VERSION ""

NS_ :

BS_:

BU_:

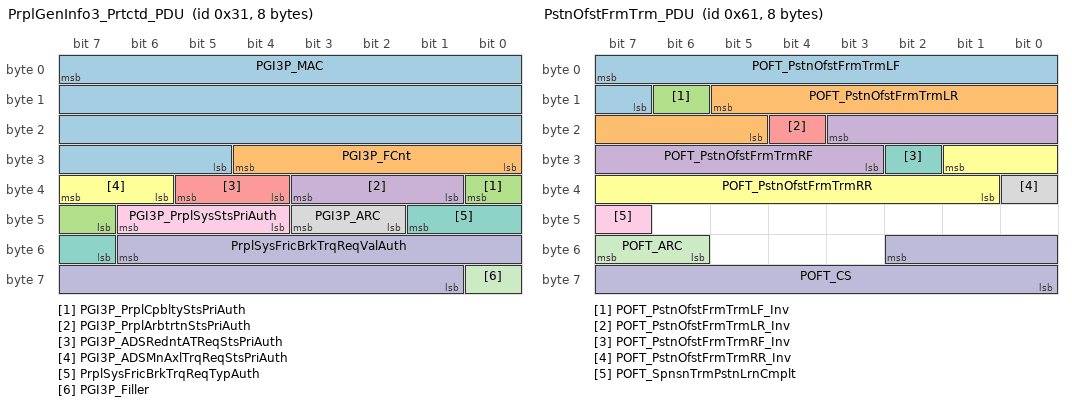
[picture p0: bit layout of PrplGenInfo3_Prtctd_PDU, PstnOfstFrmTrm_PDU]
BO_ 49 PrplGenInfo3_Prtctd_PDU: 8 Vector__XXX
 SG_ PGI3P_MAC : 7|27@0+ (1,0) [0|1.34218e+008] "" ADIMa,ADIMb,EBCM
 SG_ PGI3P_FCnt : 28|5@0+ (1,0) [0|31] "" ADIMa,ADIMb,EBCM
 SG_ PGI3P_PrplCpbltyStsPriAuth : 32|2@0+ (1,0) [0|3] "" ADIMa,ADIMb,EBCM
 SG_ PGI3P_PrplArbtrtnStsPriAuth : 35|3@0+ (1,0) [0|3] "" ADIMa,ADIMb,EBCM
 SG_ PGI3P_ADSRedntATReqStsPriAuth : 37|2@0+ (1,0) [0|3] "" ADIMa,ADIMb,EBCM
 SG_ PGI3P_ADSMnAxlTrqReqStsPriAuth : 39|2@0+ (1,0) [0|3] "" ADIMa,ADIMb,EBCM
 SG_ PrplSysFricBrkTrqReqTypAuth : 41|3@0+ (1,0) [0|3] "" ADIMa,ADIMb,EBCM
 SG_ PGI3P_ARC : 43|2@0+ (1,0) [0|3] "" ADIMa,ADIMb,EBCM
 SG_ PGI3P_PrplSysStsPriAuth : 46|3@0+ (1,0) [0|6] "" ADIMa,ADIMb,EBCM
 SG_ PrplSysFricBrkTrqReqValAuth : 54|14@0+ (2,-22534) [-22534|10232] "Nm" ADIMa,ADIMb,EBCM
 SG_ PGI3P_Filler : 56|1@0+ (1,0) [0|1] "" ADIMa,ADIMb,EBCM

BO_ 1381 PstClsnInfo_PCSM_PDU: 8 Vector__XXX
 SG_ PstClsnInfo_PCSM : 7|64@0+ (1,0) [0|1.84467e+019] "" BSM,BSM_MH,ECM,ECP_MC,FCM,PCM,ECP_X1

BO_ 1320 PstClsnInfo_Prtctd_PDU: 8 Vector__XXX
 SG_ PCIP_MAC : 7|27@0+ (1,0) [0|1.34218e+008] "" BSM,BSM_MH,ECM,ECP_MC,FCM,PCM,ECP_X1
 SG_ PCIP_FCnt : 28|5@0+ (1,0) [0|31] "" BSM,BSM_MH,ECM,ECP_MC,FCM,PCM,ECP_X1
 SG_ PCIP_HzrdLgtsOnReqdAuth : 32|1@0+ (1,0) [0|1] "" BSM,BSM_MH,ECM,ECP_MC,FCM,PCM,ECP_X1
 SG_ PCIP_HybVehHiVltgDsblReqdAuth : 33|1@0+ (1,0) [0|1] "" BSM,BSM_MH,ECM,ECP_MC,FCM,PCM,ECP_X1
 SG_ PCIP_HVCrshImpSnsSysDsbldAuth : 34|1@0+ (1,0) [0|1] "" BSM,BSM_MH,ECM,ECP_MC,FCM,PCM,ECP_X1
 SG_ PCIP_HVACBlwDsblReqdAuth : 35|1@0+ (1,0) [0|1] "" BSM,BSM_MH,ECM,ECP_MC,FCM,PCM,ECP_X1
 SG_ PCIP_FuelCutOffReqdAuth : 36|1@0+ (1,0) [0|1] "" BSM,BSM_MH,ECM,ECP_MC,FCM,PCM,ECP_X1
 SG_ PCIP_DrUnlckReqdAuth : 37|1@0+ (1,0) [0|1] "" BSM,BSM_MH,ECM,ECP_MC,FCM,PCM,ECP_X1
 SG_ PCIP_CruzCtlDsblReqdAuth : 38|1@0+ (1,0) [0|1] "" BSM,BSM_MH,ECM,ECP_MC,FCM,PCM,ECP_X1
 SG_ PCIP_BrkActReqdAuth : 39|1@0+ (1,0) [0|1] "" BSM,BSM_MH,ECM,ECP_MC,FCM,PCM,ECP_X1
 SG_ PCIP_NtfnEvntCntAuth : 44|8@0+ (1,0) [0|255] "" BSM,BSM_MH,ECM,ECP_MC,FCM,PCM,ECP_X1
 SG_ PCIP_NftnFrtImpPrtnsrSevAchAuth : 45|1@0+ (1,0) [0|1] "" BSM,BSM_MH,ECM,ECP_MC,FCM,PCM,ECP_X1
 SG_ PCIP_MemStRclDsblReqdAuth : 46|1@0+ (1,0) [0|1] "" BSM,BSM_MH,ECM,ECP_MC,FCM,PCM,ECP_X1
 SG_ PCIP_IntrLgtOnReqdAuth : 47|1@0+ (1,0) [0|1] "" BSM,BSM_MH,ECM,ECP_MC,FCM,PCM,ECP_X1
 SG_ PCIP_NtfnLtSdSevAchvdAuth : 48|1@0+ (1,0) [0|1] "" BSM,BSM_MH,ECM,ECP_MC,FCM,PCM,ECP_X1
 SG_ PCIP_NtfnFrtImpStg2SevAchvdAuth : 49|1@0+ (1,0) [0|1] "" BSM,BSM_MH,ECM,ECP_MC,FCM,PCM,ECP_X1
 SG_ PCIP_NtfnFrtImpStg1SevAchvdAuth : 50|1@0+ (1,0) [0|1] "" BSM,BSM_MH,ECM,ECP_MC,FCM,PCM,ECP_X1
 SG_ PCIP_NtfnEvntStsAuth : 52|2@0+ (1,0) [0|2] "" BSM,BSM_MH,ECM,ECP_MC,FCM,LIB1,PCM,ECP_X1
 SG_ PCIP_Filler : 56|1@0+ (1,0) [0|1] "" BSM,BSM_MH,ECM,ECP_MC,FCM,PCM,ECP_X1
 SG_ PCIP_ARC : 58|2@0+ (1,0) [0|3] "" BSM,BSM_MH,ECM,ECP_MC,FCM,PCM,ECP_X1
 SG_ PCIP_eCallReqdAuth : 59|1@0+ (1,0) [0|1] "" BSM,BSM_MH,ECM,ECP_MC,FCM,PCM,ECP_X1
 SG_ PCIP_NtfnRtSdSevAchvdAuth : 60|1@0+ (1,0) [0|1] "" BSM,BSM_MH,ECM,ECP_MC,FCM,PCM,ECP_X1
 SG_ PCIP_NtfnRrImpSevAchvdAuth : 61|1@0+ (1,0) [0|1] "" BSM,BSM_MH,ECM,ECP_MC,FCM,PCM,ECP_X1
 SG_ PCIP_NtfnRlOvrSevAchvdAuth : 62|1@0+ (1,0) [0|1] "" BSM,BSM_MH,ECM,ECP_MC,FCM,PCM,ECP_X1
 SG_ PCIP_NtfnPedtrnPrtctnSevAchAuth : 63|1@0+ (1,0) [0|1] "" BSM,BSM_MH,ECM,ECP_MC,FCM,PCM,ECP_X1

BO_ 97 PstnOfstFrmTrm_PDU: 8 Vector__XXX
 SG_ POFT_PstnOfstFrmTrmLF : 7|9@0- (1,0) [-256|255] "mm" ADIMa,ADIMb,AHL_AFL,EPS,EPSb,ECP_E
 SG_ POFT_PstnOfstFrmTrmLR : 13|9@0- (1,0) [-256|255] "mm" ADIMa,ADIMb,AHL_AFL,EPS,EPSb,ECP_E
 SG_ POFT_PstnOfstFrmTrmLF_Inv : 14|1@0+ (1,0) [0|1] "" ADIMa,ADIMb,AHL_AFL,EPS,EPSb,ECP_E
 SG_ POFT_PstnOfstFrmTrmRF : 19|9@0- (1,0) [-256|255] "mm" ADIMa,ADIMb,AHL_AFL,EPS,EPSb,ECP_E
 SG_ POFT_PstnOfstFrmTrmLR_Inv : 20|1@0+ (1,0) [0|1] "" ADIMa,ADIMb,AHL_AFL,EPS,EPSb,ECP_E
 SG_ POFT_PstnOfstFrmTrmRR : 25|9@0- (1,0) [-256|255] "mm" ADIMa,ADIMb,AHL_AFL,EPS,EPSb,ECP_E
 SG_ POFT_PstnOfstFrmTrmRF_Inv : 26|1@0+ (1,0) [0|1] "" ADIMa,ADIMb,AHL_AFL,EPS,EPSb,ECP_E
 SG_ POFT_PstnOfstFrmTrmRR_Inv : 32|1@0+ (1,0) [0|1] "" ADIMa,ADIMb,AHL_AFL,EPS,EPSb,ECP_E
 SG_ POFT_SpnsnTrmPstnLrnCmplt : 47|1@0+ (1,0) [0|1] "" ADIMa,ADIMb,AHL_AFL,EPS,EPSb,ECP_E
 SG_ POFT_CS : 50|11@0+ (1,0) [0|2047] "" ADIMa,ADIMb,EPS,EPSb,ECP_E
 SG_ POFT_ARC : 55|2@0+ (1,0) [0|3] "" ADIMa,ADIMb,EPS,EPSb,ECP_E

BO_ 1399 PwrStrgInfo_PCSM_PDU: 8 Vector__XXX
 SG_ PwrStrgInfo_PCSM : 7|64@0+ (1,0) [0|1.84467e+019] "" Vector__XXX

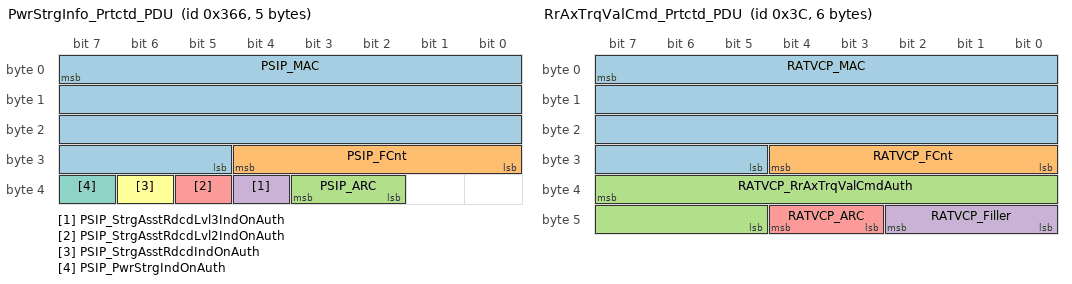
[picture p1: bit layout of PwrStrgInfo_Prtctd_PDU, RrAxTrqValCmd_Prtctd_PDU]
BO_ 870 PwrStrgInfo_Prtctd_PDU: 5 Vector__XXX
 SG_ PSIP_MAC : 7|27@0+ (1,0) [0|1.34218e+008] "" Vector__XXX
 SG_ PSIP_FCnt : 28|5@0+ (1,0) [0|31] "" Vector__XXX
 SG_ PSIP_ARC : 35|2@0+ (1,0) [0|3] "" Vector__XXX
 SG_ PSIP_StrgAsstRdcdLvl3IndOnAuth : 36|1@0+ (1,0) [0|1] "" Vector__XXX
 SG_ PSIP_StrgAsstRdcdLvl2IndOnAuth : 37|1@0+ (1,0) [0|1] "" Vector__XXX
 SG_ PSIP_StrgAsstRdcdIndOnAuth : 38|1@0+ (1,0) [0|1] "" Vector__XXX
 SG_ PSIP_PwrStrgIndOnAuth : 39|1@0+ (1,0) [0|1] "" Vector__XXX

BO_ 2147745823 Message1039_PDU: 1 Vector__XXX
 SG_ Sig5023 : 7|1@0+ (1,0) [0|1] "" CGM

BO_ 912 RrAxTrqValCmd_PCSM_PDU: 8 Vector__XXX
 SG_ RrAxTrqValCmd_PCSM : 7|64@0+ (1,0) [0|1.84467e+019] "" DCM,PCM,TCM

BO_ 60 RrAxTrqValCmd_Prtctd_PDU: 6 Vector__XXX
 SG_ RATVCP_MAC : 7|27@0+ (1,0) [0|1.34218e+008] "" DCM,PCM,TCM
 SG_ RATVCP_FCnt : 28|5@0+ (1,0) [0|31] "" DCM,PCM,TCM
 SG_ RATVCP_RrAxTrqValCmdAuth : 39|11@0+ (5,-5120) [-5120|5115] "Nm" DCM,PCM,TCM
 SG_ RATVCP_Filler : 42|3@0+ (1,0) [0|7] "" DCM,PCM,TCM
 SG_ RATVCP_ARC : 44|2@0+ (1,0) [0|3] "" DCM,PCM,TCM

BO_ 1380 SecAxlTrqCplRqTy_PCSM_PDU: 8 Vector__XXX
 SG_ SecAxlTrqCplRqTy_PCSM : 7|64@0+ (1,0) [0|1.84467e+019] "" RDCM,TCCM

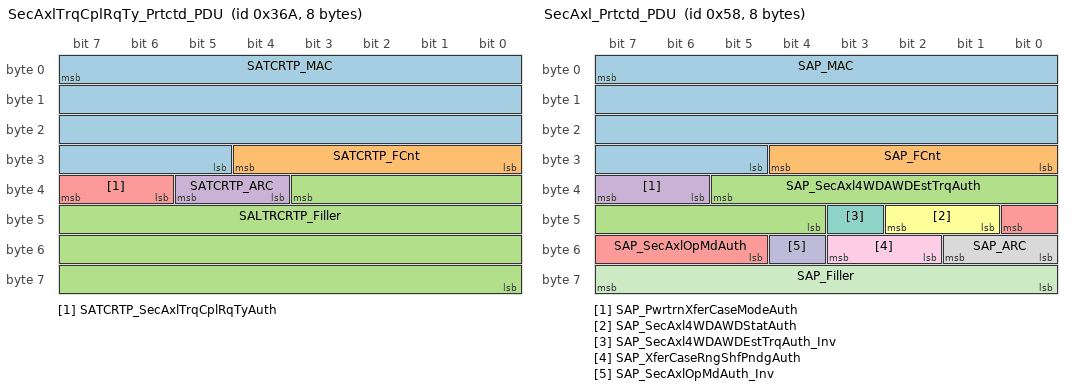
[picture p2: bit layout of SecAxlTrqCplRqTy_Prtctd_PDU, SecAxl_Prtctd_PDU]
BO_ 874 SecAxlTrqCplRqTy_Prtctd_PDU: 8 Vector__XXX
 SG_ SATCRTP_MAC : 7|27@0+ (1,0) [0|1.34218e+008] "" RDCM,TCCM
 SG_ SATCRTP_FCnt : 28|5@0+ (1,0) [0|31] "" RDCM,TCCM
 SG_ SALTRCRTP_Filler : 35|28@0+ (1,0) [0|2.68435e+008] "" RDCM,TCCM
 SG_ SATCRTP_ARC : 37|2@0+ (1,0) [0|3] "" RDCM,TCCM
 SG_ SATCRTP_SecAxlTrqCplRqTyAuth : 39|2@0+ (1,0) [0|3] "" RDCM,TCCM

BO_ 911 SecAxl_PCSM_PDU: 8 Vector__XXX
 SG_ SecAxl_PCSM : 7|64@0+ (1,0) [0|1.84467e+019] "" ACP2_MCU,CGM,EBCM,ECM,EOCM,EOCM_HC_Superset,FCM,PCM

BO_ 88 SecAxl_Prtctd_PDU: 8 Vector__XXX
 SG_ SAP_MAC : 7|27@0+ (1,0) [0|1.34218e+008] "" ACP2_MCU,CGM,EBCM,ECM,EOCM,EOCM_HC_Superset,FCM,PCM
 SG_ SAP_FCnt : 28|5@0+ (1,0) [0|31] "" ACP2_MCU,CGM,EBCM,ECM,EOCM,EOCM_HC_Superset,FCM,PCM
 SG_ SAP_SecAxl4WDAWDEstTrqAuth : 37|10@0+ (10,0) [0|10230] "Nm" ACP2_MCU,ADIMa,ADIMb,CGM,DCM,EBCM,ECM,EOCM,EOCM_HC_Superset,FCM,PCM,ECP_E
 SG_ SAP_PwrtrnXferCaseModeAuth : 39|2@0+ (1,0) [0|3] "" ACP2_MCU,CGM,EBCM,ECM,EOCM,EOCM_HC_Superset,FCM,PCM
 SG_ SAP_SecAxlOpMdAuth : 40|4@0+ (1,0) [0|9] "" ACP2_MCU,ADIMa,ADIMb,CGM,EBCM,ECM,EOCM,EOCM_HC_Superset,FCM,E44,PCM,ECP_E
 SG_ SAP_SecAxl4WDAWDStatAuth : 42|2@0+ (1,0) [0|3] "" ACP2_MCU,ADIMa,ADIMb,CGM,EBCM,ECM,EOCM,EOCM_HC_Superset,FCM,PCM,ECP_E
 SG_ SAP_SecAxl4WDAWDEstTrqAuth_Inv : 43|1@0+ (1,0) [0|1] "" ACP2_MCU,ADIMa,ADIMb,CGM,DCM,EBCM,ECM,EOCM,EOCM_HC_Superset,FCM,PCM,ECP_E
 SG_ SAP_ARC : 49|2@0+ (1,0) [0|3] "" ACP2_MCU,CGM,EBCM,ECM,EOCM,EOCM_HC_Superset,FCM,PCM
 SG_ SAP_XferCaseRngShfPndgAuth : 51|2@0+ (1,0) [0|3] "" ACP2_MCU,CGM,EBCM,ECM,EOCM,EOCM_HC_Superset,FCM,PCM
 SG_ SAP_SecAxlOpMdAuth_Inv : 52|1@0+ (1,0) [0|1] "" ACP2_MCU,ADIMa,ADIMb,CGM,EBCM,ECM,EOCM,EOCM_HC_Superset,FCM,E44,PCM,ECP_E
 SG_ SAP_Filler : 63|8@0+ (1,0) [0|255] "" ACP2_MCU,CGM,EBCM,ECM,EOCM,EOCM_HC_Superset,FCM,PCM

BO_ 1379 SemiAtvDmpgSysVhTpSpdLim_PCSM_PD: 8 Vector__XXX
 SG_ SemiAtvDmpgSysVhTpSpdLim_PCSM : 7|64@0+ (1,0) [0|1.84467e+019] "" ECM,PCM,ECP_E

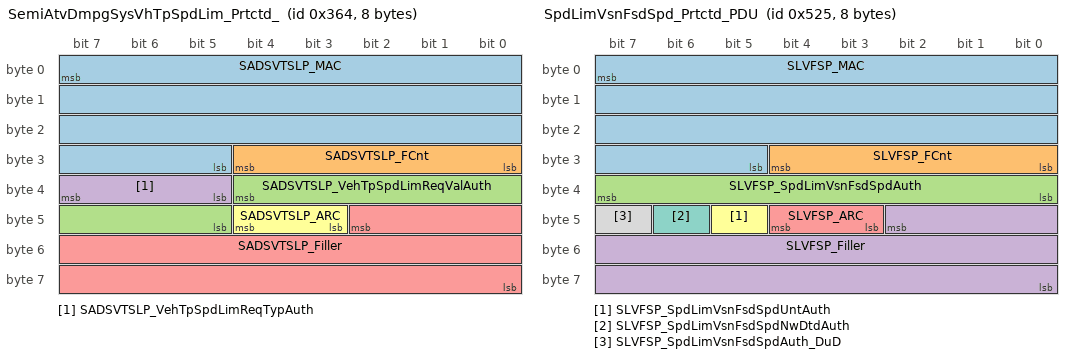
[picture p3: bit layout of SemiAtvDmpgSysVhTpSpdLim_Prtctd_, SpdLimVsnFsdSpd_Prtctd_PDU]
BO_ 868 SemiAtvDmpgSysVhTpSpdLim_Prtctd_: 8 Vector__XXX
 SG_ SADSVTSLP_MAC : 7|27@0+ (1,0) [0|1.34218e+008] "" ECM,PCM,ECP_E
 SG_ SADSVTSLP_FCnt : 28|5@0+ (1,0) [0|31] "" ECM,PCM,ECP_E
 SG_ SADSVTSLP_VehTpSpdLimReqValAuth : 36|8@0+ (2,0) [0|510] "kph" ECM,PCM,ECP_E
 SG_ SADSVTSLP_VehTpSpdLimReqTypAuth : 39|3@0+ (1,0) [0|6] "" ECM,PCM,ECP_E
 SG_ SADSVTSLP_Filler : 42|19@0+ (1,0) [0|524287] "" ECM,PCM,ECP_E
 SG_ SADSVTSLP_ARC : 44|2@0+ (1,0) [0|3] "" ECM,PCM,ECP_E

BO_ 1317 SpdLimVsnFsdSpd_Prtctd_PDU: 8 Vector__XXX
 SG_ SLVFSP_MAC : 7|27@0+ (1,0) [0|1.34218e+008] "" Vector__XXX
 SG_ SLVFSP_FCnt : 28|5@0+ (1,0) [0|31] "" Vector__XXX
 SG_ SLVFSP_SpdLimVsnFsdSpdAuth : 39|8@0+ (1,0) [0|255] "" CGM,ECM,PCM,ECP_E
 SG_ SLVFSP_Filler : 42|19@0+ (1,0) [0|524287] "" Vector__XXX
 SG_ SLVFSP_ARC : 44|2@0+ (1,0) [0|3] "" Vector__XXX
 SG_ SLVFSP_SpdLimVsnFsdSpdUntAuth : 45|1@0+ (1,0) [0|1] "" CGM,ECM,PCM,ECP_E
 SG_ SLVFSP_SpdLimVsnFsdSpdNwDtdAuth : 46|1@0+ (1,0) [0|1] "" CGM,ECM,PCM,ECP_E
 SG_ SLVFSP_SpdLimVsnFsdSpdAuth_DuD : 47|1@0+ (1,0) [0|1] "" CGM,ECM,PCM,ECP_E

BO_ 1378 SpnsnGenInfo2_PCSM_PDU: 8 Vector__XXX
 SG_ SpnsnGenInfo2_PCSM : 7|64@0+ (1,0) [0|1.84467e+019] "" FCM

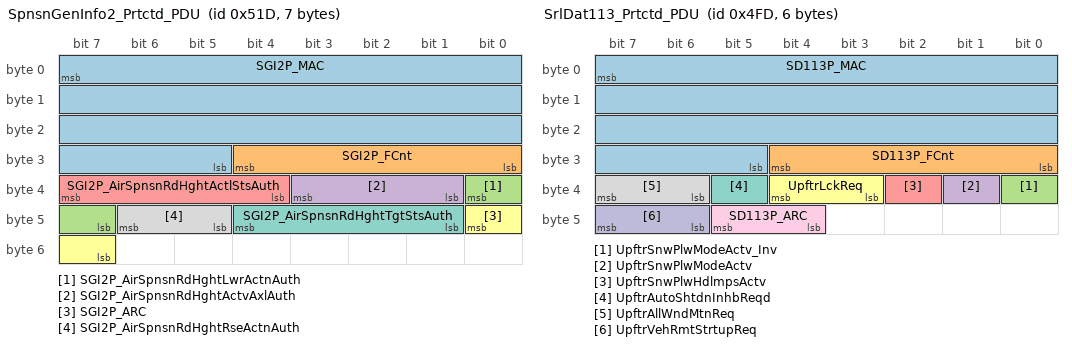
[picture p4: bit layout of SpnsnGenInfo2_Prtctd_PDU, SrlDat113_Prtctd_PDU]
BO_ 1309 SpnsnGenInfo2_Prtctd_PDU: 7 Vector__XXX
 SG_ SGI2P_MAC : 7|27@0+ (1,0) [0|1.34218e+008] "" FCM
 SG_ SGI2P_FCnt : 28|5@0+ (1,0) [0|31] "" FCM
 SG_ SGI2P_AirSpnsnRdHghtLwrActnAuth : 32|2@0+ (1,0) [0|3] "" FCM
 SG_ SGI2P_AirSpnsnRdHghtActvAxlAuth : 35|3@0+ (1,0) [0|4] "" FCM
 SG_ SGI2P_AirSpnsnRdHghtActlStsAuth : 39|4@0+ (1,0) [0|9] "" FCM,E44
 SG_ SGI2P_ARC : 40|2@0+ (1,0) [0|3] "" FCM
 SG_ SGI2P_AirSpnsnRdHghtTgtStsAuth : 44|4@0+ (1,0) [0|9] "" FCM,E44
 SG_ SGI2P_AirSpnsnRdHghtRseActnAuth : 46|2@0+ (1,0) [0|3] "" FCM

BO_ 1327 SrlDat113_PCSM_PDU: 8 Vector__XXX
 SG_ SrlDat113_PCSM : 7|64@0+ (1,0) [0|1.84467e+019] "" ACP2_MCU,ECM,EOCM,EOCM_HC_Superset,FCM

BO_ 1277 SrlDat113_Prtctd_PDU: 6 Vector__XXX
 SG_ SD113P_MAC : 7|27@0+ (1,0) [0|1.34218e+008] "" ACP2_MCU,ECM,EOCM,EOCM_HC_Superset,FCM
 SG_ SD113P_FCnt : 28|5@0+ (1,0) [0|31] "" ACP2_MCU,ECM,EOCM,EOCM_HC_Superset,FCM
 SG_ UpftrSnwPlwModeActv_Inv : 32|1@0+ (1,0) [0|1] "" ACP2_MCU,ECM,EOCM,EOCM_HC_Superset,FCM
 SG_ UpftrSnwPlwModeActv : 33|1@0+ (1,0) [0|1] "" ACP2_MCU,ECM,EOCM,EOCM_HC_Superset,FCM
 SG_ UpftrSnwPlwHdlmpsActv : 34|1@0+ (1,0) [0|1] "" ACP2_MCU,ECM,EOCM,EOCM_HC_Superset,FCM
 SG_ UpftrLckReq : 36|2@0+ (1,0) [0|2] "" ACP2_MCU,ECM,EOCM,EOCM_HC_Superset,FCM
 SG_ UpftrAutoShtdnInhbReqd : 37|1@0+ (1,0) [0|1] "" ACP2_MCU,ECM,EOCM,EOCM_HC_Superset,FCM
 SG_ UpftrAllWndMtnReq : 39|2@0+ (1,0) [0|3] "" ACP2_MCU,ECM,EOCM,EOCM_HC_Superset,FCM
 SG_ SD113P_ARC : 45|2@0+ (1,0) [0|3] "" ACP2_MCU,ECM,EOCM,EOCM_HC_Superset,FCM
 SG_ UpftrVehRmtStrtupReq : 47|2@0+ (1,0) [0|2] "" ACP2_MCU,ECM,EOCM,EOCM_HC_Superset,FCM

BO_ 910 SrlDat11_PCSM_PDU: 8 Vector__XXX
 SG_ SrlDat11_PCSM : 7|64@0+ (1,0) [0|1.84467e+019] "" ECP_E,ECP_S,ECP_S2,ECP_X1

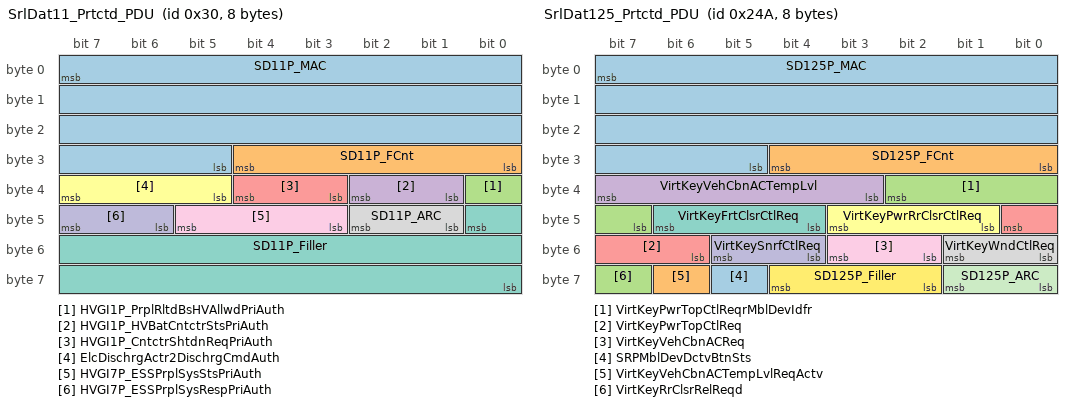
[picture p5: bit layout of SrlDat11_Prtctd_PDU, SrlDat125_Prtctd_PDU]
BO_ 48 SrlDat11_Prtctd_PDU: 8 Vector__XXX
 SG_ SD11P_MAC : 7|27@0+ (1,0) [0|1.34218e+008] "" ECP_E,ECP_S,ECP_S2,ECP_X1
 SG_ SD11P_FCnt : 28|5@0+ (1,0) [0|31] "" ECP_E,ECP_S,ECP_S2,ECP_X1
 SG_ HVGI1P_PrplRltdBsHVAllwdPriAuth : 32|1@0+ (1,0) [0|1] "" ECP_E,ECP_S,ECP_S2,ECP_X1
 SG_ HVGI1P_HVBatCntctrStsPriAuth : 34|2@0+ (1,0) [0|2] "" ECP_E,ECP_S,ECP_S2,ECP_X1
 SG_ HVGI1P_CntctrShtdnReqPriAuth : 36|2@0+ (1,0) [0|3] "" VDM,ECP_E,ECP_S,ECP_S2,ECP_X1
 SG_ ElcDischrgActr2DischrgCmdAuth : 39|3@0+ (1,0) [0|3] "" ECP_E,ECP_S,ECP_S2,ECP_X1
 SG_ SD11P_Filler : 40|17@0+ (1,0) [0|131071] "" ECP_E,ECP_S,ECP_S2,ECP_X1
 SG_ SD11P_ARC : 42|2@0+ (1,0) [0|3] "" ECP_E,ECP_S,ECP_S2,ECP_X1
 SG_ HVGI7P_ESSPrplSysStsPriAuth : 45|3@0+ (1,0) [0|5] "" ECP_E,ECP_S,ECP_S2,ECP_X1
 SG_ HVGI7P_ESSPrplSysRespPriAuth : 47|2@0+ (1,0) [0|3] "" ECP_E,ECP_S,ECP_S2,ECP_X1

BO_ 1152 SrlDat124_PCSM_PDU: 8 Vector__XXX
 SG_ SrlDat124_PCSM : 7|64@0+ (1,0) [0|1.84467e+019] "" ACP2_MCU,EOCM,EOCM_HC_Superset

BO_ 1149 SrlDat124_Prtctd_PDU: 8 Vector__XXX
 SG_ SD124P_MAC : 7|27@0+ (1,0) [0|1.34218e+008] "" ACP2_MCU,EOCM,EOCM_HC_Superset
 SG_ SD124P_FCnt : 28|5@0+ (1,0) [0|31] "" ACP2_MCU,EOCM,EOCM_HC_Superset
 SG_ VirtKeyAllDrLckReqd : 32|1@0+ (1,0) [0|1] "" ACP2_MCU,EOCM,EOCM_HC_Superset
 SG_ VirtKeyPncReq : 34|2@0+ (1,0) [0|2] "" ACP2_MCU,EOCM,EOCM_HC_Superset
 SG_ VirtKeyFobAvlReq : 36|2@0+ (1,0) [0|2] "" ACP2_MCU,EOCM,EOCM_HC_Superset
 SG_ VirtKeyRmtLctrReq : 39|3@0+ (1,0) [0|4] "" ACP2_MCU,EOCM,EOCM_HC_Superset
 SG_ SRPCrsFrtInSftBtnMblDevSts : 40|1@0+ (1,0) [0|1] "" ACP2_MCU,EOCM,EOCM_HC_Superset
 SG_ SRPCrsBkInSftBtnMblDevSts : 41|1@0+ (1,0) [0|1] "" ACP2_MCU,EOCM,EOCM_HC_Superset
 SG_ VirtKeyRrClsrUnlckReqd : 42|1@0+ (1,0) [0|1] "" ACP2_MCU,EOCM,EOCM_HC_Superset
 SG_ VirtKeyRrClsrLckReqd : 43|1@0+ (1,0) [0|1] "" ACP2_MCU,EOCM,EOCM_HC_Superset
 SG_ VirtKeyFrtClsrUnlckReqd : 44|1@0+ (1,0) [0|1] "" ACP2_MCU,EOCM,EOCM_HC_Superset
 SG_ VirtKeyFrtClsrLckReqd : 45|1@0+ (1,0) [0|1] "" ACP2_MCU,EOCM,EOCM_HC_Superset
 SG_ VirtKeyDrvrDrUnlckReqd : 46|1@0+ (1,0) [0|1] "" ACP2_MCU,EOCM,EOCM_HC_Superset
 SG_ VirtKeyAllDrUnlckReqd : 47|1@0+ (1,0) [0|1] "" ACP2_MCU,EOCM,EOCM_HC_Superset
 SG_ SD124P_Filler : 50|9@0+ (1,0) [0|511] "" ACP2_MCU,EOCM,EOCM_HC_Superset
 SG_ SRPSrchingSftBtnMblDevSts : 51|1@0+ (1,0) [0|1] "" ACP2_MCU,EOCM,EOCM_HC_Superset
 SG_ SRPRtSftBtnMblDevSts : 52|1@0+ (1,0) [0|1] "" ACP2_MCU,EOCM,EOCM_HC_Superset
 SG_ SRPPrlllPrkSftBtnMblDevSts : 53|1@0+ (1,0) [0|1] "" ACP2_MCU,EOCM,EOCM_HC_Superset
 SG_ SRPLtSftBtnMblDevSts : 54|1@0+ (1,0) [0|1] "" ACP2_MCU,EOCM,EOCM_HC_Superset
 SG_ SRPExtPrkSftBtnMblDevSts : 55|1@0+ (1,0) [0|1] "" ACP2_MCU,EOCM,EOCM_HC_Superset
 SG_ SD124P_ARC : 57|2@0+ (1,0) [0|3] "" ACP2_MCU,EOCM,EOCM_HC_Superset

BO_ 972 SrlDat125_PCSM_PDU: 8 Vector__XXX
 SG_ SrlDat125_PCSM : 7|64@0+ (1,0) [0|1.84467e+019] "" ACP2_MCU,EOCM,EOCM_HC_Superset

BO_ 586 SrlDat125_Prtctd_PDU: 8 Vector__XXX
 SG_ SD125P_MAC : 7|27@0+ (1,0) [0|1.34218e+008] "" ACP2_MCU,EOCM,EOCM_HC_Superset
 SG_ SD125P_FCnt : 28|5@0+ (1,0) [0|31] "" ACP2_MCU,EOCM,EOCM_HC_Superset
 SG_ VirtKeyPwrTopCtlReqrMblDevIdfr : 34|4@0+ (1,0) [0|15] "" ACP2_MCU,EOCM,EOCM_HC_Superset
 SG_ VirtKeyVehCbnACTempLvl : 39|5@0+ (0.5,16) [16|31.5] "Deg C" ACP2_MCU,EOCM,EOCM_HC_Superset
 SG_ VirtKeyPwrTopCtlReq : 40|3@0+ (1,0) [0|4] "" ACP2_MCU,EOCM,EOCM_HC_Superset
 SG_ VirtKeyPwrRrClsrCtlReq : 43|3@0+ (1,0) [0|4] "" ACP2_MCU,EOCM,EOCM_HC_Superset
 SG_ VirtKeyFrtClsrCtlReq : 46|3@0+ (1,0) [0|5] "" ACP2_MCU,EOCM,EOCM_HC_Superset
 SG_ VirtKeyWndCtlReq : 49|2@0+ (1,0) [0|3] "" ACP2_MCU,EOCM,EOCM_HC_Superset
 SG_ VirtKeyVehCbnACReq : 51|2@0+ (1,0) [0|2] "" ACP2_MCU,EOCM,EOCM_HC_Superset
 SG_ VirtKeySnrfCtlReq : 53|2@0+ (1,0) [0|3] "" ACP2_MCU,EOCM,EOCM_HC_Superset
 SG_ SD125P_ARC : 57|2@0+ (1,0) [0|3] "Counts" ACP2_MCU,EOCM,EOCM_HC_Superset
 SG_ SD125P_Filler : 60|3@0+ (1,0) [0|7] "" ACP2_MCU,EOCM,EOCM_HC_Superset
 SG_ SRPMblDevDctvBtnSts : 61|1@0+ (1,0) [0|1] "" ACP2_MCU,EOCM,EOCM_HC_Superset
 SG_ VirtKeyVehCbnACTempLvlReqActv : 62|1@0+ (1,0) [0|1] "" ACP2_MCU,EOCM,EOCM_HC_Superset
 SG_ VirtKeyRrClsrRelReqd : 63|1@0+ (1,0) [0|1] "" ACP2_MCU,EOCM,EOCM_HC_Superset

BO_ 967 SrlDat133_PCSM_PDU: 8 Vector__XXX
 SG_ SrlDat133_PCSM : 7|64@0+ (1,0) [0|1.84467e+019] "" ECP_E

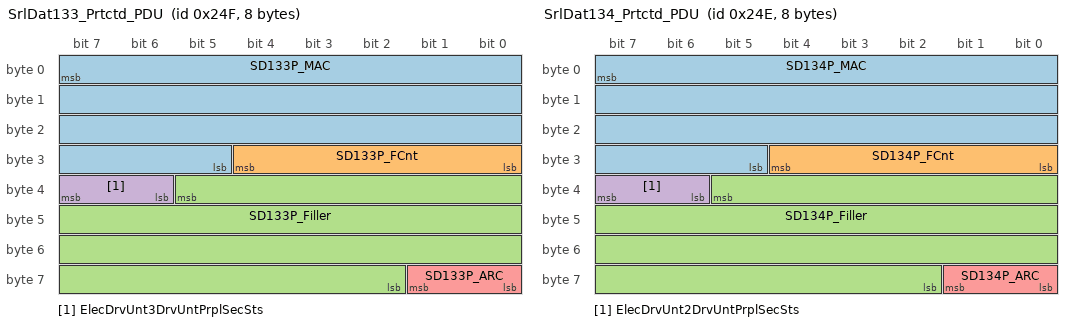
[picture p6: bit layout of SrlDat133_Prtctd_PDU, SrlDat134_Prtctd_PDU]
BO_ 591 SrlDat133_Prtctd_PDU: 8 Vector__XXX
 SG_ SD133P_MAC : 7|27@0+ (1,0) [0|1.34218e+008] "" ECP_E
 SG_ SD133P_FCnt : 28|5@0+ (1,0) [0|31] "" ECP_E
 SG_ SD133P_Filler : 37|28@0+ (1,0) [0|2.68435e+008] "" ECP_E
 SG_ ElecDrvUnt3DrvUntPrplSecSts : 39|2@0+ (1,0) [0|2] "" ECP_E
 SG_ SD133P_ARC : 57|2@0+ (1,0) [0|3] "" ECP_E

BO_ 969 SrlDat134_PCSM_PDU: 8 Vector__XXX
 SG_ SrlDat134_PCSM : 7|64@0+ (1,0) [0|1.84467e+019] "" ECP_E

BO_ 590 SrlDat134_Prtctd_PDU: 8 Vector__XXX
 SG_ SD134P_MAC : 7|27@0+ (1,0) [0|1.34218e+008] "" ECP_E
 SG_ SD134P_FCnt : 28|5@0+ (1,0) [0|31] "" ECP_E
 SG_ SD134P_Filler : 37|28@0+ (1,0) [0|2.68435e+008] "" ECP_E
 SG_ ElecDrvUnt2DrvUntPrplSecSts : 39|2@0+ (1,0) [0|2] "" ECP_E
 SG_ SD134P_ARC : 57|2@0+ (1,0) [0|3] "" ECP_E

BO_ 970 SrlDat135_PCSM_PDU: 8 Vector__XXX
 SG_ SrlDat135_PCSM : 7|64@0+ (1,0) [0|1.84467e+019] "" ECP_S,ECP_S2

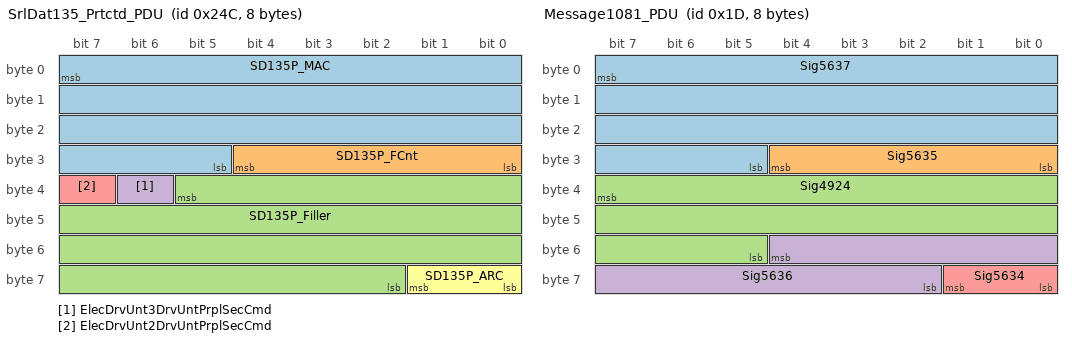
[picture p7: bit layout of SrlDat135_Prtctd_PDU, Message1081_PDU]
BO_ 588 SrlDat135_Prtctd_PDU: 8 Vector__XXX
 SG_ SD135P_MAC : 7|27@0+ (1,0) [0|1.34218e+008] "" ECP_S,ECP_S2
 SG_ SD135P_FCnt : 28|5@0+ (1,0) [0|31] "" ECP_S,ECP_S2
 SG_ SD135P_Filler : 37|28@0+ (1,0) [0|2.68435e+008] "" ECP_S,ECP_S2
 SG_ ElecDrvUnt3DrvUntPrplSecCmd : 38|1@0+ (1,0) [0|1] "" ECP_S,ECP_S2
 SG_ ElecDrvUnt2DrvUntPrplSecCmd : 39|1@0+ (1,0) [0|1] "" ECP_S,ECP_S2
 SG_ SD135P_ARC : 57|2@0+ (1,0) [0|3] "" ECP_S,ECP_S2

BO_ 740 Message1080_PDU: 8 Vector__XXX
 SG_ Sig6844 : 7|64@0+ (1,0) [0|1.84467e+019] "" ECM

BO_ 29 Message1081_PDU: 8 Vector__XXX
 SG_ Sig5637 : 7|27@0+ (1,0) [0|1.34218e+008] "" ECM
 SG_ Sig5635 : 28|5@0+ (1,0) [0|31] "" ECM
 SG_ Sig4924 : 39|19@0- (0.25,0) [-65536|65535.8] "Nm" ECM
 SG_ Sig5636 : 52|11@0+ (1,0) [0|2047] "" ECM
 SG_ Sig5634 : 57|2@0+ (1,0) [0|3] "" ECM

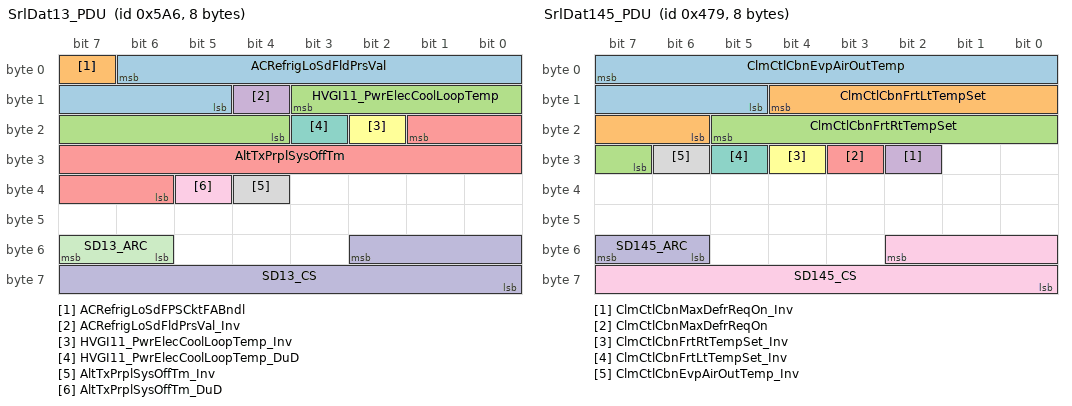
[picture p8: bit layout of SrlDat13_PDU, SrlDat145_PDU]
BO_ 1446 SrlDat13_PDU: 8 Vector__XXX
 SG_ ACRefrigLoSdFldPrsVal : 6|10@0+ (1,0) [0|1023] "KPA" ECM,PCM,ECP_E,ECP_X1
 SG_ ACRefrigLoSdFPSCktFABndl : 7|1@0+ (1,0) [0|1] "" ECM,PCM,ECP_E,ECP_X1
 SG_ HVGI11_PwrElecCoolLoopTemp : 11|8@0+ (1,-40) [-40|215] "Deg C" ECP_E,ECP_X1
 SG_ ACRefrigLoSdFldPrsVal_Inv : 12|1@0+ (1,0) [0|1] "" ECM,PCM,ECP_E,ECP_X1
 SG_ AltTxPrplSysOffTm : 17|12@0+ (0.5,0) [0|2047.5] "min" ECP_E,ECP_X1
 SG_ HVGI11_PwrElecCoolLoopTemp_Inv : 18|1@0+ (1,0) [0|1] "" ECP_E,ECP_X1
 SG_ HVGI11_PwrElecCoolLoopTemp_DuD : 19|1@0+ (1,0) [0|1] "" ECP_E,ECP_X1
 SG_ AltTxPrplSysOffTm_Inv : 36|1@0+ (1,0) [0|1] "" ECP_E,ECP_X1
 SG_ AltTxPrplSysOffTm_DuD : 37|1@0+ (1,0) [0|1] "" ECP_E,ECP_X1
 SG_ SD13_CS : 50|11@0+ (1,0) [0|2047] "" ECP_E,ECP_X1
 SG_ SD13_ARC : 55|2@0+ (1,0) [0|3] "" ECP_E,ECP_X1

BO_ 971 SrlDat141_PCSM_PDU: 8 Vector__XXX
 SG_ SrlDat141_PCSM : 7|64@0+ (1,0) [0|1.84467e+019] "" EBCM,ECM,PCM,ECP_E

BO_ 587 SrlDat141_Prtctd_PDU: 12 Vector__XXX
 SG_ SD141P_MAC : 7|32@0+ (1,0) [0|4.29497e+009] "" EBCM,ECM,PCM,ECP_E
 SG_ SD141P_FCnt : 39|5@0+ (1,0) [0|31] "" EBCM,ECM,PCM,ECP_E
 SG_ SuprRmtPrkPrplSysTrqReq : 47|15@0+ (2,-22534) [-22534|43000] "Nm" EBCM,ECM,PCM,ECP_E
 SG_ SuprRmtPrkBrkTrqReq : 48|14@0+ (2,-22534) [-22534|10232] "Nm" EBCM,ECM,PCM,ECP_E
 SG_ SuprRmtPrkFricBrkTrqReqTyp : 64|2@0+ (1,0) [0|3] "" EBCM,ECM,PCM,ECP_E
 SG_ SuprRmtPrkElecPrkBrkReq : 66|2@0+ (1,0) [0|2] "" EBCM,ECM,PCM,ECP_E
 SG_ SD141P_Filler : 77|20@0+ (1,0) [0|1.04858e+006] "" EBCM,ECM,PCM,ECP_E
 SG_ SuprRmtPrkPrplSysActvnReqd : 78|1@0+ (1,0) [0|1] "" EBCM,ECM,PCM,ECP_E
 SG_ SD141P_ARC : 89|2@0+ (1,0) [0|3] "" EBCM,ECM,PCM,ECP_E

BO_ 1145 SrlDat145_PDU: 8 Vector__XXX
 SG_ ClmCtlCbnEvpAirOutTemp : 7|11@0+ (0.1,-60) [-60|144.7] "Deg C" ECM,PCM
 SG_ ClmCtlCbnFrtLtTempSet : 12|7@0+ (0.5,0) [0|63.5] "Deg C" ECM,PCM
 SG_ ClmCtlCbnFrtRtTempSet : 21|7@0+ (0.5,0) [0|63.5] "Deg C" ECM,PCM
 SG_ ClmCtlCbnMaxDefrReqOn_Inv : 26|1@0+ (1,0) [0|1] "" ECM,PCM
 SG_ ClmCtlCbnMaxDefrReqOn : 27|1@0+ (1,0) [0|1] "" ECM,PCM
 SG_ ClmCtlCbnFrtRtTempSet_Inv : 28|1@0+ (1,0) [0|1] "" ECM,PCM
 SG_ ClmCtlCbnFrtLtTempSet_Inv : 29|1@0+ (1,0) [0|1] "" ECM,PCM
 SG_ ClmCtlCbnEvpAirOutTemp_Inv : 30|1@0+ (1,0) [0|1] "" ECM,PCM
 SG_ SD145_CS : 50|11@0+ (1,0) [0|2047] "" ECM,PCM
 SG_ SD145_ARC : 55|2@0+ (1,0) [0|3] "" ECM,PCM

BO_ 1377 SrlDat14_PCSM_PDU: 8 Vector__XXX
 SG_ SrlDat14_PCSM : 7|64@0+ (1,0) [0|1.84467e+019] "" ACP2_MCU,ARS,VICM,ECM,EOCM,EOCM_HC_Superset,EPS,EPSb,FCM,PCM,RDCM,TCCM,ECP_E

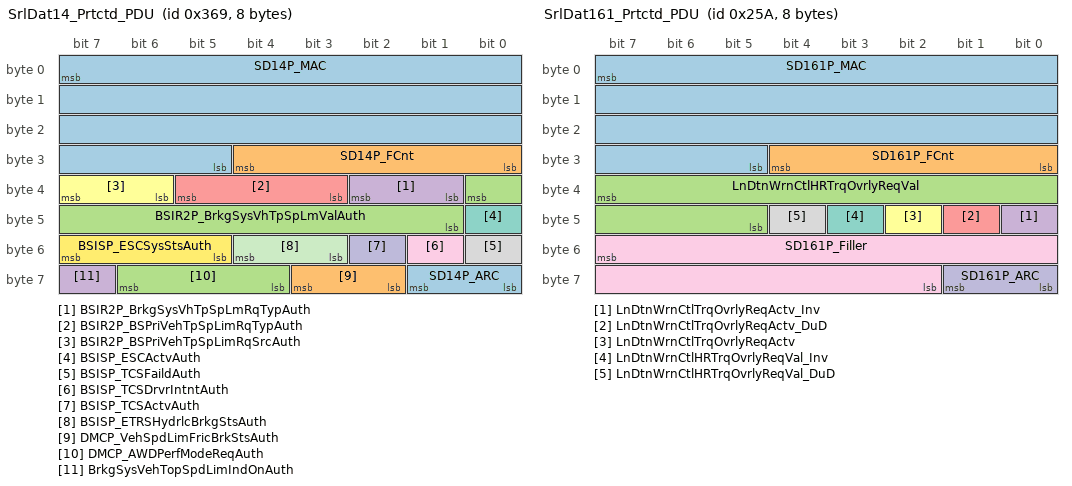
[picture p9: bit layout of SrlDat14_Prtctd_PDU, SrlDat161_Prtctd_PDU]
BO_ 873 SrlDat14_Prtctd_PDU: 8 Vector__XXX
 SG_ SD14P_MAC : 7|27@0+ (1,0) [0|1.34218e+008] "" ACP2_MCU,ARS,VICM,CGM,ECM,EOCM,EOCM_HC_Superset,EPS,EPSb,FCM,PCM,RDCM,TCCM,ECP_E
 SG_ SD14P_FCnt : 28|5@0+ (1,0) [0|31] "" ACP2_MCU,ARS,VICM,CGM,ECM,EOCM,EOCM_HC_Superset,EPS,EPSb,FCM,PCM,RDCM,TCCM,ECP_E
 SG_ BSIR2P_BrkgSysVhTpSpLmValAuth : 32|8@0+ (2,0) [0|510] "kph" ACP2_MCU,ARS,VICM,CGM,ECM,EOCM,EOCM_HC_Superset,EPS,EPSb,FCM,PCM,RDCM,TCCM,ECP_E
 SG_ BSIR2P_BrkgSysVhTpSpLmRqTypAuth : 34|2@0+ (1,0) [0|1] "" ACP2_MCU,ARS,VICM,CGM,ECM,EOCM,EOCM_HC_Superset,EPS,EPSb,FCM,PCM,RDCM,TCCM,ECP_E
 SG_ BSIR2P_BSPriVehTpSpLimRqTypAuth : 37|3@0+ (1,0) [0|6] "" ACP2_MCU,ARS,VICM,CGM,ECM,EOCM,EOCM_HC_Superset,EPS,EPSb,FCM,PCM,RDCM,TCCM,ECP_E
 SG_ BSIR2P_BSPriVehTpSpLimRqSrcAuth : 39|2@0+ (1,0) [0|2] "" ACP2_MCU,ARS,VICM,CGM,ECM,EOCM,EOCM_HC_Superset,EPS,EPSb,FCM,PCM,RDCM,TCCM,ECP_E
 SG_ BSISP_ESCActvAuth : 40|1@0+ (1,0) [0|1] "" ACP2_MCU,ADIMa,ADIMb,AHL_AFL,ARS,VICM,CGM,ECM,EOCM,EOCM_HC_Superset,EPS,EPSb,FCM,E44,PCM,RDCM,TCCM,TCM,VDM,ECP_E,ECP_X1
 SG_ BSISP_TCSFaildAuth : 48|1@0+ (1,0) [0|1] "" ACP2_MCU,ARS,VICM,CGM,ECM,EOCM,EOCM_HC_Superset,EPS,EPSb,FCM,PCM,RDCM,TCCM,TCM,VDM,ECP_E,ECP_S,ECP_S2
 SG_ BSISP_TCSDrvrIntntAuth : 49|1@0+ (1,0) [0|1] "" ACP2_MCU,ARS,VICM,CGM,ECM,EOCM,EOCM_HC_Superset,EPS,EPSb,FCM,PCM,RDCM,TCCM,TCM,ECP_E,ECP_S,ECP_S2
 SG_ BSISP_TCSActvAuth : 50|1@0+ (1,0) [0|1] "" ACP2_MCU,ADIMa,ADIMb,AHL_AFL,ARS,VICM,CGM,ECM,EOCM,EOCM_HC_Superset,EPS,EPSb,FCM,E44,PCM,RDCM,TCCM,TCM,ECP_E,ECP_S2
 SG_ BSISP_ETRSHydrlcBrkgStsAuth : 52|2@0+ (1,0) [0|2] "" ACP2_MCU,ARS,VICM,CGM,ECM,EOCM,EOCM_HC_Superset,EPS,EPSb,FCM,PCM,RDCM,TCCM,TCM,ECP_E
 SG_ BSISP_ESCSysStsAuth : 55|3@0+ (1,0) [0|4] "" ACP2_MCU,AHL_AFL,ARS,VICM,CGM,ECM,EOCM,EOCM_HC_Superset,EPS,EPSb,FCM,E44,PCM,RDCM,TCCM,TCM,VDM,ECP_E
 SG_ SD14P_ARC : 57|2@0+ (1,0) [0|3] "" ACP2_MCU,ARS,VICM,CGM,ECM,EOCM,EOCM_HC_Superset,EPS,EPSb,FCM,PCM,RDCM,TCCM,ECP_E
 SG_ DMCP_VehSpdLimFricBrkStsAuth : 59|2@0+ (1,0) [0|2] "" ACP2_MCU,ARS,VICM,CGM,ECM,EOCM,EOCM_HC_Superset,EPS,EPSb,FCM,PCM,RDCM,TCCM,ECP_E
 SG_ DMCP_AWDPerfModeReqAuth : 62|3@0+ (1,0) [0|7] "" ACP2_MCU,ARS,VICM,CGM,ECM,EOCM,EOCM_HC_Superset,EPS,EPSb,FCM,PCM,RDCM,TCCM,ECP_E
 SG_ BrkgSysVehTopSpdLimIndOnAuth : 63|1@0+ (1,0) [0|1] "" ACP2_MCU,ARS,VICM,CGM,ECM,EOCM,EOCM_HC_Superset,EPS,EPSb,FCM,PCM,RDCM,TCCM,ECP_E

BO_ 694 SrlDat15_PCSM_PDU: 8 Vector__XXX
 SG_ SrlDat15_PCSM : 7|64@0+ (1,0) [0|1.84467e+019] "" ACP2_MCU,ADIMa,ADIMb,VICM,CGM,ECM,EOCM,EOCM_HC_Superset,FCM,PCM,RDCM,TCCM,TCM,ECP_E

BO_ 635 SrlDat15_Prtctd_PDU: 8 Vector__XXX
 SG_ SD15P_MAC : 7|27@0+ (1,0) [0|1.34218e+008] "" ACP2_MCU,ADIMa,ADIMb,VICM,CGM,ECM,EOCM,EOCM_HC_Superset,FCM,PCM,RDCM,TCCM,TCM,ECP_E
 SG_ SD15P_FCnt : 28|5@0+ (1,0) [0|31] "" ACP2_MCU,ADIMa,ADIMb,VICM,CGM,ECM,EOCM,EOCM_HC_Superset,FCM,PCM,RDCM,TCCM,TCM,ECP_E
 SG_ EPBSP_ElecPrkBrkAvlStsAuth : 33|2@0+ (1,0) [0|2] "" ACP2_MCU,ADIMa,ADIMb,VICM,CGM,ECM,EOCM,EOCM_HC_Superset,FCM,E44,PCM,RDCM,TCCM,TCM,VDM,ECP_E
 SG_ EPBSP_ElecPrkBrkApplStsAuth : 36|3@0+ (1,0) [0|4] "" ACP2_MCU,ADIMa,ADIMb,VICM,CGM,ECM,EOCM,EOCM_HC_Superset,FCM,E44,PCM,RDCM,TCCM,TCM,VDM,ECP_E
 SG_ EPBSP_EPBSysBrkLgtsReqdAuth : 37|1@0+ (1,0) [0|1] "" ACP2_MCU,ADIMa,ADIMb,VICM,CGM,ECM,EOCM,EOCM_HC_Superset,FCM,PCM,RDCM,TCCM,TCM,ECP_E
 SG_ EPBSP_BrkSysBrkLgtsReqdAuth : 38|1@0+ (1,0) [0|1] "" ACP2_MCU,ADIMa,ADIMb,VICM,CGM,ECM,EOCM,EOCM_HC_Superset,FCM,PCM,RDCM,TCCM,TCM,ECP_E
 SG_ DMCP_EnvIdRsp2Auth : 39|1@0+ (1,0) [0|1] "" ACP2_MCU,ADIMa,ADIMb,VICM,CGM,ECM,EOCM,EOCM_HC_Superset,FCM,PCM,RDCM,TCCM,TCM,ECP_E
 SG_ TBIP_TrlrBrkgGainSetAuth : 43|8@0+ (0.392157,0) [0|100] "%" ACP2_MCU,ADIMa,ADIMb,VICM,CGM,ECM,EOCM,EOCM_HC_Superset,FCM,PCM,RDCM,TCCM,TCM,ECP_E
 SG_ TBIP_TrlrBrkDsbldIndOnAuth : 44|1@0+ (1,0) [0|1] "" ACP2_MCU,ADIMa,ADIMb,VICM,CGM,ECM,EOCM,EOCM_HC_Superset,FCM,PCM,RDCM,TCCM,TCM,ECP_E
 SG_ TBIP_ServTrlrBrkgSysIndOnAuth : 45|1@0+ (1,0) [0|1] "" ACP2_MCU,ADIMa,ADIMb,VICM,CGM,ECM,EOCM,EOCM_HC_Superset,FCM,PCM,RDCM,TCCM,TCM,ECP_E
 SG_ TBIP_CkTrlrIndOnAuth : 46|1@0+ (1,0) [0|1] "" ACP2_MCU,ADIMa,ADIMb,VICM,CGM,ECM,EOCM,EOCM_HC_Superset,FCM,PCM,RDCM,TCCM,TCM,ECP_E
 SG_ EPBSP_TrlrBrkgSysBrkLgtsRqdAuth : 47|1@0+ (1,0) [0|1] "" ACP2_MCU,ADIMa,ADIMb,VICM,CGM,ECM,EOCM,EOCM_HC_Superset,FCM,PCM,RDCM,TCCM,TCM,ECP_E
 SG_ SD15P_ARC : 49|2@0+ (1,0) [0|3] "" ACP2_MCU,ADIMa,ADIMb,VICM,CGM,ECM,EOCM,EOCM_HC_Superset,FCM,PCM,RDCM,TCCM,TCM,ECP_E
 SG_ TBIP_TrlrWrgFltIndOnAuth : 50|1@0+ (1,0) [0|1] "" ACP2_MCU,ADIMa,ADIMb,VICM,CGM,ECM,EOCM,EOCM_HC_Superset,FCM,PCM,RDCM,TCCM,TCM,ECP_E
 SG_ TBIP_TrlrBrkgGainSetIndOnAuth : 51|1@0+ (1,0) [0|1] "" ACP2_MCU,ADIMa,ADIMb,VICM,CGM,ECM,EOCM,EOCM_HC_Superset,FCM,PCM,RDCM,TCCM,TCM,ECP_E
 SG_ SD15P_Filler : 60|5@0+ (1,0) [0|31] "" ACP2_MCU,ADIMa,ADIMb,VICM,CGM,ECM,EOCM,EOCM_HC_Superset,FCM,PCM,RDCM,TCCM,TCM,ECP_E
 SG_ ElecPrkBrkMnPriPerfRdcd : 61|1@0+ (1,0) [0|1] "" ACP2_MCU,ADIMa,ADIMb,VICM,CGM,ECM,EOCM,EOCM_HC_Superset,FCM,PCM,RDCM,TCCM,TCM,ECP_E
 SG_ TrlrBrkgRdcdIndOn : 62|1@0+ (1,0) [0|1] "" ACP2_MCU,ADIMa,ADIMb,VICM,CGM,ECM,EOCM,EOCM_HC_Superset,FCM,PCM,RDCM,TCCM,TCM,ECP_E
 SG_ TrlrBrkgHldLstKnwnGainIndOn : 63|1@0+ (1,0) [0|1] "" ACP2_MCU,ADIMa,ADIMb,VICM,CGM,ECM,EOCM,EOCM_HC_Superset,FCM,PCM,RDCM,TCCM,TCM,ECP_E

BO_ 974 SrlDat160_PCSM_PDU: 8 Vector__XXX
 SG_ SrlDat160_PCSM : 7|64@0+ (1,0) [0|1.84467e+019] "" EPS,EPSb

BO_ 644 SrlDat160_Prtctd_PDU: 12 Vector__XXX
 SG_ SD160P_MAC : 7|32@0+ (1,0) [0|4.29497e+009] "" EPS,EPSb
 SG_ SD160P_FCnt : 39|5@0+ (1,0) [0|31] "" EPS,EPSb
 SG_ AASILASStrgReqAngVal : 47|14@0- (0.1,0) [-819.2|819.1] "degrees" EPS,EPSb
 SG_ AASILASStrgReqHiResTrqVal : 49|11@0- (0.01,0) [-10.24|10.23] "Nm" EPS,EPSb
 SG_ AASILASStrgReqLnFllwgRrStrgInhb : 64|1@0+ (1,0) [0|1] "" EPS,EPSb
 SG_ AASILASStrgReqSts : 66|2@0+ (1,0) [0|2] "" EPS,EPSb
 SG_ AASILASStrgReqAFtr : 70|4@0+ (1,0) [0|8] "" EPS,EPSb
 SG_ SD160P_Filler : 78|21@0+ (1,0) [0|2.09715e+006] "" EPS,EPSb
 SG_ AASILASStrgReqTyp : 79|1@0+ (1,0) [0|1] "" EPS,EPSb
 SG_ SD160P_ARC : 89|2@0+ (1,0) [0|3] "" EPS,EPSb

BO_ 975 SrlDat161_PCSM_PDU: 8 Vector__XXX
 SG_ SrlDat161_PCSM : 7|64@0+ (1,0) [0|1.84467e+019] "" EPS,EPSb

BO_ 602 SrlDat161_Prtctd_PDU: 8 Vector__XXX
 SG_ SD161P_MAC : 7|27@0+ (1,0) [0|1.34218e+008] "" EPS,EPSb
 SG_ SD161P_FCnt : 28|5@0+ (1,0) [0|31] "" EPS,EPSb
 SG_ LnDtnWrnCtlHRTrqOvrlyReqVal : 39|11@0- (0.01,0) [-10.24|10.23] "Nm" EPS,EPSb
 SG_ LnDtnWrnCtlTrqOvrlyReqActv_Inv : 40|1@0+ (1,0) [0|1] "" EPS,EPSb
 SG_ LnDtnWrnCtlTrqOvrlyReqActv_DuD : 41|1@0+ (1,0) [0|1] "" EPS,EPSb
 SG_ LnDtnWrnCtlTrqOvrlyReqActv : 42|1@0+ (1,0) [0|1] "" EPS,EPSb
 SG_ LnDtnWrnCtlHRTrqOvrlyReqVal_Inv : 43|1@0+ (1,0) [0|1] "" EPS,EPSb
 SG_ LnDtnWrnCtlHRTrqOvrlyReqVal_DuD : 44|1@0+ (1,0) [0|1] "" EPS,EPSb
 SG_ SD161P_Filler : 55|14@0+ (1,0) [0|16383] "" EPS,EPSb
 SG_ SD161P_ARC : 57|2@0+ (1,0) [0|3] "" EPS,EPSb

BO_ 917 SrlDat162_PCSM_PDU: 8 Vector__XXX
 SG_ SrlDat162_PCSM : 7|64@0+ (1,0) [0|1.84467e+019] "" ACP2_MCU,EOCM,EOCM_HC_Superset,FCM,ECP_E

BO_ 171 SrlDat162_Prtctd_PDU: 12 Vector__XXX
 SG_ SD162P_MAC : 7|32@0+ (1,0) [0|4.29497e+009] "" ACP2_MCU,EOCM,EOCM_HC_Superset,FCM,ECP_E
 SG_ SD162P_FCnt : 39|5@0+ (1,0) [0|31] "" ACP2_MCU,EOCM,EOCM_HC_Superset,FCM,ECP_E
 SG_ SpnsnPstnOfstFromTrmLF : 47|9@0- (1,0) [-256|255] "mm" ACP2_MCU,EOCM,EOCM_HC_Superset,FCM,ECP_E
 SG_ SpnsnPstnOfstFromTrmLR : 54|9@0- (1,0) [-256|255] "mm" ACP2_MCU,EOCM,EOCM_HC_Superset,FCM,ECP_E
 SG_ SpnsnPstnOfstFromTrmRF : 61|9@0- (1,0) [-256|255] "mm" ACP2_MCU,EOCM,EOCM_HC_Superset,FCM,ECP_E
 SG_ SpnsnPstnOfstFromTrmRR : 68|9@0- (1,0) [-256|255] "mm" ACP2_MCU,EOCM,EOCM_HC_Superset,FCM,ECP_E
 SG_ SpnsnPstnOfstFromTrmRR_Inv : 72|1@0+ (1,0) [0|1] "" ACP2_MCU,EOCM,EOCM_HC_Superset,FCM,ECP_E
 SG_ SpnsnPstnOfstFromTrmRF_Inv : 73|1@0+ (1,0) [0|1] "" ACP2_MCU,EOCM,EOCM_HC_Superset,FCM,ECP_E
 SG_ SpnsnPstnOfstFromTrmLR_Inv : 74|1@0+ (1,0) [0|1] "" ACP2_MCU,EOCM,EOCM_HC_Superset,FCM,ECP_E
 SG_ SpnsnPstnOfstFromTrmLF_Inv : 75|1@0+ (1,0) [0|1] "" ACP2_MCU,EOCM,EOCM_HC_Superset,FCM,ECP_E
 SG_ SD162P_Filler : 87|14@0+ (1,0) [0|16383] "" ACP2_MCU,EOCM,EOCM_HC_Superset,FCM,ECP_E
 SG_ SD162P_ARC : 89|2@0+ (1,0) [0|3] "" ACP2_MCU,EOCM,EOCM_HC_Superset,FCM,ECP_E

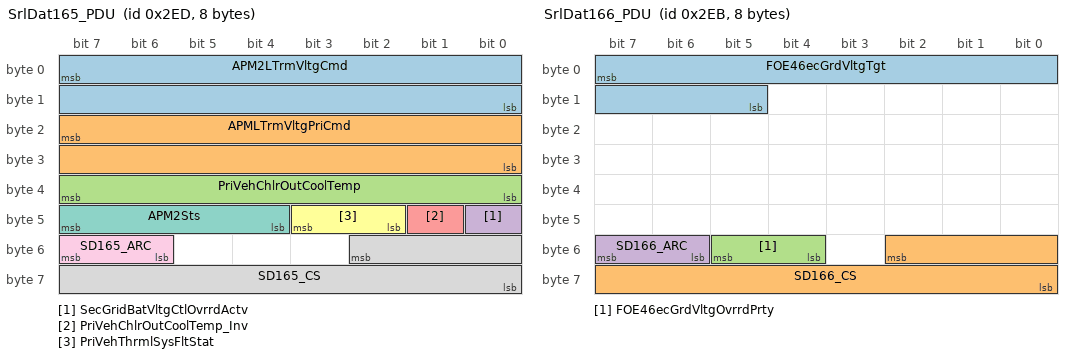
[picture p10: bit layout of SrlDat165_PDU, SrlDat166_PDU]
BO_ 749 SrlDat165_PDU: 8 Vector__XXX
 SG_ APM2LTrmVltgCmd : 7|16@0+ (0.001,0) [0|65.535] "Volts" ADIMa,ADIMb,FOPM
 SG_ APMLTrmVltgPriCmd : 23|16@0+ (0.001,0) [0|65.535] "Volts" ADIMa,ADIMb,FOPM
 SG_ PriVehChlrOutCoolTemp : 39|8@0+ (1,-40) [-40|215] "Deg C" ADIMa,ADIMb,FOPM
 SG_ SecGridBatVltgCtlOvrrdActv : 40|1@0+ (1,0) [0|1] "" ADIMa,ADIMb,FOPM
 SG_ PriVehChlrOutCoolTemp_Inv : 41|1@0+ (1,0) [0|1] "" ADIMa,ADIMb,FOPM
 SG_ PriVehThrmlSysFltStat : 43|2@0+ (1,0) [0|2] "" ADIMa,ADIMb,FOPM
 SG_ APM2Sts : 47|4@0+ (1,0) [0|8] "" ADIMa,ADIMb,CGM,FOPM
 SG_ SD165_CS : 50|11@0+ (1,0) [0|2047] "" ADIMa,ADIMb,FOPM
 SG_ SD165_ARC : 55|2@0+ (1,0) [0|3] "" ADIMa,ADIMb,FOPM

BO_ 747 SrlDat166_PDU: 8 Vector__XXX
 SG_ FOE46ecGrdVltgTgt : 7|11@0+ (0.01,0) [0|20.47] "Volts" VICM
 SG_ SD166_CS : 50|11@0+ (1,0) [0|2047] "" VICM
 SG_ FOE46ecGrdVltgOvrrdPrty : 53|2@0+ (1,0) [0|3] "" VICM
 SG_ SD166_ARC : 55|2@0+ (1,0) [0|3] "" VICM

BO_ 909 SrlDat16_PCSM_PDU: 8 Vector__XXX
 SG_ SrlDat16_PCSM : 7|64@0+ (1,0) [0|1.84467e+019] "" ACP2_MCU,ADIMa,ADIMb,AHS,ARS,VICM,DCM,ECM,EOCM,EOCM_HC_Superset,EPS,EPSb,FCM,E44,PCM,RDCM,TCCM,TCM,ECP_E,ECP_S,ECP_S2,ECP_X1

BO_ 59 SrlDat16_Prtctd_PDU: 64 Vector__XXX
 SG_ SD16P_MAC : 7|32@0+ (1,0) [0|4.29497e+009] "" ACP2_MCU,ADIMa,ADIMb,AHS,ARS,VICM,CGM,DCM,ECM,EOCM,EOCM_HC_Superset,EPS,EPSb,FCM,E44,PCM,RDCM,TCCM,TCM,ECP_E,ECP_S,ECP_S2,ECP_X1
 SG_ SD16P_FCnt : 39|5@0+ (1,0) [0|31] "" ACP2_MCU,ADIMa,ADIMb,AHS,ARS,VICM,CGM,DCM,ECM,EOCM,EOCM_HC_Superset,EPS,EPSb,FCM,E44,PCM,RDCM,TCCM,TCM,ECP_E,ECP_S,ECP_S2,ECP_X1
 SG_ BSIRP_BrkSysMinVltgReqAuth : 43|5@0+ (0.625,0) [0|19.375] "V" ACP2_MCU,ADIMa,ADIMb,AHS,ARS,VICM,CGM,DCM,ECM,EOCM,EOCM_HC_Superset,EPS,EPSb,FCM,E44,PCM,RDCM,TCCM,TCM,ECP_E,ECP_S,ECP_S2,ECP_X1
 SG_ BSIRP_AutoBrkgPTReqStsAuth : 46|3@0+ (1,0) [0|3] "" ACP2_MCU,ADIMa,ADIMb,AHS,ARS,VICM,CGM,DCM,ECM,EOCM,EOCM_HC_Superset,EPS,EPSb,FCM,E44,PCM,RDCM,TCCM,TCM,ECP_E,ECP_S,ECP_S2,ECP_X1
 SG_ BSIRP_AdpCruzHldActvAuth : 47|1@0+ (1,0) [0|1] "" ACP2_MCU,ADIMa,ADIMb,AHS,ARS,VICM,CGM,DCM,ECM,EOCM,EOCM_HC_Superset,EPS,EPSb,FCM,E44,PCM,RDCM,TCCM,TCM,ECP_E,ECP_S,ECP_S2,ECP_X1
 SG_ BSIRP_ChsSysAxlTqRqRspTpAuth : 50|3@0+ (1,0) [0|4] "" ACP2_MCU,ADIMa,ADIMb,AHS,ARS,VICM,CGM,DCM,ECM,EOCM,EOCM_HC_Superset,EPS,EPSb,FCM,E44,PCM,RDCM,TCCM,TCM,ECP_E,ECP_S,ECP_S2,ECP_X1
 SG_ BSIRP_ChsSysAxlTqRqFncAuth : 54|4@0+ (1,0) [0|14] "" ACP2_MCU,ADIMa,ADIMb,AHS,ARS,VICM,CGM,DCM,ECM,EOCM,EOCM_HC_Superset,EPS,EPSb,FCM,E44,PCM,RDCM,TCCM,TCM,ECP_E,ECP_S,ECP_S2,ECP_X1
 SG_ BSIRP_ChsSysImmAxlTqRqValAuth : 63|15@0+ (2,-22534) [-22534|43000] "Nm" ACP2_MCU,ADIMa,ADIMb,AHS,ARS,VICM,CGM,DCM,ECM,EOCM,EOCM_HC_Superset,EPS,EPSb,FCM,E44,PCM,RDCM,TCCM,TCM,ECP_E,ECP_S,ECP_S2,ECP_X1
 SG_ BSIRP_ChsSysPrdAxlTqRqItvTpAuth : 64|2@0+ (1,0) [0|3] "" ACP2_MCU,ADIMa,ADIMb,AHS,ARS,VICM,CGM,DCM,ECM,EOCM,EOCM_HC_Superset,EPS,EPSb,FCM,E44,PCM,RDCM,TCCM,TCM,ECP_E,ECP_S,ECP_S2,ECP_X1
 SG_ BSIRP_ChsSysPrdAxlTqRqValAuth : 78|15@0+ (2,-22534) [-22534|43000] "Nm" ACP2_MCU,ADIMa,ADIMb,AHS,ARS,VICM,CGM,DCM,ECM,EOCM,EOCM_HC_Superset,EPS,EPSb,FCM,E44,PCM,RDCM,TCCM,TCM,ECP_E,ECP_S,ECP_S2,ECP_X1
 SG_ BrkAsstHalfSysBstFaildCktAuth : 89|3@0+ (1,0) [0|4] "" ACP2_MCU,ADIMa,ADIMb,AHS,ARS,VICM,CGM,DCM,ECM,EOCM,EOCM_HC_Superset,EPS,EPSb,FCM,E44,PCM,RDCM,TCCM,TCM,ECP_E,ECP_S,ECP_S2,ECP_X1
 SG_ BSIRP_RrVirtBmpInhbAuth : 90|1@0+ (1,0) [0|1] "" ACP2_MCU,ADIMa,ADIMb,AHS,ARS,VICM,CGM,DCM,ECM,EOCM,EOCM_HC_Superset,EPS,EPSb,FCM,E44,PCM,RDCM,TCCM,TCM,ECP_E,ECP_S,ECP_S2,ECP_X1
 SG_ BSIRP_HillDscntCtlStsAuth : 92|2@0+ (1,0) [0|2] "" ACP2_MCU,ADIMa,ADIMb,AHS,ARS,VICM,CGM,DCM,ECM,EOCM,EOCM_HC_Superset,EPS,EPSb,FCM,E44,PCM,RDCM,TCCM,TCM,ECP_E,ECP_S,ECP_S2,ECP_X1
 SG_ BSIRP_DrvrSeltdHldEnbldAuth : 93|1@0+ (1,0) [0|1] "" ACP2_MCU,ADIMa,ADIMb,AHS,ARS,VICM,CGM,DCM,ECM,EOCM,EOCM_HC_Superset,EPS,EPSb,FCM,E44,PCM,RDCM,TCCM,TCM,ECP_E,ECP_S,ECP_S2,ECP_X1
 SG_ BSIRP_DrvrSeltdHldActvAuth : 94|1@0+ (1,0) [0|1] "" ACP2_MCU,ADIMa,ADIMb,AHS,ARS,VICM,CGM,DCM,ECM,EOCM,EOCM_HC_Superset,EPS,EPSb,FCM,E44,PCM,RDCM,TCCM,TCM,ECP_E,ECP_S,ECP_S2,ECP_X1
 SG_ BSIRP_ClsnPrepSysInhbAuth : 95|1@0+ (1,0) [0|1] "" ACP2_MCU,ADIMa,ADIMb,AHS,ARS,VICM,CGM,DCM,ECM,EOCM,EOCM_HC_Superset,EPS,EPSb,FCM,E44,PCM,RDCM,TCCM,TCM,ECP_E,ECP_S,ECP_S2,ECP_X1
 SG_ BrkSysSpltFricCoefEstdWDPrsAuth : 100|8@0- (100,0) [-12800|12700] "kPa" ACP2_MCU,ADIMa,ADIMb,AHS,ARS,VICM,CGM,DCM,ECM,EOCM,EOCM_HC_Superset,EPS,EPSb,FCM,E44,PCM,RDCM,TCCM,TCM,ECP_E,ECP_S,ECP_S2,ECP_X1
 SG_ BrkSysSpltFricCoefBrkgActvAuth : 101|1@0+ (1,0) [0|1] "" ACP2_MCU,ADIMa,ADIMb,AHS,ARS,VICM,CGM,DCM,ECM,EOCM,EOCM_HC_Superset,EPS,EPSb,FCM,E44,PCM,RDCM,TCCM,TCM,ECP_E,ECP_S,ECP_S2,ECP_X1
 SG_ BrkSysSpltFricCoefAccelActvAuth : 102|1@0+ (1,0) [0|1] "" ACP2_MCU,ADIMa,ADIMb,AHS,ARS,VICM,CGM,DCM,ECM,EOCM,EOCM_HC_Superset,EPS,EPSb,FCM,E44,PCM,RDCM,TCCM,TCM,ECP_E,ECP_S,ECP_S2,ECP_X1
 SG_ CBIP_BrkPedPstnEmsRltdAuth : 105|8@0+ (0.392157,0) [0|100] "%" ACP2_MCU,ADIMa,ADIMb,AHS,ARS,VICM,CGM,DCM,ECM,EOCM,EOCM_HC_Superset,EPS,EPSb,FCM,E44,PCM,RDCM,TCCM,TCM,ECP_E,ECP_S,ECP_S2,ECP_X1
 SG_ CBIP_ACCBrkgStsAuth : 107|2@0+ (1,0) [0|2] "" ACP2_MCU,ADIMa,ADIMb,AHS,ARS,VICM,CGM,DCM,ECM,EOCM,EOCM_HC_Superset,EPS,EPSb,FCM,E44,PCM,RDCM,TCCM,TCM,ECP_E,ECP_S,ECP_S2,ECP_X1
 SG_ CBIP_ACCBrkgActvAuth : 108|1@0+ (1,0) [0|1] "" ACP2_MCU,ADIMa,ADIMb,AHS,ARS,VICM,CGM,DCM,ECM,EOCM,EOCM_HC_Superset,EPS,EPSb,FCM,E44,PCM,RDCM,TCCM,TCM,ECP_E,ECP_S,ECP_S2,ECP_X1
 SG_ CBIP_ClsnImntBrkgStsAuth : 112|2@0+ (1,0) [0|2] "" ACP2_MCU,ADIMa,ADIMb,AHS,ARS,VICM,CGM,DCM,ECM,EOCM,EOCM_HC_Superset,EPS,EPSb,FCM,E44,PCM,RDCM,TCCM,TCM,ECP_E,ECP_S,ECP_S2,ECP_X1
 SG_ CBIP_BrkPedPstnEmsRltdAuth_Inv : 113|1@0+ (1,0) [0|1] "" ACP2_MCU,ADIMa,ADIMb,AHS,ARS,VICM,CGM,DCM,ECM,EOCM,EOCM_HC_Superset,EPS,EPSb,FCM,E44,PCM,RDCM,TCCM,TCM,ECP_E,ECP_S,ECP_S2,ECP_X1
 SG_ CSATRP_PriATReqFncAuth : 123|4@0+ (1,0) [0|10] "" ACP2_MCU,ADIMa,ADIMb,AHS,ARS,VICM,CGM,DCM,ECM,EOCM,EOCM_HC_Superset,EPS,EPSb,FCM,E44,PCM,RDCM,TCCM,TCM,ECP_E,ECP_S,ECP_S2,ECP_X1
 SG_ CBIP_EPBCruzCtlCnclReqAuth : 124|1@0+ (1,0) [0|1] "" ACP2_MCU,ADIMa,ADIMb,AHS,ARS,VICM,CGM,DCM,ECM,EOCM,EOCM_HC_Superset,EPS,EPSb,FCM,E44,PCM,RDCM,TCCM,TCM,ECP_E,ECP_S,ECP_S2,ECP_X1
 SG_ CBIP_DrvrIndpntBrkAppActvAuth : 125|1@0+ (1,0) [0|1] "" ACP2_MCU,ADIMa,ADIMb,AHS,ARS,VICM,CGM,DCM,ECM,EOCM,EOCM_HC_Superset,EPS,EPSb,FCM,E44,PCM,RDCM,TCCM,TCM,ECP_E,ECP_S,ECP_S2,ECP_X1
 SG_ CBIP_ClsnImntDrvrBrkPedOvrdAuth : 126|1@0+ (1,0) [0|1] "" ACP2_MCU,ADIMa,ADIMb,AHS,ARS,VICM,CGM,DCM,ECM,EOCM,EOCM_HC_Superset,EPS,EPSb,FCM,E44,PCM,RDCM,TCCM,TCM,ECP_E,ECP_S,ECP_S2,ECP_X1
 SG_ CSATRP_PriATReqImmedAuth : 135|15@0+ (2,-22534) [-22534|43000] "Nm" ACP2_MCU,ADIMa,ADIMb,AHS,ARS,VICM,CGM,DCM,ECM,EOCM,EOCM_HC_Superset,EPS,EPSb,FCM,E44,PCM,RDCM,TCCM,TCM,ECP_E,ECP_S,ECP_S2,ECP_X1
 SG_ CSATRP_PriATReqIntvTypPrdtdAuth : 136|2@0+ (1,0) [0|3] "" ACP2_MCU,ADIMa,ADIMb,AHS,ARS,VICM,CGM,DCM,ECM,EOCM,EOCM_HC_Superset,EPS,EPSb,FCM,E44,PCM,RDCM,TCCM,TCM,ECP_E,ECP_S,ECP_S2,ECP_X1
 SG_ CSATRP_PriATReqPrdtdAuth : 150|15@0+ (2,-22534) [-22534|43000] "Nm" ACP2_MCU,ADIMa,ADIMb,AHS,ARS,VICM,CGM,DCM,ECM,EOCM,EOCM_HC_Superset,EPS,EPSb,FCM,E44,PCM,RDCM,TCCM,TCM,ECP_E,ECP_S,ECP_S2,ECP_X1
 SG_ CSATRP_SecATReqFncAuth : 162|4@0+ (1,0) [0|10] "" ACP2_MCU,ADIMa,ADIMb,AHS,ARS,VICM,CGM,DCM,ECM,EOCM,EOCM_HC_Superset,EPS,EPSb,FCM,E44,PCM,RDCM,TCCM,TCM,ECP_E,ECP_S,ECP_S2,ECP_X1
 SG_ CSATRP_SecATIntvTypPrdtdAuth : 164|2@0+ (1,0) [0|3] "" ACP2_MCU,ADIMa,ADIMb,AHS,ARS,VICM,CGM,DCM,ECM,EOCM,EOCM_HC_Superset,EPS,EPSb,FCM,E44,PCM,RDCM,TCCM,TCM,ECP_E,ECP_S,ECP_S2,ECP_X1
 SG_ CSATRP_PriATReqRespTypAuth : 167|3@0+ (1,0) [0|4] "" ACP2_MCU,ADIMa,ADIMb,AHS,ARS,VICM,CGM,DCM,ECM,EOCM,EOCM_HC_Superset,EPS,EPSb,FCM,E44,PCM,RDCM,TCCM,TCM,ECP_E,ECP_S,ECP_S2,ECP_X1
 SG_ CSATRP_SecATReqImmedAuth : 174|15@0+ (2,-22534) [-22534|43000] "Nm" ACP2_MCU,ADIMa,ADIMb,AHS,ARS,VICM,CGM,DCM,ECM,EOCM,EOCM_HC_Superset,EPS,EPSb,FCM,E44,PCM,RDCM,TCCM,TCM,ECP_E,ECP_S,ECP_S2,ECP_X1
 SG_ CSATRP_SecATReqPrdtdAuth : 191|15@0+ (2,-22534) [-22534|43000] "Nm" ACP2_MCU,ADIMa,ADIMb,AHS,ARS,VICM,CGM,DCM,ECM,EOCM,EOCM_HC_Superset,EPS,EPSb,FCM,E44,PCM,RDCM,TCCM,TCM,ECP_E,ECP_S,ECP_S2,ECP_X1
 SG_ CSATRP_SecATReqRespTypAuth : 192|3@0+ (1,0) [0|4] "" ACP2_MCU,ADIMa,ADIMb,AHS,ARS,VICM,CGM,DCM,ECM,EOCM,EOCM_HC_Superset,EPS,EPSb,FCM,E44,PCM,RDCM,TCCM,TCM,ECP_E,ECP_S,ECP_S2,ECP_X1
 SG_ CSBT2P_BrkBlndgAxlTrqReqAuth : 205|12@0+ (2,0) [0|8190] "Nm" ACP2_MCU,ADIMa,ADIMb,AHS,ARS,VICM,CGM,DCM,ECM,EOCM,EOCM_HC_Superset,EPS,EPSb,FCM,E44,PCM,RDCM,TCCM,TCM,ECP_E,ECP_S,ECP_S2,ECP_X1
 SG_ CSBTP_ChsSysTtBrkAxTqVlAuth : 209|14@0+ (2,0) [0|32766] "" ACP2_MCU,ADIMa,ADIMb,AHS,ARS,BSM,VICM,CGM,DCM,ECM,EOCM,EOCM_HC_Superset,EPS,EPSb,FCM,E44,PCM,RDCM,TCCM,TCM,ECP_E,ECP_S,ECP_S2,ECP_X1
 SG_ CSBTP_DrvrIntndTtBrkTqAuth : 226|14@0+ (2,0) [0|32766] "Nm" ACP2_MCU,ADIMa,ADIMb,AHS,ARS,BSM,VICM,CGM,DCM,ECM,EOCM,EOCM_HC_Superset,EPS,EPSb,FCM,E44,PCM,RDCM,TCCM,TCM,ECP_E,ECP_S,ECP_S2,ECP_X1
 SG_ CSBTP_ChsSysTtBrkAxTqVlAuth_Inv : 227|1@0+ (1,0) [0|1] "" ACP2_MCU,ADIMa,ADIMb,AHS,ARS,VICM,CGM,DCM,ECM,EOCM,EOCM_HC_Superset,EPS,EPSb,FCM,E44,PCM,RDCM,TCCM,TCM,ECP_E,ECP_S,ECP_S2,ECP_X1
 SG_ FWDECP_LFAuth : 244|11@0+ (1,0) [0|2047] "" ACP2_MCU,ADIMa,ADIMb,AHS,ARS,VICM,CGM,DCM,ECM,EOCM,EOCM_HC_Superset,EPS,EPSb,FCM,E44,PCM,RDCM,TCCM,TCM,ECP_E,ECP_S,ECP_S2,ECP_X1
 SG_ FWDECP_RFAuth : 248|11@0+ (1,0) [0|2047] "" ACP2_MCU,ADIMa,ADIMb,AHS,ARS,VICM,CGM,DCM,ECM,EOCM,EOCM_HC_Superset,EPS,EPSb,FCM,E44,PCM,RDCM,TCCM,TCM,ECP_E,ECP_S,ECP_S2,ECP_X1
 SG_ FWDECP_LFAuth_Inv : 249|1@0+ (1,0) [0|1] "" ACP2_MCU,ADIMa,ADIMb,AHS,ARS,VICM,CGM,DCM,ECM,EOCM,EOCM_HC_Superset,EPS,EPSb,FCM,E44,PCM,RDCM,TCCM,TCM,ECP_E,ECP_S,ECP_S2,ECP_X1
 SG_ PTP_EngSpdIntvTypAuth : 264|2@0+ (1,0) [0|1] "" ACP2_MCU,ADIMa,ADIMb,AHS,ARS,VICM,CGM,DCM,ECM,EOCM,EOCM_HC_Superset,EPS,EPSb,FCM,E44,PCM,RDCM,TCCM,TCM,ECP_E,ECP_S,ECP_S2,ECP_X1
 SG_ PTP_EngSpdCtlRespAuth : 266|2@0+ (1,0) [0|3] "" ACP2_MCU,ADIMa,ADIMb,AHS,ARS,VICM,CGM,DCM,ECM,EOCM,EOCM_HC_Superset,EPS,EPSb,FCM,E44,PCM,RDCM,TCCM,TCM,ECP_E,ECP_S,ECP_S2,ECP_X1
 SG_ PTP_DCTLaunchCtlActvAuth : 267|1@0+ (1,0) [0|1] "" ACP2_MCU,ADIMa,ADIMb,AHS,ARS,VICM,CGM,DCM,ECM,EOCM,EOCM_HC_Superset,EPS,EPSb,FCM,E44,PCM,RDCM,TCCM,TCM,ECP_E,ECP_S,ECP_S2,ECP_X1
 SG_ FWDECP_RstOccAuth : 268|1@0+ (1,0) [0|1] "" ACP2_MCU,ADIMa,ADIMb,AHS,ARS,VICM,CGM,DCM,ECM,EOCM,EOCM_HC_Superset,EPS,EPSb,FCM,E44,PCM,RDCM,TCCM,TCM,ECP_E,ECP_S,ECP_S2,ECP_X1
 SG_ FWDECP_RFAuth_Inv : 269|1@0+ (1,0) [0|1] "" ACP2_MCU,ADIMa,ADIMb,AHS,ARS,VICM,CGM,DCM,ECM,EOCM,EOCM_HC_Superset,EPS,EPSb,FCM,E44,PCM,RDCM,TCCM,TCM,ECP_E,ECP_S,ECP_S2,ECP_X1
 SG_ PTP_EngSpdReqValAuth : 278|10@0+ (8,0) [0|8184] "rpm" ACP2_MCU,ADIMa,ADIMb,AHS,ARS,VICM,CGM,DCM,ECM,EOCM,EOCM_HC_Superset,EPS,EPSb,FCM,E44,PCM,RDCM,TCCM,TCM,ECP_E,ECP_S,ECP_S2,ECP_X1
 SG_ RALTCRP_ValAuth : 282|11@0+ (5,-5120) [-5120|5115] "Nm" ACP2_MCU,ADIMa,ADIMb,AHS,ARS,VICM,CGM,DCM,ECM,EOCM,EOCM_HC_Superset,EPS,EPSb,FCM,E44,PCM,RDCM,TCCM,TCM,ECP_E,ECP_S,ECP_S2,ECP_X1
 SG_ RALTCRP_TypAuth : 284|2@0+ (1,0) [0|3] "" ACP2_MCU,ADIMa,ADIMb,AHS,ARS,VICM,CGM,DCM,ECM,EOCM,EOCM_HC_Superset,EPS,EPSb,FCM,E44,PCM,RDCM,TCCM,TCM,ECP_E,ECP_S,ECP_S2,ECP_X1
 SG_ RWDECP_LRAuth : 303|11@0+ (1,0) [0|2047] "" ACP2_MCU,ADIMa,ADIMb,AHS,ARS,VICM,CGM,DCM,ECM,EOCM,EOCM_HC_Superset,EPS,EPSb,FCM,E44,PCM,RDCM,TCCM,TCM,ECP_E,ECP_S,ECP_S2,ECP_X1
 SG_ RWDECP_RRAuth : 307|11@0+ (1,0) [0|2047] "" ACP2_MCU,ADIMa,ADIMb,AHS,ARS,VICM,CGM,DCM,ECM,EOCM,EOCM_HC_Superset,EPS,EPSb,FCM,E44,PCM,RDCM,TCCM,TCM,ECP_E,ECP_S,ECP_S2,ECP_X1
 SG_ RWDECP_LRAuth_Inv : 308|1@0+ (1,0) [0|1] "" ACP2_MCU,ADIMa,ADIMb,AHS,ARS,VICM,CGM,DCM,ECM,EOCM,EOCM_HC_Superset,EPS,EPSb,FCM,E44,PCM,RDCM,TCCM,TCM,ECP_E,ECP_S,ECP_S2,ECP_X1
 SG_ RWDECP_RRAuth_Inv : 312|1@0+ (1,0) [0|1] "" ACP2_MCU,ADIMa,ADIMb,AHS,ARS,VICM,CGM,DCM,ECM,EOCM,EOCM_HC_Superset,EPS,EPSb,FCM,E44,PCM,RDCM,TCCM,TCM,ECP_E,ECP_S,ECP_S2,ECP_X1
 SG_ SATRVP_SecAxlTrqRqValAuth : 326|10@0+ (10,0) [0|10230] "Nm" ACP2_MCU,ADIMa,ADIMb,AHS,ARS,VICM,CGM,DCM,ECM,EOCM,EOCM_HC_Superset,EPS,EPSb,FCM,E44,PCM,RDCM,TCCM,TCM,ECP_E,ECP_S,ECP_S2,ECP_X1
 SG_ RWDECP_RstOccAuth : 327|1@0+ (1,0) [0|1] "" ACP2_MCU,ADIMa,ADIMb,AHS,ARS,VICM,CGM,DCM,ECM,EOCM,EOCM_HC_Superset,EPS,EPSb,FCM,E44,PCM,RDCM,TCCM,TCM,ECP_E,ECP_S,ECP_S2,ECP_X1
 SG_ TCTR1P_AxlTrqReqValLRAuth : 328|10@0+ (10,0) [0|10230] "Nm" ACP2_MCU,ADIMa,ADIMb,AHS,ARS,VICM,CGM,DCM,ECM,EOCM,EOCM_HC_Superset,EPS,EPSb,FCM,E44,PCM,RDCM,TCCM,TCM,ECP_E,ECP_S,ECP_S2,ECP_X1
 SG_ TCTR1P_AxlTrqReqTypRRAuth : 330|2@0+ (1,0) [0|3] "" ACP2_MCU,ADIMa,ADIMb,AHS,ARS,VICM,CGM,DCM,ECM,EOCM,EOCM_HC_Superset,EPS,EPSb,FCM,E44,PCM,RDCM,TCCM,TCM,ECP_E,ECP_S,ECP_S2,ECP_X1
 SG_ TCTR1P_AxlTrqReqTypLRAuth : 332|2@0+ (1,0) [0|3] "" ACP2_MCU,ADIMa,ADIMb,AHS,ARS,VICM,CGM,DCM,ECM,EOCM,EOCM_HC_Superset,EPS,EPSb,FCM,E44,PCM,RDCM,TCCM,TCM,ECP_E,ECP_S,ECP_S2,ECP_X1
 SG_ TCTR1P_AxlTrqReqValRRAuth : 350|10@0+ (10,0) [0|10230] "Nm" ACP2_MCU,ADIMa,ADIMb,AHS,ARS,VICM,CGM,DCM,ECM,EOCM,EOCM_HC_Superset,EPS,EPSb,FCM,E44,PCM,RDCM,TCCM,TCM,ECP_E,ECP_S,ECP_S2,ECP_X1
 SG_ WhlAngVelLFrtAuth : 356|14@0+ (0.004,0) [0|65.532] "Revolutions Per Second" ACP2_MCU,ADIMa,ADIMb,AHS,ARS,VICM,CGM,DCM,ECM,EOCM,EOCM_HC_Superset,EPS,EPSb,FCM,E44,PCM,RDCM,TCCM,TCM,ECP_E,ECP_S,ECP_S2,ECP_X1
 SG_ WhlAngVelLRrAuth : 373|14@0+ (0.004,0) [0|65.532] "Revolutions Per Second" ACP2_MCU,ADIMa,ADIMb,AHS,ARS,VICM,CGM,DCM,ECM,EOCM,EOCM_HC_Superset,EPS,EPSb,FCM,E44,PCM,RDCM,TCCM,TCM,ECP_E,ECP_S,ECP_S2,ECP_X1
 SG_ WhlAngVelLFrtAuth_Inv : 374|1@0+ (1,0) [0|1] "" ACP2_MCU,ADIMa,ADIMb,AHS,ARS,VICM,CGM,DCM,ECM,EOCM,EOCM_HC_Superset,EPS,EPSb,FCM,E44,PCM,RDCM,TCCM,TCM,ECP_E,ECP_S,ECP_S2,ECP_X1
 SG_ WhlAngVelRFrtAuth : 390|14@0+ (0.004,0) [0|65.532] "Revolutions Per Second" ACP2_MCU,ADIMa,ADIMb,AHS,ARS,VICM,CGM,DCM,ECM,EOCM,EOCM_HC_Superset,EPS,EPSb,FCM,E44,PCM,RDCM,TCCM,TCM,ECP_E,ECP_S,ECP_S2,ECP_X1
 SG_ WhlAngVelLRrAuth_Inv : 391|1@0+ (1,0) [0|1] "" ACP2_MCU,ADIMa,ADIMb,AHS,ARS,VICM,CGM,DCM,ECM,EOCM,EOCM_HC_Superset,EPS,EPSb,FCM,E44,PCM,RDCM,TCCM,TCM,ECP_E,ECP_S,ECP_S2,ECP_X1
 SG_ WhlAngVelRFrtAuth_Inv : 392|1@0+ (1,0) [0|1] "" ACP2_MCU,ADIMa,ADIMb,AHS,ARS,VICM,CGM,DCM,ECM,EOCM,EOCM_HC_Superset,EPS,EPSb,FCM,E44,PCM,RDCM,TCCM,TCM,ECP_E,ECP_S,ECP_S2,ECP_X1
 SG_ WhlAngVelRRrAuth : 407|14@0+ (0.004,0) [0|65.532] "Revolutions Per Second" ACP2_MCU,ADIMa,ADIMb,AHS,ARS,VICM,CGM,DCM,ECM,EOCM,EOCM_HC_Superset,EPS,EPSb,FCM,E44,PCM,RDCM,TCCM,TCM,ECP_E,ECP_S,ECP_S2,ECP_X1
 SG_ WhlBrkPresAuth_Inv : 408|1@0+ (1,0) [0|1] "" ACP2_MCU,ADIMa,ADIMb,AHS,ARS,VICM,CGM,DCM,ECM,EOCM,EOCM_HC_Superset,EPS,EPSb,FCM,E44,PCM,RDCM,TCCM,TCM,ECP_E,ECP_S,ECP_S2,ECP_X1
 SG_ WhlAngVelRRrAuth_Inv : 409|1@0+ (1,0) [0|1] "" ACP2_MCU,ADIMa,ADIMb,AHS,ARS,VICM,CGM,DCM,ECM,EOCM,EOCM_HC_Superset,EPS,EPSb,FCM,E44,PCM,RDCM,TCCM,TCM,ECP_E,ECP_S,ECP_S2,ECP_X1
 SG_ WhlBrkPresLFAuth : 423|8@0+ (100,0) [0|25500] "kPa" ACP2_MCU,ADIMa,ADIMb,AHS,ARS,VICM,CGM,DCM,ECM,EOCM,EOCM_HC_Superset,EPS,EPSb,FCM,E44,PCM,RDCM,TCCM,TCM,ECP_E,ECP_S,ECP_S2,ECP_X1
 SG_ WhlBrkPresLRAuth : 431|8@0+ (100,0) [0|25500] "kPa" ACP2_MCU,ADIMa,ADIMb,AHS,ARS,VICM,CGM,DCM,ECM,EOCM,EOCM_HC_Superset,EPS,EPSb,FCM,E44,PCM,RDCM,TCCM,TCM,ECP_E,ECP_S,ECP_S2,ECP_X1
 SG_ WhlBrkPresRFAuth : 439|8@0+ (100,0) [0|25500] "kPa" ACP2_MCU,ADIMa,ADIMb,AHS,ARS,VICM,CGM,DCM,ECM,EOCM,EOCM_HC_Superset,EPS,EPSb,FCM,E44,PCM,RDCM,TCCM,TCM,ECP_E,ECP_S,ECP_S2,ECP_X1
 SG_ WhlBrkPresRRAuth : 447|8@0+ (100,0) [0|25500] "kPa" ACP2_MCU,ADIMa,ADIMb,AHS,ARS,VICM,CGM,DCM,ECM,EOCM,EOCM_HC_Superset,EPS,EPSb,FCM,E44,PCM,RDCM,TCCM,TCM,ECP_E,ECP_S,ECP_S2,ECP_X1
 SG_ ChsSysPriAxlLtTrqReqAuth : 451|15@0+ (2,-22534) [-22534|43000] "Nm" ACP2_MCU,ADIMa,ADIMb,AHS,ARS,VICM,CGM,DCM,ECM,EOCM,EOCM_HC_Superset,EPS,EPSb,FCM,E44,PCM,RDCM,TCCM,TCM,ECP_E,ECP_S,ECP_S2,ECP_X1
 SG_ ChsSysPriAxlLtTqRqIntvTpAuth : 453|2@0+ (1,0) [0|3] "" ACP2_MCU,ADIMa,ADIMb,AHS,ARS,VICM,CGM,DCM,ECM,EOCM,EOCM_HC_Superset,EPS,EPSb,FCM,E44,PCM,RDCM,TCCM,TCM,ECP_E,ECP_S,ECP_S2,ECP_X1
 SG_ SD16P_ARC : 455|2@0+ (1,0) [0|3] "" ACP2_MCU,ADIMa,ADIMb,AHS,ARS,VICM,CGM,DCM,ECM,EOCM,EOCM_HC_Superset,EPS,EPSb,FCM,E44,PCM,RDCM,TCCM,TCM,ECP_E,ECP_S,ECP_S2,ECP_X1
 SG_ ChsSysPriAxlRtTqRqIntvTpAuth : 464|2@0+ (1,0) [0|3] "" ACP2_MCU,ADIMa,ADIMb,AHS,ARS,VICM,CGM,DCM,ECM,EOCM,EOCM_HC_Superset,EPS,EPSb,FCM,E44,PCM,RDCM,TCCM,TCM,ECP_E,ECP_S,ECP_S2,ECP_X1
 SG_ ChsSysPriAxlLtTrqReqFncAuth : 468|4@0+ (1,0) [0|10] "" ACP2_MCU,ADIMa,ADIMb,AHS,ARS,VICM,CGM,DCM,ECM,EOCM,EOCM_HC_Superset,EPS,EPSb,FCM,E44,PCM,RDCM,TCCM,TCM,ECP_E,ECP_S,ECP_S2,ECP_X1
 SG_ ChsSysPriAxlRtTrqReqAuth : 478|15@0+ (2,-22534) [-22534|43000] "Nm" ACP2_MCU,ADIMa,ADIMb,AHS,ARS,VICM,CGM,DCM,ECM,EOCM,EOCM_HC_Superset,EPS,EPSb,FCM,E44,PCM,RDCM,TCCM,TCM,ECP_E,ECP_S,ECP_S2,ECP_X1
 SG_ VehDynOvrstrUndrstrVal : 488|12@0- (0.1,0) [-204.8|204.7] "%" ACP2_MCU,ADIMa,ADIMb,AHS,ARS,VICM,CGM,DCM,ECM,EOCM,EOCM_HC_Superset,EPS,EPSb,FCM,E44,PCM,RDCM,TCCM,TCM,ECP_E,ECP_S,ECP_S2,ECP_X1
 SG_ ChsSysPrplSysFricBrkTqRqStsAuth : 491|3@0+ (1,0) [0|4] "" ACP2_MCU,ADIMa,ADIMb,AHS,ARS,VICM,CGM,DCM,ECM,EOCM,EOCM_HC_Superset,EPS,EPSb,FCM,E44,PCM,RDCM,TCCM,TCM,ECP_E,ECP_S,ECP_S2,ECP_X1
 SG_ ChsSysPriAxlRtTrqReqFncAuth : 495|4@0+ (1,0) [0|10] "" ACP2_MCU,ADIMa,ADIMb,AHS,ARS,VICM,CGM,DCM,ECM,EOCM,EOCM_HC_Superset,EPS,EPSb,FCM,E44,PCM,RDCM,TCCM,TCM,ECP_E,ECP_S,ECP_S2,ECP_X1
 SG_ SD16P_Filler : 506|3@0+ (1,0) [0|7] "" ACP2_MCU,ADIMa,ADIMb,AHS,ARS,VICM,CGM,DCM,ECM,EOCM,EOCM_HC_Superset,EPS,EPSb,FCM,E44,PCM,RDCM,TCCM,TCM,ECP_E,ECP_S,ECP_S2,ECP_X1
 SG_ BrkSysBrkTrqSfcntStndstl : 507|1@0+ (1,0) [0|1] "" ACP2_MCU,ADIMa,ADIMb,AHS,ARS,VICM,CGM,DCM,ECM,EOCM,EOCM_HC_Superset,EPS,EPSb,FCM,E44,PCM,RDCM,TCCM,TCM,ECP_E,ECP_S,ECP_S2,ECP_X1
 SG_ VehDynOvrstrUndrstrVal_Inv : 508|1@0+ (1,0) [0|1] "" ACP2_MCU,ADIMa,ADIMb,AHS,ARS,VICM,CGM,DCM,ECM,EOCM,EOCM_HC_Superset,EPS,EPSb,FCM,E44,PCM,RDCM,TCCM,TCM,ECP_E,ECP_S,ECP_S2,ECP_X1

BO_ 1342 Message1086_PDU: 8 Vector__XXX
 SG_ Sig6846 : 7|64@0+ (1,0) [0|1.84467e+019] "" ADIMa,ADIMb

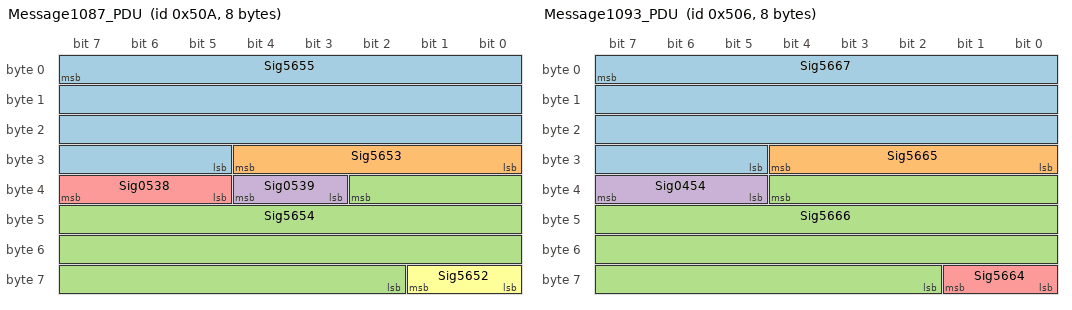
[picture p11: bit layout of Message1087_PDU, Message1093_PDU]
BO_ 1290 Message1087_PDU: 8 Vector__XXX
 SG_ Sig5655 : 7|27@0+ (1,0) [0|1.34218e+008] "" ADIMa,ADIMb
 SG_ Sig5653 : 28|5@0+ (1,0) [0|31] "" ADIMa,ADIMb
 SG_ Sig5654 : 34|25@0+ (1,0) [0|3.35544e+007] "" ADIMa,ADIMb
 SG_ Sig0539 : 36|2@0+ (1,0) [0|3] "" ADIMa,ADIMb
 SG_ Sig0538 : 39|3@0+ (1,0) [0|5] "" ADIMa,ADIMb
 SG_ Sig5652 : 57|2@0+ (1,0) [0|3] "" ADIMa,ADIMb

BO_ 1291 Message1092_PDU: 8 Vector__XXX
 SG_ Sig6849 : 7|64@0+ (1,0) [0|1.84467e+019] "" EBCM

BO_ 1286 Message1093_PDU: 8 Vector__XXX
 SG_ Sig5667 : 7|27@0+ (1,0) [0|1.34218e+008] "" EBCM
 SG_ Sig5665 : 28|5@0+ (1,0) [0|31] "" EBCM
 SG_ Sig5666 : 36|27@0+ (1,0) [0|1.34218e+008] "" EBCM
 SG_ Sig0454 : 39|3@0+ (1,0) [0|3] "" EBCM
 SG_ Sig5664 : 57|2@0+ (1,0) [0|3] "" EBCM

BO_ 1376 SrlDat17_PCSM_PDU: 8 Vector__XXX
 SG_ SrlDat17_PCSM : 7|64@0+ (1,0) [0|1.84467e+019] "" ACP2_MCU,ADIMa,ADIMb,VICM,ECM,EOCM,EOCM_HC_Superset,FCM,PCM,TCM,ECP_E

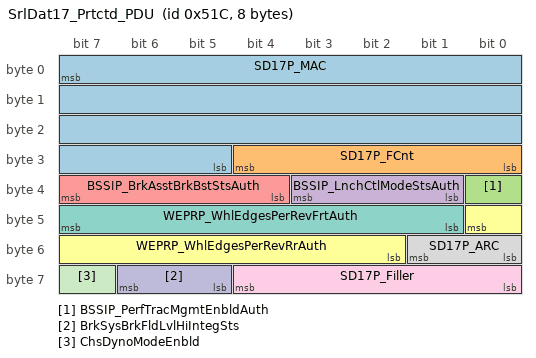
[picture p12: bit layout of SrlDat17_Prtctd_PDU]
BO_ 1308 SrlDat17_Prtctd_PDU: 8 Vector__XXX
 SG_ SD17P_MAC : 7|27@0+ (1,0) [0|1.34218e+008] "" ACP2_MCU,ADIMa,ADIMb,VICM,CGM,ECM,EOCM,EOCM_HC_Superset,FCM,PCM,TCM,ECP_E
 SG_ SD17P_FCnt : 28|5@0+ (1,0) [0|31] "" ACP2_MCU,ADIMa,ADIMb,VICM,CGM,ECM,EOCM,EOCM_HC_Superset,FCM,PCM,TCM,ECP_E
 SG_ BSSIP_PerfTracMgmtEnbldAuth : 32|1@0+ (1,0) [0|1] "" ACP2_MCU,ADIMa,ADIMb,VICM,CGM,ECM,EOCM,EOCM_HC_Superset,FCM,PCM,TCM,ECP_E
 SG_ BSSIP_LnchCtlModeStsAuth : 35|3@0+ (1,0) [0|7] "" ACP2_MCU,ADIMa,ADIMb,VICM,CGM,ECM,EOCM,EOCM_HC_Superset,FCM,PCM,TCM,ECP_E
 SG_ BSSIP_BrkAsstBrkBstStsAuth : 39|4@0+ (1,0) [0|9] "" ACP2_MCU,ADIMa,ADIMb,VICM,CGM,ECM,EOCM,EOCM_HC_Superset,FCM,PCM,TCM,ECP_E
 SG_ WEPRP_WhlEdgesPerRevRrAuth : 40|7@0+ (1,30) [30|157] "edges" ACP2_MCU,ADIMa,ADIMb,VICM,CGM,ECM,EOCM,EOCM_HC_Superset,EPS,EPSb,FCM,PCM,TCM,ECP_E
 SG_ WEPRP_WhlEdgesPerRevFrtAuth : 47|7@0+ (1,30) [30|157] "edges" ACP2_MCU,ADIMa,ADIMb,VICM,CGM,ECM,EOCM,EOCM_HC_Superset,EPS,EPSb,FCM,PCM,TCM,ECP_E
 SG_ SD17P_ARC : 49|2@0+ (1,0) [0|3] "" ACP2_MCU,ADIMa,ADIMb,VICM,CGM,ECM,EOCM,EOCM_HC_Superset,FCM,PCM,TCM,ECP_E
 SG_ SD17P_Filler : 60|5@0+ (1,0) [0|31] "" ACP2_MCU,ADIMa,ADIMb,VICM,CGM,ECM,EOCM,EOCM_HC_Superset,FCM,PCM,TCM,ECP_E
 SG_ BrkSysBrkFldLvlHiIntegSts : 62|2@0+ (1,0) [0|3] "" ACP2_MCU,ADIMa,ADIMb,VICM,CGM,ECM,EOCM,EOCM_HC_Superset,FCM,PCM,TCM,ECP_E
 SG_ ChsDynoModeEnbld : 63|1@0+ (1,0) [0|1] "" ACP2_MCU,ADIMa,ADIMb,VICM,CGM,ECM,EOCM,EOCM_HC_Superset,FCM,PCM,TCM,ECP_E

BO_ 538 Message1094_PDU: 8 Vector__XXX
 SG_ Sig6850 : 7|64@0+ (1,0) [0|1.84467e+019] "" FCM

BO_ 172 Message1095_PDU: 64 Vector__XXX
 SG_ Sig5673 : 5|8@0+ (1,0) [0|255] "" FCM
 SG_ Sig5672 : 7|2@0+ (1,0) [0|3] "" FCM
 SG_ Sig5885 : 8|7@0+ (1,0) [0|127] "" FCM
 SG_ Sig5884 : 11|3@0+ (1,0) [0|4] "" FCM
 SG_ Sig5883 : 13|2@0+ (1,0) [0|3] "" FCM
 SG_ Sig5886 : 17|6@0+ (2,0) [0|126] "%" FCM
 SG_ Sig5888 : 25|9@0- (0.125,0) [-32|31.875] "m/s^2" FCM
 SG_ Sig5887 : 27|2@0+ (1,0) [0|3] "" FCM
 SG_ Sig5889 : 32|10@0- (0.125,0) [-64|63.875] "m" FCM
 SG_ Sig5890 : 54|9@0- (0.125,0) [-32|31.875] "m/s" FCM
 SG_ Sig5891 : 61|9@0- (0.125,0) [-32|31.875] "m/s^2" FCM
 SG_ Sig5892 : 68|11@0- (0.125,0) [-128|127.875] "m" FCM
 SG_ Sig5893 : 73|10@0- (0.125,0) [-64|63.875] "m/s" FCM
 SG_ Sig5996 : 91|6@0+ (2,0) [0|126] "%" FCM
 SG_ Sig5895 : 93|2@0+ (1,0) [0|3] "" FCM
 SG_ Sig5894 : 95|2@0+ (1,0) [0|2] "" FCM
 SG_ Sig5999 : 96|1@0+ (1,0) [0|1] "" FCM
 SG_ Sig5998 : 99|3@0+ (1,0) [0|4] "" FCM
 SG_ Sig5997 : 101|2@0+ (1,0) [0|3] "" FCM
 SG_ Sig6001 : 104|2@0+ (1,0) [0|3] "" FCM
 SG_ Sig6000 : 111|7@0+ (1,0) [0|127] "" FCM
 SG_ Sig6004 : 118|9@0- (0.125,0) [-32|31.875] "m/s^2" FCM
 SG_ Sig6005 : 125|10@0- (0.125,0) [-64|63.875] "m" FCM
 SG_ Sig6006 : 131|14@0+ (0.01,0) [0|163.83] "m^2" FCM
 SG_ Sig6007 : 149|9@0- (0.125,0) [-32|31.875] "m/s" FCM
 SG_ Sig6008 : 156|10@0+ (0.125,0) [0|127.875] "(m/s)^2" FCM
 SG_ Sig6009 : 162|9@0- (0.125,0) [-32|31.875] "m/s^2" FCM
 SG_ Sig6010 : 169|11@0- (0.125,0) [-128|127.875] "m" FCM
 SG_ Sig6011 : 190|16@0+ (0.01,0) [0|655.35] "m^2" FCM
 SG_ Sig6012 : 206|11@0- (0.125,0) [-128|127.875] "m/s" FCM
 SG_ Sig6013 : 211|10@0+ (0.125,0) [0|127.875] "(m/s)^2" FCM
 SG_ Sig6015 : 217|2@0+ (1,0) [0|3] "" FCM
 SG_ Sig6017 : 225|2@0+ (1,0) [0|3] "" FCM
 SG_ Sig6016 : 231|6@0+ (2,0) [0|126] "%" FCM
 SG_ Sig6020 : 235|7@0+ (1,0) [0|127] "" FCM
 SG_ Sig6019 : 236|1@0+ (1,0) [0|1] "" FCM
 SG_ Sig6018 : 239|3@0+ (1,0) [0|4] "" FCM
 SG_ Sig6024 : 242|9@0- (0.125,0) [-32|31.875] "m/s^2" FCM
 SG_ Sig6021 : 244|2@0+ (1,0) [0|3] "" FCM
 SG_ Sig6025 : 249|10@0- (0.125,0) [-64|63.875] "m" FCM
 SG_ Sig6026 : 271|14@0+ (0.01,0) [0|163.83] "m^2" FCM
 SG_ Sig6027 : 273|9@0- (0.125,0) [-32|31.875] "m/s" FCM
 SG_ Sig6028 : 280|10@0+ (0.125,0) [0|127.875] "(m/s)^2" FCM
 SG_ Sig6029 : 302|9@0- (0.125,0) [-32|31.875] "m/s^2" FCM
 SG_ Sig6030 : 309|11@0- (0.125,0) [-128|127.875] "m" FCM
 SG_ Sig6031 : 314|16@0+ (0.01,0) [0|655.35] "m^2" FCM
 SG_ Sig6032 : 330|11@0- (0.125,0) [-128|127.875] "m/s" FCM
 SG_ Sig6033 : 351|10@0+ (0.125,0) [0|127.875] "(m/s)^2" FCM
 SG_ Sig6034 : 357|8@0+ (0.125,0) [0|31.875] "m" FCM
 SG_ Sig6036 : 363|6@0+ (2,0) [0|126] "%" FCM
 SG_ Sig6035 : 365|2@0+ (1,0) [0|3] "" FCM
 SG_ Sig6039 : 368|1@0+ (1,0) [0|1] "" FCM
 SG_ Sig6038 : 371|3@0+ (1,0) [0|4] "" FCM
 SG_ Sig6037 : 373|2@0+ (1,0) [0|3] "" FCM
 SG_ Sig6041 : 376|2@0+ (1,0) [0|3] "" FCM
 SG_ Sig6040 : 383|7@0+ (1,0) [0|127] "" FCM
 SG_ Sig6044 : 390|9@0- (0.125,0) [-32|31.875] "m/s^2" FCM
 SG_ Sig6045 : 397|10@0- (0.125,0) [-64|63.875] "m" FCM
 SG_ Sig6046 : 403|14@0+ (0.01,0) [0|163.83] "m^2" FCM
 SG_ Sig6047 : 421|9@0- (0.125,0) [-32|31.875] "m/s" FCM
 SG_ Sig6048 : 428|10@0+ (0.125,0) [0|127.875] "(m/s)^2" FCM
 SG_ Sig6049 : 434|9@0- (0.125,0) [-32|31.875] "m/s^2" FCM
 SG_ Sig6050 : 441|11@0- (0.125,0) [-128|127.875] "m" FCM
 SG_ Sig6051 : 462|16@0+ (0.01,0) [0|655.35] "m^2" FCM
 SG_ Sig6052 : 478|11@0- (0.125,0) [-128|127.875] "m/s" FCM
 SG_ Sig6053 : 483|10@0+ (0.125,0) [0|127.875] "(m/s)^2" FCM
 SG_ Sig6054 : 489|8@0+ (0.125,0) [0|31.875] "m" FCM
 SG_ Sig6055 : 497|2@0+ (1,0) [0|3] "" FCM
 SG_ Sig6074 : 511|8@0+ (0.125,0) [0|31.875] "m" FCM

BO_ 170 Message1096_PDU: 64 Vector__XXX
 SG_ Sig5675 : 5|8@0+ (1,0) [0|255] "" FCM
 SG_ Sig5674 : 7|2@0+ (1,0) [0|3] "" FCM
 SG_ Sig5898 : 8|7@0+ (1,0) [0|127] "" FCM
 SG_ Sig5897 : 11|3@0+ (1,0) [0|4] "" FCM
 SG_ Sig5896 : 13|2@0+ (1,0) [0|3] "" FCM
 SG_ Sig5899 : 17|6@0+ (2,0) [0|126] "%" FCM
 SG_ Sig5901 : 25|9@0- (0.125,0) [-32|31.875] "m/s^2" FCM
 SG_ Sig5900 : 27|2@0+ (1,0) [0|3] "" FCM
 SG_ Sig5902 : 32|10@0- (0.125,0) [-64|63.875] "m" FCM
 SG_ Sig5903 : 54|9@0- (0.125,0) [-32|31.875] "m/s" FCM
 SG_ Sig5904 : 61|9@0- (0.125,0) [-32|31.875] "m/s^2" FCM
 SG_ Sig5905 : 68|11@0- (0.125,0) [-128|127.875] "m" FCM
 SG_ Sig5906 : 73|10@0- (0.125,0) [-64|63.875] "m/s" FCM
 SG_ Sig6056 : 91|6@0+ (2,0) [0|126] "%" FCM
 SG_ Sig5908 : 93|2@0+ (1,0) [0|3] "" FCM
 SG_ Sig5907 : 95|2@0+ (1,0) [0|2] "" FCM
 SG_ Sig6059 : 96|1@0+ (1,0) [0|1] "" FCM
 SG_ Sig6058 : 99|3@0+ (1,0) [0|4] "" FCM
 SG_ Sig6057 : 101|2@0+ (1,0) [0|3] "" FCM
 SG_ Sig6061 : 104|2@0+ (1,0) [0|3] "" FCM
 SG_ Sig6060 : 111|7@0+ (1,0) [0|127] "" FCM
 SG_ Sig6064 : 118|9@0- (0.125,0) [-32|31.875] "m/s^2" FCM
 SG_ Sig6065 : 125|10@0- (0.125,0) [-64|63.875] "m" FCM
 SG_ Sig6066 : 131|14@0+ (0.01,0) [0|163.83] "m^2" FCM
 SG_ Sig6067 : 149|9@0- (0.125,0) [-32|31.875] "m/s" FCM
 SG_ Sig6068 : 156|10@0+ (0.125,0) [0|127.875] "(m/s)^2" FCM
 SG_ Sig6069 : 162|9@0- (0.125,0) [-32|31.875] "m/s^2" FCM
 SG_ Sig6070 : 169|11@0- (0.125,0) [-128|127.875] "m" FCM
 SG_ Sig6071 : 190|16@0+ (0.01,0) [0|655.35] "m^2" FCM
 SG_ Sig6072 : 206|11@0- (0.125,0) [-128|127.875] "m/s" FCM
 SG_ Sig6073 : 211|10@0+ (0.125,0) [0|127.875] "(m/s)^2" FCM
 SG_ Sig6075 : 217|2@0+ (1,0) [0|3] "" FCM
 SG_ Sig6077 : 225|2@0+ (1,0) [0|3] "" FCM
 SG_ Sig6076 : 231|6@0+ (2,0) [0|126] "%" FCM
 SG_ Sig6080 : 235|7@0+ (1,0) [0|127] "" FCM
 SG_ Sig6079 : 236|1@0+ (1,0) [0|1] "" FCM
 SG_ Sig6078 : 239|3@0+ (1,0) [0|4] "" FCM
 SG_ Sig6084 : 242|9@0- (0.125,0) [-32|31.875] "m/s^2" FCM
 SG_ Sig6081 : 244|2@0+ (1,0) [0|3] "" FCM
 SG_ Sig6085 : 249|10@0- (0.125,0) [-64|63.875] "m" FCM
 SG_ Sig6086 : 271|14@0+ (0.01,0) [0|163.83] "m^2" FCM
 SG_ Sig6087 : 273|9@0- (0.125,0) [-32|31.875] "m/s" FCM
 SG_ Sig6088 : 280|10@0+ (0.125,0) [0|127.875] "(m/s)^2" FCM
 SG_ Sig6089 : 302|9@0- (0.125,0) [-32|31.875] "m/s^2" FCM
 SG_ Sig6090 : 309|11@0- (0.125,0) [-128|127.875] "m" FCM
 SG_ Sig6091 : 314|16@0+ (0.01,0) [0|655.35] "m^2" FCM
 SG_ Sig6092 : 330|11@0- (0.125,0) [-128|127.875] "m/s" FCM
 SG_ Sig6093 : 351|10@0+ (0.125,0) [0|127.875] "(m/s)^2" FCM
 SG_ Sig6094 : 357|8@0+ (0.125,0) [0|31.875] "m" FCM
 SG_ Sig6096 : 363|6@0+ (2,0) [0|126] "%" FCM
 SG_ Sig6095 : 365|2@0+ (1,0) [0|3] "" FCM
 SG_ Sig6099 : 368|1@0+ (1,0) [0|1] "" FCM
 SG_ Sig6098 : 371|3@0+ (1,0) [0|4] "" FCM
 SG_ Sig6097 : 373|2@0+ (1,0) [0|3] "" FCM
 SG_ Sig6101 : 376|2@0+ (1,0) [0|3] "" FCM
 SG_ Sig6100 : 383|7@0+ (1,0) [0|127] "" FCM
 SG_ Sig6104 : 390|9@0- (0.125,0) [-32|31.875] "m/s^2" FCM
 SG_ Sig6105 : 397|10@0- (0.125,0) [-64|63.875] "m" FCM
 SG_ Sig6106 : 403|14@0+ (0.01,0) [0|163.83] "m^2" FCM
 SG_ Sig6107 : 421|9@0- (0.125,0) [-32|31.875] "m/s" FCM
 SG_ Sig6108 : 428|10@0+ (0.125,0) [0|127.875] "(m/s)^2" FCM
 SG_ Sig6109 : 434|9@0- (0.125,0) [-32|31.875] "m/s^2" FCM
 SG_ Sig6110 : 441|11@0- (0.125,0) [-128|127.875] "m" FCM
 SG_ Sig6111 : 462|16@0+ (0.01,0) [0|655.35] "m^2" FCM
 SG_ Sig6112 : 478|11@0- (0.125,0) [-128|127.875] "m/s" FCM
 SG_ Sig6113 : 483|10@0+ (0.125,0) [0|127.875] "(m/s)^2" FCM
 SG_ Sig6114 : 489|8@0+ (0.125,0) [0|31.875] "m" FCM
 SG_ Sig6115 : 497|2@0+ (1,0) [0|3] "" FCM
 SG_ Sig6134 : 511|8@0+ (0.125,0) [0|31.875] "m" FCM

BO_ 169 Message1097_PDU: 64 Vector__XXX
 SG_ Sig5677 : 5|16@0+ (1,0) [0|65535] "" FCM
 SG_ Sig5676 : 7|2@0+ (1,0) [0|3] "" FCM
 SG_ Sig5911 : 16|7@0+ (1,0) [0|127] "" FCM
 SG_ Sig5910 : 19|3@0+ (1,0) [0|4] "" FCM
 SG_ Sig5909 : 21|2@0+ (1,0) [0|3] "" FCM
 SG_ Sig5912 : 25|6@0+ (2,0) [0|126] "%" FCM
 SG_ Sig5914 : 33|9@0- (0.125,0) [-32|31.875] "m/s^2" FCM
 SG_ Sig5913 : 35|2@0+ (1,0) [0|3] "" FCM
 SG_ Sig5915 : 40|10@0- (0.125,0) [-64|63.875] "m" FCM
 SG_ Sig5916 : 62|9@0- (0.125,0) [-32|31.875] "m/s" FCM
 SG_ Sig5917 : 69|9@0- (0.125,0) [-32|31.875] "m/s^2" FCM
 SG_ Sig5918 : 76|11@0- (0.125,0) [-128|127.875] "m" FCM
 SG_ Sig5919 : 81|10@0- (0.125,0) [-64|63.875] "m/s" FCM
 SG_ Sig5956 : 99|6@0+ (2,0) [0|126] "%" FCM
 SG_ Sig5921 : 101|2@0+ (1,0) [0|3] "" FCM
 SG_ Sig5920 : 103|2@0+ (1,0) [0|2] "" FCM
 SG_ Sig5959 : 104|1@0+ (1,0) [0|1] "" FCM
 SG_ Sig5958 : 107|3@0+ (1,0) [0|4] "" FCM
 SG_ Sig5957 : 109|2@0+ (1,0) [0|3] "" FCM
 SG_ Sig5961 : 112|2@0+ (1,0) [0|3] "" FCM
 SG_ Sig5960 : 119|7@0+ (1,0) [0|127] "" FCM
 SG_ Sig5964 : 126|9@0- (0.125,0) [-32|31.875] "m/s^2" FCM
 SG_ Sig5965 : 133|10@0- (0.125,0) [-64|63.875] "m" FCM
 SG_ Sig5966 : 139|14@0+ (0.01,0) [0|163.83] "m^2" FCM
 SG_ Sig5967 : 157|9@0- (0.125,0) [-32|31.875] "m/s" FCM
 SG_ Sig5968 : 164|10@0+ (0.125,0) [0|127.875] "(m/s)^2" FCM
 SG_ Sig5969 : 170|9@0- (0.125,0) [-32|31.875] "m/s^2" FCM
 SG_ Sig5970 : 177|11@0- (0.125,0) [-128|127.875] "m" FCM
 SG_ Sig5971 : 198|16@0+ (0.01,0) [0|655.35] "m^2" FCM
 SG_ Sig5972 : 214|11@0- (0.125,0) [-128|127.875] "m/s" FCM
 SG_ Sig5973 : 219|10@0+ (0.125,0) [0|127.875] "(m/s)^2" FCM
 SG_ Sig5974 : 225|8@0+ (0.125,0) [0|31.875] "m" FCM
 SG_ Sig5975 : 233|2@0+ (1,0) [0|3] "" FCM
 SG_ Sig6117 : 241|2@0+ (1,0) [0|3] "" FCM
 SG_ Sig6116 : 247|6@0+ (2,0) [0|126] "%" FCM
 SG_ Sig6120 : 251|7@0+ (1,0) [0|127] "" FCM
 SG_ Sig6119 : 252|1@0+ (1,0) [0|1] "" FCM
 SG_ Sig6118 : 255|3@0+ (1,0) [0|4] "" FCM
 SG_ Sig6124 : 258|9@0- (0.125,0) [-32|31.875] "m/s^2" FCM
 SG_ Sig6121 : 260|2@0+ (1,0) [0|3] "" FCM
 SG_ Sig6125 : 265|10@0- (0.125,0) [-64|63.875] "m" FCM
 SG_ Sig6126 : 287|14@0+ (0.01,0) [0|163.83] "m^2" FCM
 SG_ Sig6127 : 289|9@0- (0.125,0) [-32|31.875] "m/s" FCM
 SG_ Sig6128 : 296|10@0+ (0.125,0) [0|127.875] "(m/s)^2" FCM
 SG_ Sig6129 : 318|9@0- (0.125,0) [-32|31.875] "m/s^2" FCM
 SG_ Sig6130 : 325|11@0- (0.125,0) [-128|127.875] "m" FCM
 SG_ Sig6131 : 330|16@0+ (0.01,0) [0|655.35] "m^2" FCM
 SG_ Sig6132 : 346|11@0- (0.125,0) [-128|127.875] "m/s" FCM
 SG_ Sig6133 : 367|10@0+ (0.125,0) [0|127.875] "(m/s)^2" FCM
 SG_ Sig6136 : 371|6@0+ (2,0) [0|126] "%" FCM
 SG_ Sig6135 : 373|2@0+ (1,0) [0|3] "" FCM
 SG_ Sig6139 : 376|1@0+ (1,0) [0|1] "" FCM
 SG_ Sig6138 : 379|3@0+ (1,0) [0|4] "" FCM
 SG_ Sig6137 : 381|2@0+ (1,0) [0|3] "" FCM
 SG_ Sig6141 : 384|2@0+ (1,0) [0|3] "" FCM
 SG_ Sig6140 : 391|7@0+ (1,0) [0|127] "" FCM
 SG_ Sig6144 : 398|9@0- (0.125,0) [-32|31.875] "m/s^2" FCM
 SG_ Sig6145 : 405|10@0- (0.125,0) [-64|63.875] "m" FCM
 SG_ Sig6146 : 411|14@0+ (0.01,0) [0|163.83] "m^2" FCM
 SG_ Sig6147 : 429|9@0- (0.125,0) [-32|31.875] "m/s" FCM
 SG_ Sig6148 : 436|10@0+ (0.125,0) [0|127.875] "(m/s)^2" FCM
 SG_ Sig6149 : 442|9@0- (0.125,0) [-32|31.875] "m/s^2" FCM
 SG_ Sig6150 : 449|11@0- (0.125,0) [-128|127.875] "m" FCM
 SG_ Sig6151 : 470|16@0+ (0.01,0) [0|655.35] "m^2" FCM
 SG_ Sig6152 : 486|11@0- (0.125,0) [-128|127.875] "m/s" FCM
 SG_ Sig6153 : 491|10@0+ (0.125,0) [0|127.875] "(m/s)^2" FCM
 SG_ Sig6154 : 497|8@0+ (0.125,0) [0|31.875] "m" FCM
 SG_ Sig6155 : 505|2@0+ (1,0) [0|3] "" FCM

BO_ 167 Message1098_PDU: 64 Vector__XXX
 SG_ Sig5679 : 5|10@0+ (1,0) [0|1023] "" FCM
 SG_ Sig5678 : 7|2@0+ (1,0) [0|3] "" FCM
 SG_ Sig5777 : 9|2@0+ (1,0) [0|3] "" FCM
 SG_ Sig5776 : 11|2@0+ (1,0) [0|3] "" FCM
 SG_ Sig5779 : 16|2@0+ (1,0) [0|3] "" FCM
 SG_ Sig5778 : 23|7@0+ (1,0) [0|127] "" FCM
 SG_ Sig5781 : 30|11@0- (0.125,0) [-128|127.875] "m" FCM
 SG_ Sig5783 : 32|2@0+ (1,0) [0|3] "" FCM
 SG_ Sig5782 : 35|3@0+ (1,0) [0|5] "" FCM
 SG_ Sig5786 : 42|7@0+ (1,0) [0|127] "" FCM
 SG_ Sig5785 : 44|2@0+ (1,0) [0|3] "" FCM
 SG_ Sig5784 : 46|2@0+ (1,0) [0|3] "" FCM
 SG_ Sig5789 : 49|11@0- (0.125,0) [-128|127.875] "m" FCM
 SG_ Sig5787 : 51|2@0+ (1,0) [0|3] "" FCM
 SG_ Sig5792 : 65|2@0+ (1,0) [0|3] "" FCM
 SG_ Sig5791 : 67|2@0+ (1,0) [0|3] "" FCM
 SG_ Sig5790 : 70|3@0+ (1,0) [0|5] "" FCM
 SG_ Sig5794 : 77|7@0+ (1,0) [0|127] "" FCM
 SG_ Sig5793 : 79|2@0+ (1,0) [0|3] "" FCM
 SG_ Sig5797 : 84|11@0- (0.125,0) [-128|127.875] "m" FCM
 SG_ Sig5795 : 86|2@0+ (1,0) [0|3] "" FCM
 SG_ Sig5798 : 89|3@0+ (1,0) [0|5] "" FCM
 SG_ Sig5802 : 96|7@0+ (1,0) [0|127] "" FCM
 SG_ Sig5801 : 98|2@0+ (1,0) [0|3] "" FCM
 SG_ Sig5800 : 100|2@0+ (1,0) [0|3] "" FCM
 SG_ Sig5799 : 102|2@0+ (1,0) [0|3] "" FCM
 SG_ Sig5803 : 105|2@0+ (1,0) [0|3] "" FCM
 SG_ Sig5805 : 119|11@0- (0.125,0) [-128|127.875] "m" FCM
 SG_ Sig5807 : 121|2@0+ (1,0) [0|3] "" FCM
 SG_ Sig5806 : 124|3@0+ (1,0) [0|5] "" FCM
 SG_ Sig5810 : 131|7@0+ (1,0) [0|127] "" FCM
 SG_ Sig5809 : 133|2@0+ (1,0) [0|3] "" FCM
 SG_ Sig5808 : 135|2@0+ (1,0) [0|3] "" FCM
 SG_ Sig5813 : 138|11@0- (0.125,0) [-128|127.875] "m" FCM
 SG_ Sig5811 : 140|2@0+ (1,0) [0|3] "" FCM
 SG_ Sig5817 : 152|2@0+ (1,0) [0|3] "" FCM
 SG_ Sig5816 : 154|2@0+ (1,0) [0|3] "" FCM
 SG_ Sig5815 : 156|2@0+ (1,0) [0|3] "" FCM
 SG_ Sig5814 : 159|3@0+ (1,0) [0|5] "" FCM
 SG_ Sig5818 : 166|7@0+ (1,0) [0|127] "" FCM
 SG_ Sig5821 : 173|11@0- (0.125,0) [-128|127.875] "m" FCM
 SG_ Sig5819 : 175|2@0+ (1,0) [0|3] "" FCM
 SG_ Sig5822 : 178|3@0+ (1,0) [0|5] "" FCM
 SG_ Sig5826 : 185|7@0+ (1,0) [0|127] "" FCM
 SG_ Sig5825 : 187|2@0+ (1,0) [0|3] "" FCM
 SG_ Sig5824 : 189|2@0+ (1,0) [0|3] "" FCM
 SG_ Sig5823 : 191|2@0+ (1,0) [0|3] "" FCM
 SG_ Sig5829 : 192|11@0- (0.125,0) [-128|127.875] "m" FCM
 SG_ Sig5827 : 194|2@0+ (1,0) [0|3] "" FCM
 SG_ Sig5832 : 208|2@0+ (1,0) [0|3] "" FCM
 SG_ Sig5831 : 210|2@0+ (1,0) [0|3] "" FCM
 SG_ Sig5830 : 213|3@0+ (1,0) [0|5] "" FCM
 SG_ Sig5834 : 220|7@0+ (1,0) [0|127] "" FCM
 SG_ Sig5833 : 222|2@0+ (1,0) [0|3] "" FCM
 SG_ Sig5837 : 227|11@0- (0.125,0) [-128|127.875] "m" FCM
 SG_ Sig5835 : 229|2@0+ (1,0) [0|3] "" FCM
 SG_ Sig5838 : 232|3@0+ (1,0) [0|5] "" FCM
 SG_ Sig5841 : 241|2@0+ (1,0) [0|3] "" FCM
 SG_ Sig5840 : 243|2@0+ (1,0) [0|3] "" FCM
 SG_ Sig5839 : 245|2@0+ (1,0) [0|3] "" FCM
 SG_ Sig5843 : 248|2@0+ (1,0) [0|3] "" FCM
 SG_ Sig5842 : 255|7@0+ (1,0) [0|127] "" FCM
 SG_ Sig5845 : 262|11@0- (0.125,0) [-128|127.875] "m" FCM
 SG_ Sig5847 : 264|2@0+ (1,0) [0|3] "" FCM
 SG_ Sig5846 : 267|3@0+ (1,0) [0|5] "" FCM
 SG_ Sig5850 : 274|7@0+ (1,0) [0|127] "" FCM
 SG_ Sig5849 : 276|2@0+ (1,0) [0|3] "" FCM
 SG_ Sig5848 : 278|2@0+ (1,0) [0|3] "" FCM
 SG_ Sig5853 : 281|11@0- (0.125,0) [-128|127.875] "m" FCM
 SG_ Sig5851 : 283|2@0+ (1,0) [0|3] "" FCM
 SG_ Sig5962 : 297|10@0- (0.125,0) [-64|63.875] "m" FCM
 SG_ Sig5855 : 299|2@0+ (1,0) [0|3] "" FCM
 SG_ Sig5854 : 302|3@0+ (1,0) [0|5] "" FCM
 SG_ Sig5963 : 319|11@0- (0.125,0) [-128|127.875] "m" FCM
 SG_ Sig5982 : 324|10@0- (0.125,0) [-64|63.875] "m" FCM
 SG_ Sig5983 : 330|11@0- (0.125,0) [-128|127.875] "m" FCM
 SG_ Sig6002 : 351|10@0- (0.125,0) [-64|63.875] "m" FCM
 SG_ Sig6003 : 357|11@0- (0.125,0) [-128|127.875] "m" FCM
 SG_ Sig6022 : 362|10@0- (0.125,0) [-64|63.875] "m" FCM
 SG_ Sig6023 : 368|11@0- (0.125,0) [-128|127.875] "m" FCM
 SG_ Sig6042 : 389|10@0- (0.125,0) [-64|63.875] "m" FCM
 SG_ Sig6043 : 395|11@0- (0.125,0) [-128|127.875] "m" FCM
 SG_ Sig6062 : 400|10@0- (0.125,0) [-64|63.875] "m" FCM
 SG_ Sig6063 : 422|11@0- (0.125,0) [-128|127.875] "m" FCM
 SG_ Sig6082 : 427|10@0- (0.125,0) [-64|63.875] "m" FCM
 SG_ Sig6083 : 433|11@0- (0.125,0) [-128|127.875] "m" FCM
 SG_ Sig6102 : 454|10@0- (0.125,0) [-64|63.875] "m" FCM
 SG_ Sig6103 : 460|11@0- (0.125,0) [-128|127.875] "m" FCM
 SG_ Sig6122 : 465|10@0- (0.125,0) [-64|63.875] "m" FCM
 SG_ Sig6123 : 487|11@0- (0.125,0) [-128|127.875] "m" FCM
 SG_ Sig6142 : 492|10@0- (0.125,0) [-64|63.875] "m" FCM
 SG_ Sig6143 : 498|11@0- (0.125,0) [-128|127.875] "m" FCM

BA_DEF_ SG_  "SignalType" STRING ;
BA_DEF_ SG_  "SignalLongName" STRING ;
BA_DEF_ BO_  "GenMsgCycleTime" INT 0 10000;
BA_DEF_ BO_  "GenMsgSendType" ENUM "cyclicX","spontanX","cyclicIfActiveX","spontanWithDelay","cyclicAndSpontanX","cyclicAndSpontanWithDelay","spontanWithRepetition","cyclicIfActiveAndSpontanWD";
BA_DEF_ BO_  "VFrameFormat" ENUM  "StandardCAN","ExtendedCAN","reserved","reserved","reserved","reserved","reserved","reserved","reserved","reserved","reserved","reserved","reserved","reserved","StandardCAN_FD","ExtendedCAN_FD";
BA_DEF_DEF_  "SignalType" "";
BA_DEF_DEF_  "SignalLongName" "";
BA_DEF_DEF_  "GenMsgCycleTime" 0;
BA_DEF_DEF_  "GenMsgSendType" "cyclicX";
BA_DEF_DEF_  "VFrameFormat" "StandardCAN";
BA_ "GenMsgCycleTime" BO_ 49 12.5;
BA_ "VFrameFormat" BO_ 49 14;
BA_ "GenMsgCycleTime" BO_ 1381 3500;
BA_ "VFrameFormat" BO_ 1381 14;
BA_ "GenMsgCycleTime" BO_ 1320 1000;
BA_ "GenMsgCycleTime" BO_ 97 10;
BA_ "VFrameFormat" BO_ 97 14;
BA_ "GenMsgCycleTime" BO_ 1399 1000;
BA_ "VFrameFormat" BO_ 1399 14;
BA_ "GenMsgCycleTime" BO_ 870 250;
BA_ "VFrameFormat" BO_ 870 14;
BA_ "GenMsgCycleTime" BO_ 2147745823 1000;
BA_ "VFrameFormat" BO_ 912 14;
BA_ "GenMsgCycleTime" BO_ 60 10;
BA_ "VFrameFormat" BO_ 60 14;
BA_ "GenMsgCycleTime" BO_ 1380 1000;
BA_ "VFrameFormat" BO_ 1380 14;
BA_ "GenMsgCycleTime" BO_ 874 250;
BA_ "VFrameFormat" BO_ 874 14;
BA_ "VFrameFormat" BO_ 911 14;
BA_ "GenMsgCycleTime" BO_ 88 10;
BA_ "VFrameFormat" BO_ 88 14;
BA_ "GenMsgCycleTime" BO_ 1379 1000;
BA_ "VFrameFormat" BO_ 1379 14;
BA_ "GenMsgCycleTime" BO_ 868 250;
BA_ "VFrameFormat" BO_ 868 14;
BA_ "GenMsgCycleTime" BO_ 1317 1000;
BA_ "VFrameFormat" BO_ 1317 14;
BA_ "GenMsgCycleTime" BO_ 1378 3500;
BA_ "VFrameFormat" BO_ 1378 14;
BA_ "GenMsgCycleTime" BO_ 1309 1000;
BA_ "VFrameFormat" BO_ 1309 14;
BA_ "GenMsgCycleTime" BO_ 1327 3500;
BA_ "VFrameFormat" BO_ 1327 14;
BA_ "GenMsgCycleTime" BO_ 1277 1000;
BA_ "VFrameFormat" BO_ 1277 14;
BA_ "VFrameFormat" BO_ 910 14;
BA_ "GenMsgCycleTime" BO_ 48 12.5;
BA_ "VFrameFormat" BO_ 48 14;
BA_ "GenMsgCycleTime" BO_ 1152 3500;
BA_ "VFrameFormat" BO_ 1152 14;
BA_ "GenMsgCycleTime" BO_ 1149 1000;
BA_ "VFrameFormat" BO_ 1149 14;
BA_ "VFrameFormat" BO_ 972 14;
BA_ "GenMsgCycleTime" BO_ 586 100;
BA_ "VFrameFormat" BO_ 586 14;
BA_ "VFrameFormat" BO_ 967 14;
BA_ "GenMsgCycleTime" BO_ 591 100;
BA_ "VFrameFormat" BO_ 591 14;
BA_ "VFrameFormat" BO_ 969 14;
BA_ "GenMsgCycleTime" BO_ 590 100;
BA_ "VFrameFormat" BO_ 590 14;
BA_ "VFrameFormat" BO_ 970 14;
BA_ "GenMsgCycleTime" BO_ 588 100;
BA_ "VFrameFormat" BO_ 588 14;
BA_ "VFrameFormat" BO_ 740 14;
BA_ "GenMsgCycleTime" BO_ 29 6.25;
BA_ "VFrameFormat" BO_ 29 14;
BA_ "GenMsgCycleTime" BO_ 1446 1000;
BA_ "VFrameFormat" BO_ 1446 14;
BA_ "VFrameFormat" BO_ 971 14;
BA_ "GenMsgCycleTime" BO_ 587 100;
BA_ "VFrameFormat" BO_ 587 14;
BA_ "GenMsgCycleTime" BO_ 1145 1000;
BA_ "VFrameFormat" BO_ 1145 14;
BA_ "GenMsgCycleTime" BO_ 1377 1000;
BA_ "VFrameFormat" BO_ 1377 14;
BA_ "GenMsgCycleTime" BO_ 873 250;
BA_ "VFrameFormat" BO_ 873 14;
BA_ "VFrameFormat" BO_ 694 14;
BA_ "GenMsgCycleTime" BO_ 635 100;
BA_ "VFrameFormat" BO_ 635 14;
BA_ "VFrameFormat" BO_ 974 14;
BA_ "GenMsgCycleTime" BO_ 644 100;
BA_ "VFrameFormat" BO_ 644 14;
BA_ "VFrameFormat" BO_ 975 14;
BA_ "GenMsgCycleTime" BO_ 602 100;
BA_ "VFrameFormat" BO_ 602 14;
BA_ "VFrameFormat" BO_ 917 14;
BA_ "GenMsgCycleTime" BO_ 171 50;
BA_ "VFrameFormat" BO_ 171 14;
BA_ "GenMsgCycleTime" BO_ 749 100;
BA_ "VFrameFormat" BO_ 749 14;
BA_ "GenMsgCycleTime" BO_ 747 100;
BA_ "VFrameFormat" BO_ 747 14;
BA_ "VFrameFormat" BO_ 909 14;
BA_ "GenMsgCycleTime" BO_ 59 10;
BA_ "VFrameFormat" BO_ 59 14;
BA_ "GenMsgCycleTime" BO_ 1342 3500;
BA_ "VFrameFormat" BO_ 1342 14;
BA_ "GenMsgCycleTime" BO_ 1290 1000;
BA_ "VFrameFormat" BO_ 1290 14;
BA_ "GenMsgCycleTime" BO_ 1291 3500;
BA_ "VFrameFormat" BO_ 1291 14;
BA_ "GenMsgCycleTime" BO_ 1286 1000;
BA_ "VFrameFormat" BO_ 1286 14;
BA_ "GenMsgCycleTime" BO_ 1376 3500;
BA_ "VFrameFormat" BO_ 1376 14;
BA_ "GenMsgCycleTime" BO_ 1308 1000;
BA_ "VFrameFormat" BO_ 1308 14;
BA_ "VFrameFormat" BO_ 538 14;
BA_ "VFrameFormat" BO_ 172 14;
BA_ "VFrameFormat" BO_ 170 14;
BA_ "VFrameFormat" BO_ 169 14;
BA_ "VFrameFormat" BO_ 167 14;
BA_ "SignalLongName" SG_ 49 PGI3P_MAC "Propulsion General Information 3 Protected : MAC";
BA_ "SignalLongName" SG_ 49 PGI3P_FCnt "Propulsion General Information 3 Protected : Freshness Counter";
BA_ "SignalType" SG_ 49 PGI3P_PrplCpbltyStsPriAuth "ENM";
BA_ "SignalLongName" SG_ 49 PGI3P_PrplCpbltyStsPriAuth "Propulsion General Information 3 Protected : Propulsion Capability Status Primary Authenticated";
BA_ "SignalType" SG_ 49 PGI3P_PrplArbtrtnStsPriAuth "ENM";
BA_ "SignalLongName" SG_ 49 PGI3P_PrplArbtrtnStsPriAuth "Propulsion General Information 3 Protected : Propulsion Arbitration Status Primary Authenticated";
BA_ "SignalType" SG_ 49 PGI3P_ADSRedntATReqStsPriAuth "ENM";
BA_ "SignalLongName" SG_ 49 PGI3P_ADSRedntATReqStsPriAuth "Propulsion General Information 3 Protected : Autonomous Driving System Redundant Axle Torque Request Status Primary Authenticated";
BA_ "SignalType" SG_ 49 PGI3P_ADSMnAxlTrqReqStsPriAuth "ENM";
BA_ "SignalLongName" SG_ 49 PGI3P_ADSMnAxlTrqReqStsPriAuth "Propulsion General Information 3 Protected : Autonomous Driving System Main Axle Torque Request Status Primary Authenticated";
BA_ "SignalType" SG_ 49 PrplSysFricBrkTrqReqTypAuth "ENM";
BA_ "SignalLongName" SG_ 49 PrplSysFricBrkTrqReqTypAuth "Propulsion General Information 3 Protected : Propulsion System Friction Brake Torque Request Type Authenticated";
BA_ "SignalLongName" SG_ 49 PGI3P_ARC "Propulsion General Information 3 Protected : Alive Rolling Count";
BA_ "SignalType" SG_ 49 PGI3P_PrplSysStsPriAuth "ENM";
BA_ "SignalLongName" SG_ 49 PGI3P_PrplSysStsPriAuth "Propulsion General Information 3 Protected : Propulsion System Status Primary Authenticated";
BA_ "SignalLongName" SG_ 49 PrplSysFricBrkTrqReqValAuth "Propulsion General Information 3 Protected : Propulsion System Friction Brake Torque Request Value Authenticated";
BA_ "SignalLongName" SG_ 49 PGI3P_Filler "Propulsion General Information 3 Protected : Filler";
BA_ "SignalLongName" SG_ 1381 PstClsnInfo_PCSM "Post Collision Information Protected Counter Sync Message";
BA_ "SignalLongName" SG_ 1320 PCIP_MAC "Post Collision Information Protected : MAC";
BA_ "SignalLongName" SG_ 1320 PCIP_FCnt "Post Collision Information Protected : Freshness Counter";
BA_ "SignalType" SG_ 1320 PCIP_HzrdLgtsOnReqdAuth "ENM";
BA_ "SignalLongName" SG_ 1320 PCIP_HzrdLgtsOnReqdAuth "Post Collision Information Protected : Hazard Lights On Requested Authenticated";
BA_ "SignalType" SG_ 1320 PCIP_HybVehHiVltgDsblReqdAuth "ENM";
BA_ "SignalLongName" SG_ 1320 PCIP_HybVehHiVltgDsblReqdAuth "Post Collision Information Protected : High Voltage System Disable Requested Authenticated";
BA_ "SignalType" SG_ 1320 PCIP_HVCrshImpSnsSysDsbldAuth "ENM";
BA_ "SignalLongName" SG_ 1320 PCIP_HVCrshImpSnsSysDsbldAuth "Post Collision Information Protected : High Voltage Crash Impact Sensing System Disabled Authenticated";
BA_ "SignalType" SG_ 1320 PCIP_HVACBlwDsblReqdAuth "ENM";
BA_ "SignalLongName" SG_ 1320 PCIP_HVACBlwDsblReqdAuth "Post Collision Information Protected : HVAC Blower Disable Requested Authenticated";
BA_ "SignalType" SG_ 1320 PCIP_FuelCutOffReqdAuth "ENM";
BA_ "SignalLongName" SG_ 1320 PCIP_FuelCutOffReqdAuth "Post Collision Information Protected : Fuel Cut Off Requested Authenticated";
BA_ "SignalType" SG_ 1320 PCIP_DrUnlckReqdAuth "ENM";
BA_ "SignalLongName" SG_ 1320 PCIP_DrUnlckReqdAuth "Post Collision Information Protected : Door Unlock Requested Authenticated";
BA_ "SignalType" SG_ 1320 PCIP_CruzCtlDsblReqdAuth "ENM";
BA_ "SignalLongName" SG_ 1320 PCIP_CruzCtlDsblReqdAuth "Post Collision Information Protected : Cruise Control Disable Requested Authenticated";
BA_ "SignalType" SG_ 1320 PCIP_BrkActReqdAuth "ENM";
BA_ "SignalLongName" SG_ 1320 PCIP_BrkActReqdAuth "Post Collision Information Protected : Brake Actuation Requested Authenticated";
BA_ "SignalLongName" SG_ 1320 PCIP_NtfnEvntCntAuth "Post Collision Information Protected : Notification Event Counter Authenticated";
BA_ "SignalType" SG_ 1320 PCIP_NftnFrtImpPrtnsrSevAchAuth "ENM";
BA_ "SignalLongName" SG_ 1320 PCIP_NftnFrtImpPrtnsrSevAchAuth "Post Collision Information Protected : Notification Frontal Impact Pretensioner Severity Achieved Authenticated";
BA_ "SignalType" SG_ 1320 PCIP_MemStRclDsblReqdAuth "ENM";
BA_ "SignalLongName" SG_ 1320 PCIP_MemStRclDsblReqdAuth "Post Collision Information Protected : Memory Seat Recall Disable Requested Authenticated";
BA_ "SignalType" SG_ 1320 PCIP_IntrLgtOnReqdAuth "ENM";
BA_ "SignalLongName" SG_ 1320 PCIP_IntrLgtOnReqdAuth "Post Collision Information Protected : Interior Light On Requested Authenticated";
BA_ "SignalType" SG_ 1320 PCIP_NtfnLtSdSevAchvdAuth "ENM";
BA_ "SignalLongName" SG_ 1320 PCIP_NtfnLtSdSevAchvdAuth "Post Collision Information Protected : Notification Left Side Severity Achieved Authenticated";
BA_ "SignalType" SG_ 1320 PCIP_NtfnFrtImpStg2SevAchvdAuth "ENM";
BA_ "SignalLongName" SG_ 1320 PCIP_NtfnFrtImpStg2SevAchvdAuth "Post Collision Information Protected : Notification Frontal Impact Stage2 Severity Achieved Authenticated";
BA_ "SignalType" SG_ 1320 PCIP_NtfnFrtImpStg1SevAchvdAuth "ENM";
BA_ "SignalLongName" SG_ 1320 PCIP_NtfnFrtImpStg1SevAchvdAuth "Post Collision Information Protected : Notification Frontal Impact Stage1 Severity Achieved Authenticated";
BA_ "SignalType" SG_ 1320 PCIP_NtfnEvntStsAuth "ENM";
BA_ "SignalLongName" SG_ 1320 PCIP_NtfnEvntStsAuth "Post Collision Information Protected : Notification Event Status Authenticated";
BA_ "SignalLongName" SG_ 1320 PCIP_Filler "Post Collision Information Protected : Filler";
BA_ "SignalLongName" SG_ 1320 PCIP_ARC "Post Collision Information Protected : Alive Rolling Count";
BA_ "SignalType" SG_ 1320 PCIP_eCallReqdAuth "ENM";
BA_ "SignalLongName" SG_ 1320 PCIP_eCallReqdAuth "Post Collision Information Protected : eCall Requested Authenticated";
BA_ "SignalType" SG_ 1320 PCIP_NtfnRtSdSevAchvdAuth "ENM";
BA_ "SignalLongName" SG_ 1320 PCIP_NtfnRtSdSevAchvdAuth "Post Collision Information Protected : Notification Right Side Severity Achieved Authenticated";
BA_ "SignalType" SG_ 1320 PCIP_NtfnRrImpSevAchvdAuth "ENM";
BA_ "SignalLongName" SG_ 1320 PCIP_NtfnRrImpSevAchvdAuth "Post Collision Information Protected : Notification Rear Impact Severity Achieved Authenticated";
BA_ "SignalType" SG_ 1320 PCIP_NtfnRlOvrSevAchvdAuth "ENM";
BA_ "SignalLongName" SG_ 1320 PCIP_NtfnRlOvrSevAchvdAuth "Post Collision Information Protected : Notification Roll Over Severity Achieved Authenticated";
BA_ "SignalType" SG_ 1320 PCIP_NtfnPedtrnPrtctnSevAchAuth "ENM";
BA_ "SignalLongName" SG_ 1320 PCIP_NtfnPedtrnPrtctnSevAchAuth "Post Collision Information Protected : Notification Pedpro Severity Achieved Authenticated";
BA_ "SignalLongName" SG_ 97 POFT_PstnOfstFrmTrmLF "Position Offset From Trim : Position Offset From Trim Left Front";
BA_ "SignalLongName" SG_ 97 POFT_PstnOfstFrmTrmLR "Position Offset From Trim : Position Offset From Trim Left Rear";
BA_ "SignalType" SG_ 97 POFT_PstnOfstFrmTrmLF_Inv "ENM";
BA_ "SignalLongName" SG_ 97 POFT_PstnOfstFrmTrmLF_Inv "Position Offset From Trim : Position Offset From Trim Left Front Invalid";
BA_ "SignalLongName" SG_ 97 POFT_PstnOfstFrmTrmRF "Position Offset From Trim : Position Offset From Trim Right Front";
BA_ "SignalType" SG_ 97 POFT_PstnOfstFrmTrmLR_Inv "ENM";
BA_ "SignalLongName" SG_ 97 POFT_PstnOfstFrmTrmLR_Inv "Position Offset From Trim : Position Offset From Trim Left Rear Invalid";
BA_ "SignalLongName" SG_ 97 POFT_PstnOfstFrmTrmRR "Position Offset From Trim : Position Offset From Trim Right Rear";
BA_ "SignalType" SG_ 97 POFT_PstnOfstFrmTrmRF_Inv "ENM";
BA_ "SignalLongName" SG_ 97 POFT_PstnOfstFrmTrmRF_Inv "Position Offset From Trim : Position Offset From Trim Right Front Invalid";
BA_ "SignalType" SG_ 97 POFT_PstnOfstFrmTrmRR_Inv "ENM";
BA_ "SignalLongName" SG_ 97 POFT_PstnOfstFrmTrmRR_Inv "Position Offset From Trim : Position Offset From Trim Right Rear Invalid";
BA_ "SignalType" SG_ 97 POFT_SpnsnTrmPstnLrnCmplt "ENM";
BA_ "SignalLongName" SG_ 97 POFT_SpnsnTrmPstnLrnCmplt "Position Offset From Trim : Suspension Trim Position Learn Complete";
BA_ "SignalLongName" SG_ 97 POFT_CS "Position Offset From Trim : Checksum";
BA_ "SignalLongName" SG_ 97 POFT_ARC "Position Offset From Trim : Alive Rolling Count";
BA_ "SignalLongName" SG_ 1399 PwrStrgInfo_PCSM "Power Steering Information Protected Counter Sync Message";
BA_ "SignalLongName" SG_ 870 PSIP_MAC "Power Steering Information Protected : MAC";
BA_ "SignalLongName" SG_ 870 PSIP_FCnt "Power Steering Information Protected : Freshness Counter";
BA_ "SignalLongName" SG_ 870 PSIP_ARC "Power Steering Information Protected : Alive Rolling Count";
BA_ "SignalType" SG_ 870 PSIP_StrgAsstRdcdLvl3IndOnAuth "ENM";
BA_ "SignalLongName" SG_ 870 PSIP_StrgAsstRdcdLvl3IndOnAuth "Power Steering Information Protected : Steering Assist Reduced Level 3 Indication On Authenticated";
BA_ "SignalType" SG_ 870 PSIP_StrgAsstRdcdLvl2IndOnAuth "ENM";
BA_ "SignalLongName" SG_ 870 PSIP_StrgAsstRdcdLvl2IndOnAuth "Power Steering Information Protected : Steering Assist Reduced Level 2 Indication On Authenticated";
BA_ "SignalType" SG_ 870 PSIP_StrgAsstRdcdIndOnAuth "ENM";
BA_ "SignalLongName" SG_ 870 PSIP_StrgAsstRdcdIndOnAuth "Power Steering Information Protected : Steering Assist Reduced Indication On Authenticated";
BA_ "SignalType" SG_ 870 PSIP_PwrStrgIndOnAuth "ENM";
BA_ "SignalLongName" SG_ 870 PSIP_PwrStrgIndOnAuth "Power Steering Information Protected : Power Steering Indication On Authenticated";
BA_ "SignalType" SG_ 2147745823 Sig5023 "ENM";
BA_ "SignalLongName" SG_ 2147745823 Sig5023 "Signal5101";
BA_ "SignalLongName" SG_ 912 RrAxTrqValCmd_PCSM "Rear Axle Torque Value Command Protected Counter Sync Message";
BA_ "SignalLongName" SG_ 60 RATVCP_MAC "Rear Axle Torque Value Command Protected : MAC";
BA_ "SignalLongName" SG_ 60 RATVCP_FCnt "Rear Axle Torque Value Command Protected : Freshness Counter";
BA_ "SignalLongName" SG_ 60 RATVCP_RrAxTrqValCmdAuth "Rear Axle Torque Value Command Protected : Rear Axle Torque Value Command Authenticated";
BA_ "SignalLongName" SG_ 60 RATVCP_Filler "Rear Axle Torque Value Command Protected : Filler";
BA_ "SignalLongName" SG_ 60 RATVCP_ARC "Rear Axle Torque Value Command Protected : Alive Rolling Count";
BA_ "SignalLongName" SG_ 1380 SecAxlTrqCplRqTy_PCSM "Secondary Axle Locking Torque Request Coupling Request Type Protected Counter Sync Message";
BA_ "SignalLongName" SG_ 874 SATCRTP_MAC "Secondary Axle Locking Torque Request Coupling Request Type Protected : MAC";
BA_ "SignalLongName" SG_ 874 SATCRTP_FCnt "Secondary Axle Locking Torque Request Coupling Request Type Protected : Freshness Counter";
BA_ "SignalLongName" SG_ 874 SALTRCRTP_Filler "Secondary Axle Locking Torque Request Coupling Request Type Protected : Filler";
BA_ "SignalLongName" SG_ 874 SATCRTP_ARC "Secondary Axle Locking Torque Request Coupling Request Type Protected : Alive Rolling Count";
BA_ "SignalType" SG_ 874 SATCRTP_SecAxlTrqCplRqTyAuth "ENM";
BA_ "SignalLongName" SG_ 874 SATCRTP_SecAxlTrqCplRqTyAuth "Secondary Axle Locking Torque Request Coupling Request Type Protected : Secondary Axle Locking Torque Request Coupling Request Type Authenticated";
BA_ "SignalLongName" SG_ 911 SecAxl_PCSM "Secondary Axle Protected Counter Sync Message";
BA_ "SignalLongName" SG_ 88 SAP_MAC "Secondary Axle Protected : MAC";
BA_ "SignalLongName" SG_ 88 SAP_FCnt "Secondary Axle Protected : Freshness Counter";
BA_ "SignalLongName" SG_ 88 SAP_SecAxl4WDAWDEstTrqAuth "Secondary Axle Protected : Secondary Axle 4WD AWD Estimated Torque Authenticated";
BA_ "SignalType" SG_ 88 SAP_PwrtrnXferCaseModeAuth "ENM";
BA_ "SignalLongName" SG_ 88 SAP_PwrtrnXferCaseModeAuth "Secondary Axle Protected : Powertrain Transfer Case Mode Authenticated";
BA_ "SignalType" SG_ 88 SAP_SecAxlOpMdAuth "ENM";
BA_ "SignalLongName" SG_ 88 SAP_SecAxlOpMdAuth "Secondary Axle Protected : Secondary Axle Operational Mode Authenticated";
BA_ "SignalType" SG_ 88 SAP_SecAxl4WDAWDStatAuth "ENM";
BA_ "SignalLongName" SG_ 88 SAP_SecAxl4WDAWDStatAuth "Secondary Axle Protected : Secondary Axle 4WD AWD Status Authenticated";
BA_ "SignalType" SG_ 88 SAP_SecAxl4WDAWDEstTrqAuth_Inv "ENM";
BA_ "SignalLongName" SG_ 88 SAP_SecAxl4WDAWDEstTrqAuth_Inv "Secondary Axle Protected : Secondary Axle 4WD AWD Estimated Torque Authenticated Invalid";
BA_ "SignalLongName" SG_ 88 SAP_ARC "Secondary Axle Protected : Alive Rolling Count";
BA_ "SignalType" SG_ 88 SAP_XferCaseRngShfPndgAuth "ENM";
BA_ "SignalLongName" SG_ 88 SAP_XferCaseRngShfPndgAuth "Secondary Axle Protected : Transfer Case Range Shift Pending Authenticated";
BA_ "SignalType" SG_ 88 SAP_SecAxlOpMdAuth_Inv "ENM";
BA_ "SignalLongName" SG_ 88 SAP_SecAxlOpMdAuth_Inv "Secondary Axle Protected : Secondary Axle Operational Mode Authenticated Invalid";
BA_ "SignalLongName" SG_ 88 SAP_Filler "Secondary Axle Protected : Filler";
BA_ "SignalLongName" SG_ 1379 SemiAtvDmpgSysVhTpSpdLim_PCSM "Semi Active Damping System Vehicle Top Speed Limit Protected Counter Sync Message";
BA_ "SignalLongName" SG_ 868 SADSVTSLP_MAC "Semi Active Damping System Vehicle Top Speed Limit Protected : MAC";
BA_ "SignalLongName" SG_ 868 SADSVTSLP_FCnt "Semi Active Damping System Vehicle Top Speed Limit Protected : Freshness Counter";
BA_ "SignalLongName" SG_ 868 SADSVTSLP_VehTpSpdLimReqValAuth "Semi Active Damping System Vehicle Top Speed Limit Protected : Vehicle Top Speed Limit Request Value Authenticated";
BA_ "SignalType" SG_ 868 SADSVTSLP_VehTpSpdLimReqTypAuth "ENM";
BA_ "SignalLongName" SG_ 868 SADSVTSLP_VehTpSpdLimReqTypAuth "Semi Active Damping System Vehicle Top Speed Limit Protected : Vehicle Top Speed Limit Request Type Authenticated";
BA_ "SignalLongName" SG_ 868 SADSVTSLP_Filler "Semi Active Damping System Vehicle Top Speed Limit Protected : Filler";
BA_ "SignalLongName" SG_ 868 SADSVTSLP_ARC "Semi Active Damping System Vehicle Top Speed Limit Protected : Alive Rolling Count";
BA_ "SignalLongName" SG_ 1317 SLVFSP_MAC "Speed Limit Vision Fused Speed Protected : MAC";
BA_ "SignalLongName" SG_ 1317 SLVFSP_FCnt "Speed Limit Vision Fused Speed Protected : Freshness Counter";
BA_ "SignalLongName" SG_ 1317 SLVFSP_SpdLimVsnFsdSpdAuth "Speed Limit Vision Fused Speed Protected : Speed Limit Vision Fused Speed Authenticated";
BA_ "SignalLongName" SG_ 1317 SLVFSP_Filler "Speed Limit Vision Fused Speed Protected : Filler";
BA_ "SignalLongName" SG_ 1317 SLVFSP_ARC "Speed Limit Vision Fused Speed Protected : Alive Rolling Count";
BA_ "SignalType" SG_ 1317 SLVFSP_SpdLimVsnFsdSpdUntAuth "ENM";
BA_ "SignalLongName" SG_ 1317 SLVFSP_SpdLimVsnFsdSpdUntAuth "Speed Limit Vision Fused Speed Protected : Speed Limit Vision Fused Speed Unit Authenticated";
BA_ "SignalType" SG_ 1317 SLVFSP_SpdLimVsnFsdSpdNwDtdAuth "ENM";
BA_ "SignalLongName" SG_ 1317 SLVFSP_SpdLimVsnFsdSpdNwDtdAuth "Speed Limit Vision Fused Speed Protected : Speed Limit Vision Fused Speed New Detected Authenticated";
BA_ "SignalType" SG_ 1317 SLVFSP_SpdLimVsnFsdSpdAuth_DuD "ENM";
BA_ "SignalLongName" SG_ 1317 SLVFSP_SpdLimVsnFsdSpdAuth_DuD "Speed Limit Vision Fused Speed Protected : Speed Limit Vision Fused Speed Authenticated Don't Use Data";
BA_ "SignalLongName" SG_ 1378 SpnsnGenInfo2_PCSM "Suspension General Information 2 Protected Counter Sync Message";
BA_ "SignalLongName" SG_ 1309 SGI2P_MAC "Suspension General Information 2 Protected : MAC";
BA_ "SignalLongName" SG_ 1309 SGI2P_FCnt "Suspension General Information 2 Protected : Freshness Counter";
BA_ "SignalType" SG_ 1309 SGI2P_AirSpnsnRdHghtLwrActnAuth "ENM";
BA_ "SignalLongName" SG_ 1309 SGI2P_AirSpnsnRdHghtLwrActnAuth "Suspension General Information 2 Protected : Air Suspension Ride Height Lower Action Authenticated";
BA_ "SignalType" SG_ 1309 SGI2P_AirSpnsnRdHghtActvAxlAuth "ENM";
BA_ "SignalLongName" SG_ 1309 SGI2P_AirSpnsnRdHghtActvAxlAuth "Suspension General Information 2 Protected : Air Suspension Ride Height Active Axle Authenticated";
BA_ "SignalType" SG_ 1309 SGI2P_AirSpnsnRdHghtActlStsAuth "ENM";
BA_ "SignalLongName" SG_ 1309 SGI2P_AirSpnsnRdHghtActlStsAuth "Suspension General Information 2 Protected : Air Suspension Ride Height Actual Status Authenticated";
BA_ "SignalLongName" SG_ 1309 SGI2P_ARC "Suspension General Information 2 Protected : Alive Rolling Count";
BA_ "SignalType" SG_ 1309 SGI2P_AirSpnsnRdHghtTgtStsAuth "ENM";
BA_ "SignalLongName" SG_ 1309 SGI2P_AirSpnsnRdHghtTgtStsAuth "Suspension General Information 2 Protected : Air Suspension Ride Height Target Status Authenticated";
BA_ "SignalType" SG_ 1309 SGI2P_AirSpnsnRdHghtRseActnAuth "ENM";
BA_ "SignalLongName" SG_ 1309 SGI2P_AirSpnsnRdHghtRseActnAuth "Suspension General Information 2 Protected : Air Suspension Ride Height Raise Action Authenticated";
BA_ "SignalLongName" SG_ 1327 SrlDat113_PCSM "Serial Data 113 Protected Counter Sync Message";
BA_ "SignalLongName" SG_ 1277 SD113P_MAC "Serial Data 113 Protected : MAC";
BA_ "SignalLongName" SG_ 1277 SD113P_FCnt "Serial Data 113 Protected : Freshness Counter";
BA_ "SignalType" SG_ 1277 UpftrSnwPlwModeActv_Inv "ENM";
BA_ "SignalLongName" SG_ 1277 UpftrSnwPlwModeActv_Inv "Serial Data 113 Protected : Upfitter Snow Plow Mode Active Invalid";
BA_ "SignalType" SG_ 1277 UpftrSnwPlwModeActv "ENM";
BA_ "SignalLongName" SG_ 1277 UpftrSnwPlwModeActv "Serial Data 113 Protected : Upfitter Snow Plow Mode Active";
BA_ "SignalType" SG_ 1277 UpftrSnwPlwHdlmpsActv "ENM";
BA_ "SignalLongName" SG_ 1277 UpftrSnwPlwHdlmpsActv "Serial Data 113 Protected : Upfitter Snow Plow Headlamps Active";
BA_ "SignalType" SG_ 1277 UpftrLckReq "ENM";
BA_ "SignalLongName" SG_ 1277 UpftrLckReq "Serial Data 113 Protected : Upfitter Locking Request";
BA_ "SignalType" SG_ 1277 UpftrAutoShtdnInhbReqd "ENM";
BA_ "SignalLongName" SG_ 1277 UpftrAutoShtdnInhbReqd "Serial Data 113 Protected : Upfitter Automatic Shutdown Inhibit Requested";
BA_ "SignalType" SG_ 1277 UpftrAllWndMtnReq "ENM";
BA_ "SignalLongName" SG_ 1277 UpftrAllWndMtnReq "Serial Data 113 Protected : Upfitter All Window Motion Request";
BA_ "SignalLongName" SG_ 1277 SD113P_ARC "Serial Data 113 Protected : Alive Rolling Count";
BA_ "SignalType" SG_ 1277 UpftrVehRmtStrtupReq "ENM";
BA_ "SignalLongName" SG_ 1277 UpftrVehRmtStrtupReq "Serial Data 113 Protected : Upfitter Vehicle Remote Startup Request";
BA_ "SignalLongName" SG_ 910 SrlDat11_PCSM "Serial Data 11 Protected Counter Sync Message";
BA_ "SignalLongName" SG_ 48 SD11P_MAC "Serial Data 11 Protected : MAC";
BA_ "SignalLongName" SG_ 48 SD11P_FCnt "Serial Data 11 Protected : Freshness Counter";
BA_ "SignalType" SG_ 48 HVGI1P_PrplRltdBsHVAllwdPriAuth "ENM";
BA_ "SignalLongName" SG_ 48 HVGI1P_PrplRltdBsHVAllwdPriAuth "Serial Data 11 Protected : Propulsion Related Bus High Voltage Allowed Primary Authenticated";
BA_ "SignalType" SG_ 48 HVGI1P_HVBatCntctrStsPriAuth "ENM";
BA_ "SignalLongName" SG_ 48 HVGI1P_HVBatCntctrStsPriAuth "Serial Data 11 Protected : High Voltage Battery Contactor Status Primary Authenticated";
BA_ "SignalType" SG_ 48 HVGI1P_CntctrShtdnReqPriAuth "ENM";
BA_ "SignalLongName" SG_ 48 HVGI1P_CntctrShtdnReqPriAuth "Serial Data 11 Protected : Contactor Shutdown Request Primary Authenticated";
BA_ "SignalType" SG_ 48 ElcDischrgActr2DischrgCmdAuth "ENM";
BA_ "SignalLongName" SG_ 48 ElcDischrgActr2DischrgCmdAuth "Serial Data 11 Protected : Electric Discharge Actuator 2 Discharge Command Authenticated";
BA_ "SignalLongName" SG_ 48 SD11P_Filler "Serial Data 11 Protected : Filler";
BA_ "SignalLongName" SG_ 48 SD11P_ARC "Serial Data 11 Protected : Alive Rolling Count";
BA_ "SignalType" SG_ 48 HVGI7P_ESSPrplSysStsPriAuth "ENM";
BA_ "SignalLongName" SG_ 48 HVGI7P_ESSPrplSysStsPriAuth "Serial Data 11 Protected : Energy Storage System Propulsion System Status Primary Authenticated";
BA_ "SignalType" SG_ 48 HVGI7P_ESSPrplSysRespPriAuth "ENM";
BA_ "SignalLongName" SG_ 48 HVGI7P_ESSPrplSysRespPriAuth "Serial Data 11 Protected : Energy Storage System Propulsion System Response Primary Authenticated";
BA_ "SignalLongName" SG_ 1152 SrlDat124_PCSM "Serial Data 124 Protected Counter Sync Message";
BA_ "SignalLongName" SG_ 1149 SD124P_MAC "Serial Data 124 Protected : MAC";
BA_ "SignalLongName" SG_ 1149 SD124P_FCnt "Serial Data 124 Protected : Freshness Counter";
BA_ "SignalType" SG_ 1149 VirtKeyAllDrLckReqd "ENM";
BA_ "SignalLongName" SG_ 1149 VirtKeyAllDrLckReqd "Serial Data 124 Protected : Virtual Key All Door Lock Requested";
BA_ "SignalType" SG_ 1149 VirtKeyPncReq "ENM";
BA_ "SignalLongName" SG_ 1149 VirtKeyPncReq "Serial Data 124 Protected : Virtual Key Panic Request";
BA_ "SignalType" SG_ 1149 VirtKeyFobAvlReq "ENM";
BA_ "SignalLongName" SG_ 1149 VirtKeyFobAvlReq "Serial Data 124 Protected : Virtual Key Fob Availability Request";
BA_ "SignalType" SG_ 1149 VirtKeyRmtLctrReq "ENM";
BA_ "SignalLongName" SG_ 1149 VirtKeyRmtLctrReq "Serial Data 124 Protected : Virtual Key Remote Locator Request";
BA_ "SignalType" SG_ 1149 SRPCrsFrtInSftBtnMblDevSts "ENM";
BA_ "SignalLongName" SG_ 1149 SRPCrsFrtInSftBtnMblDevSts "Serial Data 124 Protected : Supervised Remote Parking Cross Front-In Soft Button Mobile Device Status";
BA_ "SignalType" SG_ 1149 SRPCrsBkInSftBtnMblDevSts "ENM";
BA_ "SignalLongName" SG_ 1149 SRPCrsBkInSftBtnMblDevSts "Serial Data 124 Protected : Supervised Remote Parking Cross Back-In Soft Button Mobile Device Status";
BA_ "SignalType" SG_ 1149 VirtKeyRrClsrUnlckReqd "ENM";
BA_ "SignalLongName" SG_ 1149 VirtKeyRrClsrUnlckReqd "Serial Data 124 Protected : Virtual Key Rear Closure Unlock Requested";
BA_ "SignalType" SG_ 1149 VirtKeyRrClsrLckReqd "ENM";
BA_ "SignalLongName" SG_ 1149 VirtKeyRrClsrLckReqd "Serial Data 124 Protected : Virtual Key Rear Closure Lock Requested";
BA_ "SignalType" SG_ 1149 VirtKeyFrtClsrUnlckReqd "ENM";
BA_ "SignalLongName" SG_ 1149 VirtKeyFrtClsrUnlckReqd "Serial Data 124 Protected : Virtual Key Front Closure Unlock Requested";
BA_ "SignalType" SG_ 1149 VirtKeyFrtClsrLckReqd "ENM";
BA_ "SignalLongName" SG_ 1149 VirtKeyFrtClsrLckReqd "Serial Data 124 Protected : Virtual Key Front Closure Lock Requested";
BA_ "SignalType" SG_ 1149 VirtKeyDrvrDrUnlckReqd "ENM";
BA_ "SignalLongName" SG_ 1149 VirtKeyDrvrDrUnlckReqd "Serial Data 124 Protected : Virtual Key Driver Door Unlock Requested";
BA_ "SignalType" SG_ 1149 VirtKeyAllDrUnlckReqd "ENM";
BA_ "SignalLongName" SG_ 1149 VirtKeyAllDrUnlckReqd "Serial Data 124 Protected : Virtual Key All Door Unlock Requested";
BA_ "SignalLongName" SG_ 1149 SD124P_Filler "Serial Data 124 Protected : Filler";
BA_ "SignalType" SG_ 1149 SRPSrchingSftBtnMblDevSts "ENM";
BA_ "SignalLongName" SG_ 1149 SRPSrchingSftBtnMblDevSts "Serial Data 124 Protected : Supervised Remote Parking Searching Soft Button Mobile Device Status";
BA_ "SignalType" SG_ 1149 SRPRtSftBtnMblDevSts "ENM";
BA_ "SignalLongName" SG_ 1149 SRPRtSftBtnMblDevSts "Serial Data 124 Protected : Supervised Remote Parking Right Soft Button Mobile Device Status";
BA_ "SignalType" SG_ 1149 SRPPrlllPrkSftBtnMblDevSts "ENM";
BA_ "SignalLongName" SG_ 1149 SRPPrlllPrkSftBtnMblDevSts "Serial Data 124 Protected : Supervised Remote Parking Parallel Parking Soft Button Mobile Device Status";
BA_ "SignalType" SG_ 1149 SRPLtSftBtnMblDevSts "ENM";
BA_ "SignalLongName" SG_ 1149 SRPLtSftBtnMblDevSts "Serial Data 124 Protected : Supervised Remote Parking Left Soft Button Mobile Device Status";
BA_ "SignalType" SG_ 1149 SRPExtPrkSftBtnMblDevSts "ENM";
BA_ "SignalLongName" SG_ 1149 SRPExtPrkSftBtnMblDevSts "Serial Data 124 Protected : Supervised Remote Parking Exit Park Soft Button Mobile Device Status";
BA_ "SignalLongName" SG_ 1149 SD124P_ARC "Serial Data 124 Protected : Alive Rolling Count";
BA_ "SignalLongName" SG_ 972 SrlDat125_PCSM "Serial Data 125 Protected Counter Sync Message";
BA_ "SignalLongName" SG_ 586 SD125P_MAC "Serial Data 125 Protected : MAC";
BA_ "SignalLongName" SG_ 586 SD125P_FCnt "Serial Data 125 Protected : Freshness Counter";
BA_ "SignalType" SG_ 586 VirtKeyPwrTopCtlReqrMblDevIdfr "ENM";
BA_ "SignalLongName" SG_ 586 VirtKeyPwrTopCtlReqrMblDevIdfr "Serial Data 125 Protected : Virtual Key Power Top Control Requestor Mobile Device Identifier";
BA_ "SignalLongName" SG_ 586 VirtKeyVehCbnACTempLvl "Serial Data 125 Protected : Virtual Key Vehicle Cabin Air Conditioning Temperature Level";
BA_ "SignalType" SG_ 586 VirtKeyPwrTopCtlReq "ENM";
BA_ "SignalLongName" SG_ 586 VirtKeyPwrTopCtlReq "Serial Data 125 Protected : Virtual Key Power Top Control Request";
BA_ "SignalType" SG_ 586 VirtKeyPwrRrClsrCtlReq "ENM";
BA_ "SignalLongName" SG_ 586 VirtKeyPwrRrClsrCtlReq "Serial Data 125 Protected : Virtual Key Power Rear Closure Control Request";
BA_ "SignalType" SG_ 586 VirtKeyFrtClsrCtlReq "ENM";
BA_ "SignalLongName" SG_ 586 VirtKeyFrtClsrCtlReq "Serial Data 125 Protected : Virtual Key Front Closure Control Request";
BA_ "SignalType" SG_ 586 VirtKeyWndCtlReq "ENM";
BA_ "SignalLongName" SG_ 586 VirtKeyWndCtlReq "Serial Data 125 Protected : Virtual Key Window Control Request";
BA_ "SignalType" SG_ 586 VirtKeyVehCbnACReq "ENM";
BA_ "SignalLongName" SG_ 586 VirtKeyVehCbnACReq "Serial Data 125 Protected : Virtual Key Vehicle Cabin Air Conditioning Request";
BA_ "SignalType" SG_ 586 VirtKeySnrfCtlReq "ENM";
BA_ "SignalLongName" SG_ 586 VirtKeySnrfCtlReq "Serial Data 125 Protected : Virtual Key Sunroof Control Request";
BA_ "SignalLongName" SG_ 586 SD125P_ARC "Serial Data 125 Protected : Alive Rolling Count";
BA_ "SignalLongName" SG_ 586 SD125P_Filler "Serial Data 125 Protected : Filler";
BA_ "SignalType" SG_ 586 SRPMblDevDctvBtnSts "ENM";
BA_ "SignalLongName" SG_ 586 SRPMblDevDctvBtnSts "Serial Data 125 Protected : Supervised Remote Parking Deactivation Soft Button Mobile Device Status";
BA_ "SignalType" SG_ 586 VirtKeyVehCbnACTempLvlReqActv "ENM";
BA_ "SignalLongName" SG_ 586 VirtKeyVehCbnACTempLvlReqActv "Serial Data 125 Protected : Virtual Key Vehicle Cabin Air Conditioning Temperature Level Request Active";
BA_ "SignalType" SG_ 586 VirtKeyRrClsrRelReqd "ENM";
BA_ "SignalLongName" SG_ 586 VirtKeyRrClsrRelReqd "Serial Data 125 Protected : Virtual Key Rear Closure Release Requested";
BA_ "SignalLongName" SG_ 967 SrlDat133_PCSM "Serial Data 133 Protected Counter Sync Message";
BA_ "SignalLongName" SG_ 591 SD133P_MAC "Serial Data 133 Protected : MAC";
BA_ "SignalLongName" SG_ 591 SD133P_FCnt "Serial Data 133 Protected : Freshness Counter";
BA_ "SignalLongName" SG_ 591 SD133P_Filler "Serial Data 133 Protected : Filler";
BA_ "SignalType" SG_ 591 ElecDrvUnt3DrvUntPrplSecSts "ENM";
BA_ "SignalLongName" SG_ 591 ElecDrvUnt3DrvUntPrplSecSts "Serial Data 133 Protected : Electric Drive Unit 3 Drive Unit Propulsion Secondary Status";
BA_ "SignalLongName" SG_ 591 SD133P_ARC "Serial Data 133 Protected : Alive Rolling Count";
BA_ "SignalLongName" SG_ 969 SrlDat134_PCSM "Serial Data 134 Protected Counter Sync Message";
BA_ "SignalLongName" SG_ 590 SD134P_MAC "Serial Data 134 Protected : MAC";
BA_ "SignalLongName" SG_ 590 SD134P_FCnt "Serial Data 134 Protected : Freshness Counter";
BA_ "SignalLongName" SG_ 590 SD134P_Filler "Serial Data 134 Protected : Filler";
BA_ "SignalType" SG_ 590 ElecDrvUnt2DrvUntPrplSecSts "ENM";
BA_ "SignalLongName" SG_ 590 ElecDrvUnt2DrvUntPrplSecSts "Serial Data 134 Protected : Electric Drive Unit 2 Drive Unit Propulsion Secondary Status";
BA_ "SignalLongName" SG_ 590 SD134P_ARC "Serial Data 134 Protected : Alive Rolling Count";
BA_ "SignalLongName" SG_ 970 SrlDat135_PCSM "Serial Data 135 Protected Counter Sync Message";
BA_ "SignalLongName" SG_ 588 SD135P_MAC "Serial Data 135 Protected : MAC";
BA_ "SignalLongName" SG_ 588 SD135P_FCnt "Serial Data 135 Protected : Freshness Counter";
BA_ "SignalLongName" SG_ 588 SD135P_Filler "Serial Data 135 Protected : Filler";
BA_ "SignalType" SG_ 588 ElecDrvUnt3DrvUntPrplSecCmd "ENM";
BA_ "SignalLongName" SG_ 588 ElecDrvUnt3DrvUntPrplSecCmd "Serial Data 135 Protected : Electric Drive Unit 3 Drive Unit Propulsion Secondary Command";
BA_ "SignalType" SG_ 588 ElecDrvUnt2DrvUntPrplSecCmd "ENM";
BA_ "SignalLongName" SG_ 588 ElecDrvUnt2DrvUntPrplSecCmd "Serial Data 135 Protected : Electric Drive Unit 2 Drive Unit Propulsion Secondary Command";
BA_ "SignalLongName" SG_ 588 SD135P_ARC "Serial Data 135 Protected : Alive Rolling Count";
BA_ "SignalLongName" SG_ 740 Sig6844 "Signal5536";
BA_ "SignalLongName" SG_ 29 Sig5637 "Signal5534";
BA_ "SignalLongName" SG_ 29 Sig5635 "Signal5533";
BA_ "SignalLongName" SG_ 29 Sig4924 "Signal5535";
BA_ "SignalLongName" SG_ 29 Sig5636 "Signal5532";
BA_ "SignalLongName" SG_ 29 Sig5634 "Signal5531";
BA_ "SignalLongName" SG_ 1446 ACRefrigLoSdFldPrsVal "Serial Data 13 : Air Conditioning Refrigerant Low Side Fluid Pressure Value";
BA_ "SignalType" SG_ 1446 ACRefrigLoSdFPSCktFABndl "ENM";
BA_ "SignalLongName" SG_ 1446 ACRefrigLoSdFPSCktFABndl "Serial Data 13 : Air Conditioning Refrigerant Low Side Fluid Pressure Sensor Circuit Fault Active Bundle";
BA_ "SignalLongName" SG_ 1446 HVGI11_PwrElecCoolLoopTemp "Serial Data 13 : Power Electronics Cooling Loop Temperature";
BA_ "SignalType" SG_ 1446 ACRefrigLoSdFldPrsVal_Inv "ENM";
BA_ "SignalLongName" SG_ 1446 ACRefrigLoSdFldPrsVal_Inv "Serial Data 13 : Air Conditioning Refrigerant Low Side Fluid Pressure Value Invalid";
BA_ "SignalLongName" SG_ 1446 AltTxPrplSysOffTm "Serial Data 13 : Alternate Transmitter Propulsion System Off Time";
BA_ "SignalType" SG_ 1446 HVGI11_PwrElecCoolLoopTemp_Inv "ENM";
BA_ "SignalLongName" SG_ 1446 HVGI11_PwrElecCoolLoopTemp_Inv "Serial Data 13 : Power Electronics Cooling Loop Temperature Invalid";
BA_ "SignalType" SG_ 1446 HVGI11_PwrElecCoolLoopTemp_DuD "ENM";
BA_ "SignalLongName" SG_ 1446 HVGI11_PwrElecCoolLoopTemp_DuD "Serial Data 13 : Power Electronics Cooling Loop Temperature Don't Use Data";
BA_ "SignalType" SG_ 1446 AltTxPrplSysOffTm_Inv "ENM";
BA_ "SignalLongName" SG_ 1446 AltTxPrplSysOffTm_Inv "Serial Data 13 : Alternate Transmitter Propulsion System Off Time Invalid";
BA_ "SignalType" SG_ 1446 AltTxPrplSysOffTm_DuD "ENM";
BA_ "SignalLongName" SG_ 1446 AltTxPrplSysOffTm_DuD "Serial Data 13 : Alternate Transmitter Propulsion System Off Time Don't Use Data";
BA_ "SignalLongName" SG_ 1446 SD13_CS "Serial Data 13 : Checksum";
BA_ "SignalLongName" SG_ 1446 SD13_ARC "Serial Data 13 : Alive Rolling Count";
BA_ "SignalLongName" SG_ 971 SrlDat141_PCSM "Serial Data 141 Protected Counter Sync Message";
BA_ "SignalLongName" SG_ 587 SD141P_MAC "Serial Data 141 Protected : MAC";
BA_ "SignalLongName" SG_ 587 SD141P_FCnt "Serial Data 141 Protected : Freshness Counter";
BA_ "SignalLongName" SG_ 587 SuprRmtPrkPrplSysTrqReq "Serial Data 141 Protected : Supervised Remote Parking Propulsion System Torque Request";
BA_ "SignalLongName" SG_ 587 SuprRmtPrkBrkTrqReq "Serial Data 141 Protected : Supervised Remote Parking Brake Torque Request";
BA_ "SignalType" SG_ 587 SuprRmtPrkFricBrkTrqReqTyp "ENM";
BA_ "SignalLongName" SG_ 587 SuprRmtPrkFricBrkTrqReqTyp "Serial Data 141 Protected : Supervised Remote Parking Friction Brake Torque Request Type";
BA_ "SignalType" SG_ 587 SuprRmtPrkElecPrkBrkReq "ENM";
BA_ "SignalLongName" SG_ 587 SuprRmtPrkElecPrkBrkReq "Serial Data 141 Protected : Supervised Remote Parking Electric Park Brake Request";
BA_ "SignalLongName" SG_ 587 SD141P_Filler "Serial Data 141 Protected : Filler";
BA_ "SignalType" SG_ 587 SuprRmtPrkPrplSysActvnReqd "ENM";
BA_ "SignalLongName" SG_ 587 SuprRmtPrkPrplSysActvnReqd "Serial Data 141 Protected : Supervised Remote Parking Propulsion System Activation Requested";
BA_ "SignalLongName" SG_ 587 SD141P_ARC "Serial Data 141 Protected : Alive Rolling Count";
BA_ "SignalLongName" SG_ 1145 ClmCtlCbnEvpAirOutTemp "Serial Data 145 : Climate Control Cabin Evaporator Air Out Temperature";
BA_ "SignalLongName" SG_ 1145 ClmCtlCbnFrtLtTempSet "Serial Data 145 : Climate Control Cabin Front Left Temperature Setting";
BA_ "SignalLongName" SG_ 1145 ClmCtlCbnFrtRtTempSet "Serial Data 145 : Climate Control Cabin Front Right Temperature Setting";
BA_ "SignalType" SG_ 1145 ClmCtlCbnMaxDefrReqOn_Inv "ENM";
BA_ "SignalLongName" SG_ 1145 ClmCtlCbnMaxDefrReqOn_Inv "Serial Data 145 : Climate Control Cabin Max Defrost Request On Invalid";
BA_ "SignalType" SG_ 1145 ClmCtlCbnMaxDefrReqOn "ENM";
BA_ "SignalLongName" SG_ 1145 ClmCtlCbnMaxDefrReqOn "Serial Data 145 : Climate Control Cabin Max Defrost Request On";
BA_ "SignalType" SG_ 1145 ClmCtlCbnFrtRtTempSet_Inv "ENM";
BA_ "SignalLongName" SG_ 1145 ClmCtlCbnFrtRtTempSet_Inv "Serial Data 145 : Climate Control Cabin Front Right Temperature Setting Invalid";
BA_ "SignalType" SG_ 1145 ClmCtlCbnFrtLtTempSet_Inv "ENM";
BA_ "SignalLongName" SG_ 1145 ClmCtlCbnFrtLtTempSet_Inv "Serial Data 145 : Climate Control Cabin Front Left Temperature Setting Invalid";
BA_ "SignalType" SG_ 1145 ClmCtlCbnEvpAirOutTemp_Inv "ENM";
BA_ "SignalLongName" SG_ 1145 ClmCtlCbnEvpAirOutTemp_Inv "Serial Data 145 : Climate Control Cabin Evaporator Air Out Temperature Invalid";
BA_ "SignalLongName" SG_ 1145 SD145_CS "Serial Data 145 : Checksum";
BA_ "SignalLongName" SG_ 1145 SD145_ARC "Serial Data 145 : Alive Rolling Count";
BA_ "SignalLongName" SG_ 1377 SrlDat14_PCSM "Serial Data 14 Protected Counter Sync Message";
BA_ "SignalLongName" SG_ 873 SD14P_MAC "Serial Data 14 Protected : MAC";
BA_ "SignalLongName" SG_ 873 SD14P_FCnt "Serial Data 14 Protected : Freshness Counter";
BA_ "SignalLongName" SG_ 873 BSIR2P_BrkgSysVhTpSpLmValAuth "Serial Data 14 Protected : Braking System Vehicle Top Speed Limit Value Authenticated";
BA_ "SignalType" SG_ 873 BSIR2P_BrkgSysVhTpSpLmRqTypAuth "ENM";
BA_ "SignalLongName" SG_ 873 BSIR2P_BrkgSysVhTpSpLmRqTypAuth "Serial Data 14 Protected : Braking System Vehicle Top Speed Limit Request Type Authenticated";
BA_ "SignalType" SG_ 873 BSIR2P_BSPriVehTpSpLimRqTypAuth "ENM";
BA_ "SignalLongName" SG_ 873 BSIR2P_BSPriVehTpSpLimRqTypAuth "Serial Data 14 Protected : Braking System Primary Vehicle Top Speed Limit Request Type Authenticated";
BA_ "SignalType" SG_ 873 BSIR2P_BSPriVehTpSpLimRqSrcAuth "ENM";
BA_ "SignalLongName" SG_ 873 BSIR2P_BSPriVehTpSpLimRqSrcAuth "Serial Data 14 Protected : Braking System Primary Vehicle Top Speed Limit Request Source Authenticated";
BA_ "SignalType" SG_ 873 BSISP_ESCActvAuth "ENM";
BA_ "SignalLongName" SG_ 873 BSISP_ESCActvAuth "Serial Data 14 Protected : Electronic Stability Control Active Authenticated";
BA_ "SignalType" SG_ 873 BSISP_TCSFaildAuth "ENM";
BA_ "SignalLongName" SG_ 873 BSISP_TCSFaildAuth "Serial Data 14 Protected : Traction Control System Failed Authenticated";
BA_ "SignalType" SG_ 873 BSISP_TCSDrvrIntntAuth "ENM";
BA_ "SignalLongName" SG_ 873 BSISP_TCSDrvrIntntAuth "Serial Data 14 Protected : Traction Control System Driver Intent Authenticated";
BA_ "SignalType" SG_ 873 BSISP_TCSActvAuth "ENM";
BA_ "SignalLongName" SG_ 873 BSISP_TCSActvAuth "Serial Data 14 Protected : Traction Control System Active Authenticated";
BA_ "SignalType" SG_ 873 BSISP_ETRSHydrlcBrkgStsAuth "ENM";
BA_ "SignalLongName" SG_ 873 BSISP_ETRSHydrlcBrkgStsAuth "Serial Data 14 Protected : ETRS Hydraulic Braking Status Authenticated";
BA_ "SignalType" SG_ 873 BSISP_ESCSysStsAuth "ENM";
BA_ "SignalLongName" SG_ 873 BSISP_ESCSysStsAuth "Serial Data 14 Protected : Electronic Stability Control System Status Authenticated";
BA_ "SignalLongName" SG_ 873 SD14P_ARC "Serial Data 14 Protected : Alive Rolling Count";
BA_ "SignalType" SG_ 873 DMCP_VehSpdLimFricBrkStsAuth "ENM";
BA_ "SignalLongName" SG_ 873 DMCP_VehSpdLimFricBrkStsAuth "Serial Data 14 Protected : Vehicle Speed Limit Friction Brake Status Authenticated";
BA_ "SignalType" SG_ 873 DMCP_AWDPerfModeReqAuth "ENM";
BA_ "SignalLongName" SG_ 873 DMCP_AWDPerfModeReqAuth "Serial Data 14 Protected : All Wheel Drive Performance Mode Request Authenticated";
BA_ "SignalType" SG_ 873 BrkgSysVehTopSpdLimIndOnAuth "ENM";
BA_ "SignalLongName" SG_ 873 BrkgSysVehTopSpdLimIndOnAuth "Serial Data 14 Protected : Braking System Vehicle Top Speed Limit Indication On Authenticated";
BA_ "SignalLongName" SG_ 694 SrlDat15_PCSM "Serial Data 15 Protected Counter Sync Message";
BA_ "SignalLongName" SG_ 635 SD15P_MAC "Serial Data 15 Protected : MAC";
BA_ "SignalLongName" SG_ 635 SD15P_FCnt "Serial Data 15 Protected : Freshness Counter";
BA_ "SignalType" SG_ 635 EPBSP_ElecPrkBrkAvlStsAuth "ENM";
BA_ "SignalLongName" SG_ 635 EPBSP_ElecPrkBrkAvlStsAuth "Serial Data 15 Protected : Electric Park Brake Availability Status Authenticated";
BA_ "SignalType" SG_ 635 EPBSP_ElecPrkBrkApplStsAuth "ENM";
BA_ "SignalLongName" SG_ 635 EPBSP_ElecPrkBrkApplStsAuth "Serial Data 15 Protected : Electric Park Brake Application Status Authenticated";
BA_ "SignalType" SG_ 635 EPBSP_EPBSysBrkLgtsReqdAuth "ENM";
BA_ "SignalLongName" SG_ 635 EPBSP_EPBSysBrkLgtsReqdAuth "Serial Data 15 Protected : Electric Park Brake System Brake Lights Requested Authenticated";
BA_ "SignalType" SG_ 635 EPBSP_BrkSysBrkLgtsReqdAuth "ENM";
BA_ "SignalLongName" SG_ 635 EPBSP_BrkSysBrkLgtsReqdAuth "Serial Data 15 Protected : Brake System Brake Lights Requested Authenticated";
BA_ "SignalType" SG_ 635 DMCP_EnvIdRsp2Auth "ENM";
BA_ "SignalLongName" SG_ 635 DMCP_EnvIdRsp2Auth "Serial Data 15 Protected : Environment Module Present Responder 2 Authenticated";
BA_ "SignalLongName" SG_ 635 TBIP_TrlrBrkgGainSetAuth "Serial Data 15 Protected : Trailer Braking Gain Setting Authenticated";
BA_ "SignalType" SG_ 635 TBIP_TrlrBrkDsbldIndOnAuth "ENM";
BA_ "SignalLongName" SG_ 635 TBIP_TrlrBrkDsbldIndOnAuth "Serial Data 15 Protected : Trailer Brakes Disabled Indication On Authenticated";
BA_ "SignalType" SG_ 635 TBIP_ServTrlrBrkgSysIndOnAuth "ENM";
BA_ "SignalLongName" SG_ 635 TBIP_ServTrlrBrkgSysIndOnAuth "Serial Data 15 Protected : Service Trailer Braking System Indication On Authenticated";
BA_ "SignalType" SG_ 635 TBIP_CkTrlrIndOnAuth "ENM";
BA_ "SignalLongName" SG_ 635 TBIP_CkTrlrIndOnAuth "Serial Data 15 Protected : Check Trailer Indication On Authenticated";
BA_ "SignalType" SG_ 635 EPBSP_TrlrBrkgSysBrkLgtsRqdAuth "ENM";
BA_ "SignalLongName" SG_ 635 EPBSP_TrlrBrkgSysBrkLgtsRqdAuth "Serial Data 15 Protected : Trailer Braking System Brake Lights Requested Authenticated";
BA_ "SignalLongName" SG_ 635 SD15P_ARC "Serial Data 15 Protected : Alive Rolling Count";
BA_ "SignalType" SG_ 635 TBIP_TrlrWrgFltIndOnAuth "ENM";
BA_ "SignalLongName" SG_ 635 TBIP_TrlrWrgFltIndOnAuth "Serial Data 15 Protected : Trailer Wiring Fault Indication On Authenticated";
BA_ "SignalType" SG_ 635 TBIP_TrlrBrkgGainSetIndOnAuth "ENM";
BA_ "SignalLongName" SG_ 635 TBIP_TrlrBrkgGainSetIndOnAuth "Serial Data 15 Protected : Trailer Braking Gain Setting Indication On Authenticated";
BA_ "SignalLongName" SG_ 635 SD15P_Filler "Serial Data 15 Protected : Filler";
BA_ "SignalType" SG_ 635 ElecPrkBrkMnPriPerfRdcd "ENM";
BA_ "SignalLongName" SG_ 635 ElecPrkBrkMnPriPerfRdcd "Serial Data 15 Protected : Electric Park Brake Main Primary Performance Reduced";
BA_ "SignalType" SG_ 635 TrlrBrkgRdcdIndOn "ENM";
BA_ "SignalLongName" SG_ 635 TrlrBrkgRdcdIndOn "Serial Data 15 Protected : Trailer Braking Reduced Indication On";
BA_ "SignalType" SG_ 635 TrlrBrkgHldLstKnwnGainIndOn "ENM";
BA_ "SignalLongName" SG_ 635 TrlrBrkgHldLstKnwnGainIndOn "Serial Data 15 Protected : Trailer Braking Hold Last Known Gain Indication On";
BA_ "SignalLongName" SG_ 974 SrlDat160_PCSM "Serial Data 160 Protected Counter Sync Message";
BA_ "SignalLongName" SG_ 644 SD160P_MAC "Serial Data 160 Protected : MAC";
BA_ "SignalLongName" SG_ 644 SD160P_FCnt "Serial Data 160 Protected : Freshness Counter";
BA_ "SignalLongName" SG_ 644 AASILASStrgReqAngVal "Serial Data 160 Protected : Arbitrated ASIL Active Safety Steering Request Angle Value";
BA_ "SignalLongName" SG_ 644 AASILASStrgReqHiResTrqVal "Serial Data 160 Protected : Arbitrated ASIL Active Safety Steering Request High Resolution Torque Value";
BA_ "SignalType" SG_ 644 AASILASStrgReqLnFllwgRrStrgInhb "ENM";
BA_ "SignalLongName" SG_ 644 AASILASStrgReqLnFllwgRrStrgInhb "Serial Data 160 Protected : Arbitrated ASIL Active Safety Steering Request Lane Following Rear Steering Inhibit";
BA_ "SignalType" SG_ 644 AASILASStrgReqSts "ENM";
BA_ "SignalLongName" SG_ 644 AASILASStrgReqSts "Serial Data 160 Protected : Arbitrated ASIL Active Safety Steering Request Status";
BA_ "SignalType" SG_ 644 AASILASStrgReqAFtr "ENM";
BA_ "SignalLongName" SG_ 644 AASILASStrgReqAFtr "Serial Data 160 Protected : Arbitrated ASIL Active Safety Steering Request Arbitrated Feature";
BA_ "SignalLongName" SG_ 644 SD160P_Filler "Serial Data 160 Protected : Filler";
BA_ "SignalType" SG_ 644 AASILASStrgReqTyp "ENM";
BA_ "SignalLongName" SG_ 644 AASILASStrgReqTyp "Serial Data 160 Protected : Arbitrated ASIL Active Safety Steering Request Type";
BA_ "SignalLongName" SG_ 644 SD160P_ARC "Serial Data 160 Protected : Alive Rolling Count";
BA_ "SignalLongName" SG_ 975 SrlDat161_PCSM "Serial Data 161 Protected Counter Sync Message";
BA_ "SignalLongName" SG_ 602 SD161P_MAC "Serial Data 161 Protected : MAC";
BA_ "SignalLongName" SG_ 602 SD161P_FCnt "Serial Data 161 Protected : Freshness Counter";
BA_ "SignalLongName" SG_ 602 LnDtnWrnCtlHRTrqOvrlyReqVal "Serial Data 161 Protected : Lane Detection Warning Control High Resolution Torque Overlay Request Value";
BA_ "SignalType" SG_ 602 LnDtnWrnCtlTrqOvrlyReqActv_Inv "ENM";
BA_ "SignalLongName" SG_ 602 LnDtnWrnCtlTrqOvrlyReqActv_Inv "Serial Data 161 Protected : Lane Detection Warning Control Torque Overlay Request Active Invalid";
BA_ "SignalType" SG_ 602 LnDtnWrnCtlTrqOvrlyReqActv_DuD "ENM";
BA_ "SignalLongName" SG_ 602 LnDtnWrnCtlTrqOvrlyReqActv_DuD "Serial Data 161 Protected : Lane Detection Warning Control Torque Overlay Request Active Don't Use Data";
BA_ "SignalType" SG_ 602 LnDtnWrnCtlTrqOvrlyReqActv "ENM";
BA_ "SignalLongName" SG_ 602 LnDtnWrnCtlTrqOvrlyReqActv "Serial Data 161 Protected : Lane Detection Warning Control Torque Overlay Request Active";
BA_ "SignalType" SG_ 602 LnDtnWrnCtlHRTrqOvrlyReqVal_Inv "ENM";
BA_ "SignalLongName" SG_ 602 LnDtnWrnCtlHRTrqOvrlyReqVal_Inv "Serial Data 161 Protected : Lane Detection Warning Control High Resolution Torque Overlay Request Value Invalid";
BA_ "SignalType" SG_ 602 LnDtnWrnCtlHRTrqOvrlyReqVal_DuD "ENM";
BA_ "SignalLongName" SG_ 602 LnDtnWrnCtlHRTrqOvrlyReqVal_DuD "Serial Data 161 Protected : Lane Detection Warning Control High Resolution Torque Overlay Request Value Don't Use Data";
BA_ "SignalLongName" SG_ 602 SD161P_Filler "Serial Data 161 Protected : Filler";
BA_ "SignalLongName" SG_ 602 SD161P_ARC "Serial Data 161 Protected : Alive Rolling Count";
BA_ "SignalLongName" SG_ 917 SrlDat162_PCSM "Serial Data 162 Protected Counter Sync Message";
BA_ "SignalLongName" SG_ 171 SD162P_MAC "Serial Data 162 Protected : MAC";
BA_ "SignalLongName" SG_ 171 SD162P_FCnt "Serial Data 162 Protected : Freshness Counter";
BA_ "SignalLongName" SG_ 171 SpnsnPstnOfstFromTrmLF "Serial Data 162 Protected : Suspension Position Offset From Trim Left Front";
BA_ "SignalLongName" SG_ 171 SpnsnPstnOfstFromTrmLR "Serial Data 162 Protected : Suspension Position Offset From Trim Left Rear";
BA_ "SignalLongName" SG_ 171 SpnsnPstnOfstFromTrmRF "Serial Data 162 Protected : Suspension Position Offset From Trim Right Front";
BA_ "SignalLongName" SG_ 171 SpnsnPstnOfstFromTrmRR "Serial Data 162 Protected : Suspension Position Offset From Trim Right Rear";
BA_ "SignalType" SG_ 171 SpnsnPstnOfstFromTrmRR_Inv "ENM";
BA_ "SignalLongName" SG_ 171 SpnsnPstnOfstFromTrmRR_Inv "Serial Data 162 Protected : Suspension Position Offset From Trim Right Rear Invalid";
BA_ "SignalType" SG_ 171 SpnsnPstnOfstFromTrmRF_Inv "ENM";
BA_ "SignalLongName" SG_ 171 SpnsnPstnOfstFromTrmRF_Inv "Serial Data 162 Protected : Suspension Position Offset From Trim Right Front Invalid";
BA_ "SignalType" SG_ 171 SpnsnPstnOfstFromTrmLR_Inv "ENM";
BA_ "SignalLongName" SG_ 171 SpnsnPstnOfstFromTrmLR_Inv "Serial Data 162 Protected : Suspension Position Offset From Trim Left Rear Invalid";
BA_ "SignalType" SG_ 171 SpnsnPstnOfstFromTrmLF_Inv "ENM";
BA_ "SignalLongName" SG_ 171 SpnsnPstnOfstFromTrmLF_Inv "Serial Data 162 Protected : Suspension Position Offset From Trim Left Front Invalid";
BA_ "SignalLongName" SG_ 171 SD162P_Filler "Serial Data 162 Protected : Filler";
BA_ "SignalLongName" SG_ 171 SD162P_ARC "Serial Data 162 Protected : Alive Rolling Count";
BA_ "SignalLongName" SG_ 749 APM2LTrmVltgCmd "Serial Data 165 : Auxiliary Power Module 2 L-Terminal Voltage Command";
BA_ "SignalLongName" SG_ 749 APMLTrmVltgPriCmd "Serial Data 165 : Auxiliary Power Module L-Terminal Voltage Primary Command";
BA_ "SignalLongName" SG_ 749 PriVehChlrOutCoolTemp "Serial Data 165 : Primary Vehicle Chiller Out Coolant Temperature";
BA_ "SignalType" SG_ 749 SecGridBatVltgCtlOvrrdActv "ENM";
BA_ "SignalLongName" SG_ 749 SecGridBatVltgCtlOvrrdActv "Serial Data 165 : Secondary Grid Battery Voltage Control Override Active";
BA_ "SignalType" SG_ 749 PriVehChlrOutCoolTemp_Inv "ENM";
BA_ "SignalLongName" SG_ 749 PriVehChlrOutCoolTemp_Inv "Serial Data 165 : Primary Vehicle Chiller Out Coolant Temperature Invalid";
BA_ "SignalType" SG_ 749 PriVehThrmlSysFltStat "ENM";
BA_ "SignalLongName" SG_ 749 PriVehThrmlSysFltStat "Serial Data 165 : Primary Vehicle Thermal System Fault State";
BA_ "SignalType" SG_ 749 APM2Sts "ENM";
BA_ "SignalLongName" SG_ 749 APM2Sts "Serial Data 165 : Auxiliary Power Module 2 Status";
BA_ "SignalLongName" SG_ 749 SD165_CS "Serial Data 165 : Checksum";
BA_ "SignalLongName" SG_ 749 SD165_ARC "Serial Data 165 : Alive Rolling Count";
BA_ "SignalLongName" SG_ 747 FOE46ecGrdVltgTgt "Serial Data 166 : Fail Operational Power Module Secondary Grid Voltage Target";
BA_ "SignalLongName" SG_ 747 SD166_CS "Serial Data 166 : Checksum";
BA_ "SignalType" SG_ 747 FOE46ecGrdVltgOvrrdPrty "ENM";
BA_ "SignalLongName" SG_ 747 FOE46ecGrdVltgOvrrdPrty "Serial Data 166 : Fail Operational Power Module Secondary Grid Voltage Override Priority";
BA_ "SignalLongName" SG_ 747 SD166_ARC "Serial Data 166 : Alive Rolling Count";
BA_ "SignalLongName" SG_ 909 SrlDat16_PCSM "Serial Data 16 Protected Counter Sync Message";
BA_ "SignalLongName" SG_ 59 SD16P_MAC "Serial Data 16 Protected : MAC";
BA_ "SignalLongName" SG_ 59 SD16P_FCnt "Serial Data 16 Protected : Freshness Counter";
BA_ "SignalLongName" SG_ 59 BSIRP_BrkSysMinVltgReqAuth "Serial Data 16 Protected : Brake System Minimum Voltage Request Authenticated";
BA_ "SignalType" SG_ 59 BSIRP_AutoBrkgPTReqStsAuth "ENM";
BA_ "SignalLongName" SG_ 59 BSIRP_AutoBrkgPTReqStsAuth "Serial Data 16 Protected : Automatic Braking Powertrain Request Status Authenticated";
BA_ "SignalType" SG_ 59 BSIRP_AdpCruzHldActvAuth "ENM";
BA_ "SignalLongName" SG_ 59 BSIRP_AdpCruzHldActvAuth "Serial Data 16 Protected : Adaptive Cruise Hold Active Authenticated";
BA_ "SignalType" SG_ 59 BSIRP_ChsSysAxlTqRqRspTpAuth "ENM";
BA_ "SignalLongName" SG_ 59 BSIRP_ChsSysAxlTqRqRspTpAuth "Serial Data 16 Protected : Chassis System Axle Torque Request Response Type Authenticated";
BA_ "SignalType" SG_ 59 BSIRP_ChsSysAxlTqRqFncAuth "ENM";
BA_ "SignalLongName" SG_ 59 BSIRP_ChsSysAxlTqRqFncAuth "Serial Data 16 Protected : Chassis System Axle Torque Request Function Authenticated";
BA_ "SignalLongName" SG_ 59 BSIRP_ChsSysImmAxlTqRqValAuth "Serial Data 16 Protected : Chassis System Immediate Axle Torque Request Value Authenticated";
BA_ "SignalType" SG_ 59 BSIRP_ChsSysPrdAxlTqRqItvTpAuth "ENM";
BA_ "SignalLongName" SG_ 59 BSIRP_ChsSysPrdAxlTqRqItvTpAuth "Serial Data 16 Protected : Chassis System Predicted Axle Torque Request Intervention Type Authenticated";
BA_ "SignalLongName" SG_ 59 BSIRP_ChsSysPrdAxlTqRqValAuth "Serial Data 16 Protected : Chassis System Predicted Axle Torque Request Value Authenticated";
BA_ "SignalType" SG_ 59 BrkAsstHalfSysBstFaildCktAuth "ENM";
BA_ "SignalLongName" SG_ 59 BrkAsstHalfSysBstFaildCktAuth "Serial Data 16 Protected : Brake Assist Half System Boost Failed Circuit Authenticated";
BA_ "SignalType" SG_ 59 BSIRP_RrVirtBmpInhbAuth "ENM";
BA_ "SignalLongName" SG_ 59 BSIRP_RrVirtBmpInhbAuth "Serial Data 16 Protected : Rear Virtual Bumper Inhibit Authenticated";
BA_ "SignalType" SG_ 59 BSIRP_HillDscntCtlStsAuth "ENM";
BA_ "SignalLongName" SG_ 59 BSIRP_HillDscntCtlStsAuth "Serial Data 16 Protected : Hill Descent Control Status Authenticated";
BA_ "SignalType" SG_ 59 BSIRP_DrvrSeltdHldEnbldAuth "ENM";
BA_ "SignalLongName" SG_ 59 BSIRP_DrvrSeltdHldEnbldAuth "Serial Data 16 Protected : Driver Selected Hold Enabled Authenticated";
BA_ "SignalType" SG_ 59 BSIRP_DrvrSeltdHldActvAuth "ENM";
BA_ "SignalLongName" SG_ 59 BSIRP_DrvrSeltdHldActvAuth "Serial Data 16 Protected : Driver Selected Hold Active Authenticated";
BA_ "SignalType" SG_ 59 BSIRP_ClsnPrepSysInhbAuth "ENM";
BA_ "SignalLongName" SG_ 59 BSIRP_ClsnPrepSysInhbAuth "Serial Data 16 Protected : Collision Preparation System Inhibit Authenticated";
BA_ "SignalLongName" SG_ 59 BrkSysSpltFricCoefEstdWDPrsAuth "Serial Data 16 Protected : Brake System Split Friction Coefficient Estimated Wheel Delta Pressure Authenticated";
BA_ "SignalType" SG_ 59 BrkSysSpltFricCoefBrkgActvAuth "ENM";
BA_ "SignalLongName" SG_ 59 BrkSysSpltFricCoefBrkgActvAuth "Serial Data 16 Protected : Brake System Split Friction Coefficient Braking Active Authenticated";
BA_ "SignalType" SG_ 59 BrkSysSpltFricCoefAccelActvAuth "ENM";
BA_ "SignalLongName" SG_ 59 BrkSysSpltFricCoefAccelActvAuth "Serial Data 16 Protected : Brake System Split Friction Coefficient Acceleration Active Authenticated";
BA_ "SignalLongName" SG_ 59 CBIP_BrkPedPstnEmsRltdAuth "Serial Data 16 Protected : Brake Pedal Position Emissions Related Authenticated";
BA_ "SignalType" SG_ 59 CBIP_ACCBrkgStsAuth "ENM";
BA_ "SignalLongName" SG_ 59 CBIP_ACCBrkgStsAuth "Serial Data 16 Protected : Adaptive Cruise Control Braking Status Authenticated";
BA_ "SignalType" SG_ 59 CBIP_ACCBrkgActvAuth "ENM";
BA_ "SignalLongName" SG_ 59 CBIP_ACCBrkgActvAuth "Serial Data 16 Protected : Adaptive Cruise Control Braking Active Authenticated";
BA_ "SignalType" SG_ 59 CBIP_ClsnImntBrkgStsAuth "ENM";
BA_ "SignalLongName" SG_ 59 CBIP_ClsnImntBrkgStsAuth "Serial Data 16 Protected : Collision Imminent Braking Status Authenticated";
BA_ "SignalType" SG_ 59 CBIP_BrkPedPstnEmsRltdAuth_Inv "ENM";
BA_ "SignalLongName" SG_ 59 CBIP_BrkPedPstnEmsRltdAuth_Inv "Serial Data 16 Protected : Brake Pedal Position Emissions Related Authenticated Invalid";
BA_ "SignalType" SG_ 59 CSATRP_PriATReqFncAuth "ENM";
BA_ "SignalLongName" SG_ 59 CSATRP_PriATReqFncAuth "Serial Data 16 Protected : Primary Axle Torque Request Function Authenticated";
BA_ "SignalType" SG_ 59 CBIP_EPBCruzCtlCnclReqAuth "ENM";
BA_ "SignalLongName" SG_ 59 CBIP_EPBCruzCtlCnclReqAuth "Serial Data 16 Protected : Electric Park Brake Cruise Control Cancel Request Authenticated";
BA_ "SignalType" SG_ 59 CBIP_DrvrIndpntBrkAppActvAuth "ENM";
BA_ "SignalLongName" SG_ 59 CBIP_DrvrIndpntBrkAppActvAuth "Serial Data 16 Protected : Driver Independent Brake Apply Active Authenticated";
BA_ "SignalType" SG_ 59 CBIP_ClsnImntDrvrBrkPedOvrdAuth "ENM";
BA_ "SignalLongName" SG_ 59 CBIP_ClsnImntDrvrBrkPedOvrdAuth "Serial Data 16 Protected : Collision Imminent Driver Brake Pedal Override Authenticated";
BA_ "SignalLongName" SG_ 59 CSATRP_PriATReqImmedAuth "Serial Data 16 Protected : Primary Axle Torque Request Immediate Authenticated";
BA_ "SignalType" SG_ 59 CSATRP_PriATReqIntvTypPrdtdAuth "ENM";
BA_ "SignalLongName" SG_ 59 CSATRP_PriATReqIntvTypPrdtdAuth "Serial Data 16 Protected : Primary Axle Torque Request Intervention Type Predicted Authenticated";
BA_ "SignalLongName" SG_ 59 CSATRP_PriATReqPrdtdAuth "Serial Data 16 Protected : Primary Axle Torque Request Predicted Authenticated";
BA_ "SignalType" SG_ 59 CSATRP_SecATReqFncAuth "ENM";
BA_ "SignalLongName" SG_ 59 CSATRP_SecATReqFncAuth "Serial Data 16 Protected : Secondary Axle Torque Request Function Authenticated";
BA_ "SignalType" SG_ 59 CSATRP_SecATIntvTypPrdtdAuth "ENM";
BA_ "SignalLongName" SG_ 59 CSATRP_SecATIntvTypPrdtdAuth "Serial Data 16 Protected : Secondary Axle Torque Intervention Type Predicted Authenticated";
BA_ "SignalType" SG_ 59 CSATRP_PriATReqRespTypAuth "ENM";
BA_ "SignalLongName" SG_ 59 CSATRP_PriATReqRespTypAuth "Serial Data 16 Protected : Primary Axle Torque Request Response Type Authenticated";
BA_ "SignalLongName" SG_ 59 CSATRP_SecATReqImmedAuth "Serial Data 16 Protected : Secondary Axle Torque Request Immediate Authenticated";
BA_ "SignalLongName" SG_ 59 CSATRP_SecATReqPrdtdAuth "Serial Data 16 Protected : Secondary Axle Torque Request Predicted Authenticated";
BA_ "SignalType" SG_ 59 CSATRP_SecATReqRespTypAuth "ENM";
BA_ "SignalLongName" SG_ 59 CSATRP_SecATReqRespTypAuth "Serial Data 16 Protected : Secondary Axle Torque Request Response Type Authenticated";
BA_ "SignalLongName" SG_ 59 CSBT2P_BrkBlndgAxlTrqReqAuth "Serial Data 16 Protected : Brake Blending Axle Torque Request Authenticated";
BA_ "SignalLongName" SG_ 59 CSBTP_ChsSysTtBrkAxTqVlAuth "Serial Data 16 Protected : Chassis System Total Brake Axle Torque Value Authenticated";
BA_ "SignalLongName" SG_ 59 CSBTP_DrvrIntndTtBrkTqAuth "Serial Data 16 Protected : Driver Intended Total Brake Torque Authenticated";
BA_ "SignalType" SG_ 59 CSBTP_ChsSysTtBrkAxTqVlAuth_Inv "ENM";
BA_ "SignalLongName" SG_ 59 CSBTP_ChsSysTtBrkAxTqVlAuth_Inv "Serial Data 16 Protected : Chassis System Total Brake Axle Torque Value Authenticated Invalid";
BA_ "SignalLongName" SG_ 59 FWDECP_LFAuth "Serial Data 16 Protected : Wheel Distance Edge Counter Left Front Authenticated";
BA_ "SignalLongName" SG_ 59 FWDECP_RFAuth "Serial Data 16 Protected : Wheel Distance Edge Counter Right Front Authenticated";
BA_ "SignalType" SG_ 59 FWDECP_LFAuth_Inv "ENM";
BA_ "SignalLongName" SG_ 59 FWDECP_LFAuth_Inv "Serial Data 16 Protected : Wheel Distance Edge Counter Left Front Authenticated Invalid";
BA_ "SignalType" SG_ 59 PTP_EngSpdIntvTypAuth "ENM";
BA_ "SignalLongName" SG_ 59 PTP_EngSpdIntvTypAuth "Serial Data 16 Protected : Engine Speed Intervention Type Authenticated";
BA_ "SignalType" SG_ 59 PTP_EngSpdCtlRespAuth "ENM";
BA_ "SignalLongName" SG_ 59 PTP_EngSpdCtlRespAuth "Serial Data 16 Protected : Engine Speed Control Response Authenticated";
BA_ "SignalType" SG_ 59 PTP_DCTLaunchCtlActvAuth "ENM";
BA_ "SignalLongName" SG_ 59 PTP_DCTLaunchCtlActvAuth "Serial Data 16 Protected : DCT Launch Control Active Authenticated";
BA_ "SignalType" SG_ 59 FWDECP_RstOccAuth "ENM";
BA_ "SignalLongName" SG_ 59 FWDECP_RstOccAuth "Serial Data 16 Protected : Front Wheel Distance Edge Counter Reset Occurred Authenticated";
BA_ "SignalType" SG_ 59 FWDECP_RFAuth_Inv "ENM";
BA_ "SignalLongName" SG_ 59 FWDECP_RFAuth_Inv "Serial Data 16 Protected : Wheel Distance Edge Counter Right Front Authenticated Invalid";
BA_ "SignalLongName" SG_ 59 PTP_EngSpdReqValAuth "Serial Data 16 Protected : Engine Speed Request Value Authenticated";
BA_ "SignalLongName" SG_ 59 RALTCRP_ValAuth "Serial Data 16 Protected : Value Authenticated";
BA_ "SignalType" SG_ 59 RALTCRP_TypAuth "ENM";
BA_ "SignalLongName" SG_ 59 RALTCRP_TypAuth "Serial Data 16 Protected : Type Authenticated";
BA_ "SignalLongName" SG_ 59 RWDECP_LRAuth "Serial Data 16 Protected : Rear Wheel Distance Edge Counter Left Rear Authenticated";
BA_ "SignalLongName" SG_ 59 RWDECP_RRAuth "Serial Data 16 Protected : Rear Wheel Distance Edge Counter Right Rear Authenticated";
BA_ "SignalType" SG_ 59 RWDECP_LRAuth_Inv "ENM";
BA_ "SignalLongName" SG_ 59 RWDECP_LRAuth_Inv "Serial Data 16 Protected : Rear Wheel Distance Edge Counter Left Rear Authenticated Invalid";
BA_ "SignalType" SG_ 59 RWDECP_RRAuth_Inv "ENM";
BA_ "SignalLongName" SG_ 59 RWDECP_RRAuth_Inv "Serial Data 16 Protected : Rear Wheel Distance Edge Counter Right Rear Authenticated Invalid";
BA_ "SignalLongName" SG_ 59 SATRVP_SecAxlTrqRqValAuth "Serial Data 16 Protected : Secondary Axle Torque Request Value Authenticated";
BA_ "SignalType" SG_ 59 RWDECP_RstOccAuth "ENM";
BA_ "SignalLongName" SG_ 59 RWDECP_RstOccAuth "Serial Data 16 Protected : Rear Wheel Distance Edge Counter Reset Occurred Authenticated";
BA_ "SignalLongName" SG_ 59 TCTR1P_AxlTrqReqValLRAuth "Serial Data 16 Protected : Axle Torque Request Value Left Rear Authenticated";
BA_ "SignalType" SG_ 59 TCTR1P_AxlTrqReqTypRRAuth "ENM";
BA_ "SignalLongName" SG_ 59 TCTR1P_AxlTrqReqTypRRAuth "Serial Data 16 Protected : Axle Torque Request Type Right Rear Authenticated";
BA_ "SignalType" SG_ 59 TCTR1P_AxlTrqReqTypLRAuth "ENM";
BA_ "SignalLongName" SG_ 59 TCTR1P_AxlTrqReqTypLRAuth "Serial Data 16 Protected : Axle Torque Request Type Left Rear Authenticated";
BA_ "SignalLongName" SG_ 59 TCTR1P_AxlTrqReqValRRAuth "Serial Data 16 Protected : Axle Torque Request Value Right Rear Authenticated";
BA_ "SignalLongName" SG_ 59 WhlAngVelLFrtAuth "Serial Data 16 Protected : Wheel Angular Velocity Left Front Authenticated";
BA_ "SignalLongName" SG_ 59 WhlAngVelLRrAuth "Serial Data 16 Protected : Wheel Angular Velocity Left Rear Authenticated";
BA_ "SignalType" SG_ 59 WhlAngVelLFrtAuth_Inv "ENM";
BA_ "SignalLongName" SG_ 59 WhlAngVelLFrtAuth_Inv "Serial Data 16 Protected : Wheel Angular Velocity Left Front Authenticated Invalid";
BA_ "SignalLongName" SG_ 59 WhlAngVelRFrtAuth "Serial Data 16 Protected : Wheel Angular Velocity Right Front Authenticated";
BA_ "SignalType" SG_ 59 WhlAngVelLRrAuth_Inv "ENM";
BA_ "SignalLongName" SG_ 59 WhlAngVelLRrAuth_Inv "Serial Data 16 Protected : Wheel Angular Velocity Left Rear Authenticated Invalid";
BA_ "SignalType" SG_ 59 WhlAngVelRFrtAuth_Inv "ENM";
BA_ "SignalLongName" SG_ 59 WhlAngVelRFrtAuth_Inv "Serial Data 16 Protected : Wheel Angular Velocity Right Front Authenticated Invalid";
BA_ "SignalLongName" SG_ 59 WhlAngVelRRrAuth "Serial Data 16 Protected : Wheel Angular Velocity Right Rear Authenticated";
BA_ "SignalType" SG_ 59 WhlBrkPresAuth_Inv "ENM";
BA_ "SignalLongName" SG_ 59 WhlBrkPresAuth_Inv "Serial Data 16 Protected : Wheel Brake Pressure Authenticated Invalid";
BA_ "SignalType" SG_ 59 WhlAngVelRRrAuth_Inv "ENM";
BA_ "SignalLongName" SG_ 59 WhlAngVelRRrAuth_Inv "Serial Data 16 Protected : Wheel Angular Velocity Right Rear Authenticated Invalid";
BA_ "SignalLongName" SG_ 59 WhlBrkPresLFAuth "Serial Data 16 Protected : Wheel Brake Pressure Left Front Authenticated";
BA_ "SignalLongName" SG_ 59 WhlBrkPresLRAuth "Serial Data 16 Protected : Wheel Brake Pressure Left Rear Authenticated";
BA_ "SignalLongName" SG_ 59 WhlBrkPresRFAuth "Serial Data 16 Protected : Wheel Brake Pressure Right Front Authenticated";
BA_ "SignalLongName" SG_ 59 WhlBrkPresRRAuth "Serial Data 16 Protected : Wheel Brake Pressure Right Rear Authenticated";
BA_ "SignalLongName" SG_ 59 ChsSysPriAxlLtTrqReqAuth "Serial Data 16 Protected : Chassis System Primary Axle Left Torque Request Authenticated";
BA_ "SignalType" SG_ 59 ChsSysPriAxlLtTqRqIntvTpAuth "ENM";
BA_ "SignalLongName" SG_ 59 ChsSysPriAxlLtTqRqIntvTpAuth "Serial Data 16 Protected : Chassis System Primary Axle Left Torque Request Intervention Type Authenticated";
BA_ "SignalLongName" SG_ 59 SD16P_ARC "Serial Data 16 Protected : Alive Rolling Count";
BA_ "SignalType" SG_ 59 ChsSysPriAxlRtTqRqIntvTpAuth "ENM";
BA_ "SignalLongName" SG_ 59 ChsSysPriAxlRtTqRqIntvTpAuth "Serial Data 16 Protected : Chassis System Primary Axle Right Torque Request Intervention Type Authenticated";
BA_ "SignalType" SG_ 59 ChsSysPriAxlLtTrqReqFncAuth "ENM";
BA_ "SignalLongName" SG_ 59 ChsSysPriAxlLtTrqReqFncAuth "Serial Data 16 Protected : Chassis System Primary Axle Left Torque Request Function Authenticated";
BA_ "SignalLongName" SG_ 59 ChsSysPriAxlRtTrqReqAuth "Serial Data 16 Protected : Chassis System Primary Axle Right Torque Request Authenticated";
BA_ "SignalLongName" SG_ 59 VehDynOvrstrUndrstrVal "Serial Data 16 Protected : Vehicle Dynamic Oversteer Understeer Value";
BA_ "SignalType" SG_ 59 ChsSysPrplSysFricBrkTqRqStsAuth "ENM";
BA_ "SignalLongName" SG_ 59 ChsSysPrplSysFricBrkTqRqStsAuth "Serial Data 16 Protected : Chassis System Propulsion System Friction Brake Torque Request Status Authenticated";
BA_ "SignalType" SG_ 59 ChsSysPriAxlRtTrqReqFncAuth "ENM";
BA_ "SignalLongName" SG_ 59 ChsSysPriAxlRtTrqReqFncAuth "Serial Data 16 Protected : Chassis System Primary Axle Right Torque Request Function Authenticated";
BA_ "SignalLongName" SG_ 59 SD16P_Filler "Serial Data 16 Protected : Filler";
BA_ "SignalType" SG_ 59 BrkSysBrkTrqSfcntStndstl "ENM";
BA_ "SignalLongName" SG_ 59 BrkSysBrkTrqSfcntStndstl "Serial Data 16 Protected : Brake System Brake Torque Sufficient for Standstill";
BA_ "SignalType" SG_ 59 VehDynOvrstrUndrstrVal_Inv "ENM";
BA_ "SignalLongName" SG_ 59 VehDynOvrstrUndrstrVal_Inv "Serial Data 16 Protected : Vehicle Dynamic Oversteer Understeer Value Invalid";
BA_ "SignalLongName" SG_ 1342 Sig6846 "Signal5583";
BA_ "SignalLongName" SG_ 1290 Sig5655 "Signal5582";
BA_ "SignalLongName" SG_ 1290 Sig5653 "Signal5581";
BA_ "SignalLongName" SG_ 1290 Sig5654 "Signal5580";
BA_ "SignalType" SG_ 1290 Sig0539 "ENM";
BA_ "SignalLongName" SG_ 1290 Sig0539 "Signal5579";
BA_ "SignalType" SG_ 1290 Sig0538 "ENM";
BA_ "SignalLongName" SG_ 1290 Sig0538 "Signal5578";
BA_ "SignalLongName" SG_ 1290 Sig5652 "Signal5577";
BA_ "SignalLongName" SG_ 1291 Sig6849 "Signal5603";
BA_ "SignalLongName" SG_ 1286 Sig5667 "Signal5602";
BA_ "SignalLongName" SG_ 1286 Sig5665 "Signal5601";
BA_ "SignalLongName" SG_ 1286 Sig5666 "Signal5600";
BA_ "SignalType" SG_ 1286 Sig0454 "ENM";
BA_ "SignalLongName" SG_ 1286 Sig0454 "Signal5599";
BA_ "SignalLongName" SG_ 1286 Sig5664 "Signal5598";
BA_ "SignalLongName" SG_ 1376 SrlDat17_PCSM "Serial Data 17 Protected Counter Sync Message";
BA_ "SignalLongName" SG_ 1308 SD17P_MAC "Serial Data 17 Protected : MAC";
BA_ "SignalLongName" SG_ 1308 SD17P_FCnt "Serial Data 17 Protected : Freshness Counter";
BA_ "SignalType" SG_ 1308 BSSIP_PerfTracMgmtEnbldAuth "ENM";
BA_ "SignalLongName" SG_ 1308 BSSIP_PerfTracMgmtEnbldAuth "Serial Data 17 Protected : Performance Traction Management Enabled Authenticated";
BA_ "SignalType" SG_ 1308 BSSIP_LnchCtlModeStsAuth "ENM";
BA_ "SignalLongName" SG_ 1308 BSSIP_LnchCtlModeStsAuth "Serial Data 17 Protected : Launch Control Mode Status Authenticated";
BA_ "SignalType" SG_ 1308 BSSIP_BrkAsstBrkBstStsAuth "ENM";
BA_ "SignalLongName" SG_ 1308 BSSIP_BrkAsstBrkBstStsAuth "Serial Data 17 Protected : Brake Assist Brake Boost Status Authenticated";
BA_ "SignalLongName" SG_ 1308 WEPRP_WhlEdgesPerRevRrAuth "Serial Data 17 Protected : Wheel Edges Per Revolution Rear Authenticated";
BA_ "SignalLongName" SG_ 1308 WEPRP_WhlEdgesPerRevFrtAuth "Serial Data 17 Protected : Wheel Edges Per Revolution Front Authenticated";
BA_ "SignalLongName" SG_ 1308 SD17P_ARC "Serial Data 17 Protected : Alive Rolling Count";
BA_ "SignalLongName" SG_ 1308 SD17P_Filler "Serial Data 17 Protected : Filler";
BA_ "SignalType" SG_ 1308 BrkSysBrkFldLvlHiIntegSts "ENM";
BA_ "SignalLongName" SG_ 1308 BrkSysBrkFldLvlHiIntegSts "Serial Data 17 Protected : Brake System Brake Fluid Level High Integrity Status";
BA_ "SignalType" SG_ 1308 ChsDynoModeEnbld "ENM";
BA_ "SignalLongName" SG_ 1308 ChsDynoModeEnbld "Serial Data 17 Protected : Chassis Dynamometer Mode Enabled";
BA_ "SignalLongName" SG_ 538 Sig6850 "Signal5664";
BA_ "SignalLongName" SG_ 172 Sig5673 "Signal5666";
BA_ "SignalLongName" SG_ 172 Sig5672 "Signal5665";
BA_ "SignalLongName" SG_ 172 Sig5885 "Signal5669";
BA_ "SignalType" SG_ 172 Sig5884 "ENM";
BA_ "SignalLongName" SG_ 172 Sig5884 "Signal5668";
BA_ "SignalType" SG_ 172 Sig5883 "ENM";
BA_ "SignalLongName" SG_ 172 Sig5883 "Signal5667";
BA_ "SignalLongName" SG_ 172 Sig5886 "Signal5670";
BA_ "SignalLongName" SG_ 172 Sig5888 "Signal5672";
BA_ "SignalType" SG_ 172 Sig5887 "ENM";
BA_ "SignalLongName" SG_ 172 Sig5887 "Signal5671";
BA_ "SignalLongName" SG_ 172 Sig5889 "Signal5673";
BA_ "SignalLongName" SG_ 172 Sig5890 "Signal5674";
BA_ "SignalLongName" SG_ 172 Sig5891 "Signal5675";
BA_ "SignalLongName" SG_ 172 Sig5892 "Signal5676";
BA_ "SignalLongName" SG_ 172 Sig5893 "Signal5677";
BA_ "SignalLongName" SG_ 172 Sig5996 "Signal5681";
BA_ "SignalType" SG_ 172 Sig5895 "ENM";
BA_ "SignalLongName" SG_ 172 Sig5895 "Signal5679";
BA_ "SignalType" SG_ 172 Sig5894 "ENM";
BA_ "SignalLongName" SG_ 172 Sig5894 "Signal5678";
BA_ "SignalType" SG_ 172 Sig5999 "ENM";
BA_ "SignalLongName" SG_ 172 Sig5999 "Signal5683";
BA_ "SignalType" SG_ 172 Sig5998 "ENM";
BA_ "SignalLongName" SG_ 172 Sig5998 "Signal5682";
BA_ "SignalType" SG_ 172 Sig5997 "ENM";
BA_ "SignalLongName" SG_ 172 Sig5997 "Signal5680";
BA_ "SignalType" SG_ 172 Sig6001 "ENM";
BA_ "SignalLongName" SG_ 172 Sig6001 "Signal5685";
BA_ "SignalLongName" SG_ 172 Sig6000 "Signal5684";
BA_ "SignalLongName" SG_ 172 Sig6004 "Signal5686";
BA_ "SignalLongName" SG_ 172 Sig6005 "Signal5687";
BA_ "SignalLongName" SG_ 172 Sig6006 "Signal5688";
BA_ "SignalLongName" SG_ 172 Sig6007 "Signal5689";
BA_ "SignalLongName" SG_ 172 Sig6008 "Signal5690";
BA_ "SignalLongName" SG_ 172 Sig6009 "Signal5691";
BA_ "SignalLongName" SG_ 172 Sig6010 "Signal5692";
BA_ "SignalLongName" SG_ 172 Sig6011 "Signal5693";
BA_ "SignalLongName" SG_ 172 Sig6012 "Signal5694";
BA_ "SignalLongName" SG_ 172 Sig6013 "Signal5695";
BA_ "SignalType" SG_ 172 Sig6015 "ENM";
BA_ "SignalLongName" SG_ 172 Sig6015 "Signal5696";
BA_ "SignalType" SG_ 172 Sig6017 "ENM";
BA_ "SignalLongName" SG_ 172 Sig6017 "Signal5697";
BA_ "SignalLongName" SG_ 172 Sig6016 "Signal5698";
BA_ "SignalLongName" SG_ 172 Sig6020 "Signal5701";
BA_ "SignalType" SG_ 172 Sig6019 "ENM";
BA_ "SignalLongName" SG_ 172 Sig6019 "Signal5700";
BA_ "SignalType" SG_ 172 Sig6018 "ENM";
BA_ "SignalLongName" SG_ 172 Sig6018 "Signal5699";
BA_ "SignalLongName" SG_ 172 Sig6024 "Signal5703";
BA_ "SignalType" SG_ 172 Sig6021 "ENM";
BA_ "SignalLongName" SG_ 172 Sig6021 "Signal5702";
BA_ "SignalLongName" SG_ 172 Sig6025 "Signal5704";
BA_ "SignalLongName" SG_ 172 Sig6026 "Signal5705";
BA_ "SignalLongName" SG_ 172 Sig6027 "Signal5706";
BA_ "SignalLongName" SG_ 172 Sig6028 "Signal5707";
BA_ "SignalLongName" SG_ 172 Sig6029 "Signal5709";
BA_ "SignalLongName" SG_ 172 Sig6030 "Signal5710";
BA_ "SignalLongName" SG_ 172 Sig6031 "Signal5711";
BA_ "SignalLongName" SG_ 172 Sig6032 "Signal5712";
BA_ "SignalLongName" SG_ 172 Sig6033 "Signal5713";
BA_ "SignalLongName" SG_ 172 Sig6034 "Signal5708";
BA_ "SignalLongName" SG_ 172 Sig6036 "Signal5716";
BA_ "SignalType" SG_ 172 Sig6035 "ENM";
BA_ "SignalLongName" SG_ 172 Sig6035 "Signal5714";
BA_ "SignalType" SG_ 172 Sig6039 "ENM";
BA_ "SignalLongName" SG_ 172 Sig6039 "Signal5718";
BA_ "SignalType" SG_ 172 Sig6038 "ENM";
BA_ "SignalLongName" SG_ 172 Sig6038 "Signal5717";
BA_ "SignalType" SG_ 172 Sig6037 "ENM";
BA_ "SignalLongName" SG_ 172 Sig6037 "Signal5715";
BA_ "SignalType" SG_ 172 Sig6041 "ENM";
BA_ "SignalLongName" SG_ 172 Sig6041 "Signal5720";
BA_ "SignalLongName" SG_ 172 Sig6040 "Signal5719";
BA_ "SignalLongName" SG_ 172 Sig6044 "Signal5721";
BA_ "SignalLongName" SG_ 172 Sig6045 "Signal5722";
BA_ "SignalLongName" SG_ 172 Sig6046 "Signal5723";
BA_ "SignalLongName" SG_ 172 Sig6047 "Signal5724";
BA_ "SignalLongName" SG_ 172 Sig6048 "Signal5725";
BA_ "SignalLongName" SG_ 172 Sig6049 "Signal5727";
BA_ "SignalLongName" SG_ 172 Sig6050 "Signal5728";
BA_ "SignalLongName" SG_ 172 Sig6051 "Signal5729";
BA_ "SignalLongName" SG_ 172 Sig6052 "Signal5730";
BA_ "SignalLongName" SG_ 172 Sig6053 "Signal5731";
BA_ "SignalLongName" SG_ 172 Sig6054 "Signal5726";
BA_ "SignalType" SG_ 172 Sig6055 "ENM";
BA_ "SignalLongName" SG_ 172 Sig6055 "Signal5732";
BA_ "SignalLongName" SG_ 172 Sig6074 "Signal5733";
BA_ "SignalLongName" SG_ 170 Sig5675 "Signal5735";
BA_ "SignalLongName" SG_ 170 Sig5674 "Signal5734";
BA_ "SignalLongName" SG_ 170 Sig5898 "Signal5738";
BA_ "SignalType" SG_ 170 Sig5897 "ENM";
BA_ "SignalLongName" SG_ 170 Sig5897 "Signal5737";
BA_ "SignalType" SG_ 170 Sig5896 "ENM";
BA_ "SignalLongName" SG_ 170 Sig5896 "Signal5736";
BA_ "SignalLongName" SG_ 170 Sig5899 "Signal5739";
BA_ "SignalLongName" SG_ 170 Sig5901 "Signal5741";
BA_ "SignalType" SG_ 170 Sig5900 "ENM";
BA_ "SignalLongName" SG_ 170 Sig5900 "Signal5740";
BA_ "SignalLongName" SG_ 170 Sig5902 "Signal5742";
BA_ "SignalLongName" SG_ 170 Sig5903 "Signal5743";
BA_ "SignalLongName" SG_ 170 Sig5904 "Signal5744";
BA_ "SignalLongName" SG_ 170 Sig5905 "Signal5745";
BA_ "SignalLongName" SG_ 170 Sig5906 "Signal5746";
BA_ "SignalLongName" SG_ 170 Sig6056 "Signal5750";
BA_ "SignalType" SG_ 170 Sig5908 "ENM";
BA_ "SignalLongName" SG_ 170 Sig5908 "Signal5748";
BA_ "SignalType" SG_ 170 Sig5907 "ENM";
BA_ "SignalLongName" SG_ 170 Sig5907 "Signal5747";
BA_ "SignalType" SG_ 170 Sig6059 "ENM";
BA_ "SignalLongName" SG_ 170 Sig6059 "Signal5752";
BA_ "SignalType" SG_ 170 Sig6058 "ENM";
BA_ "SignalLongName" SG_ 170 Sig6058 "Signal5751";
BA_ "SignalType" SG_ 170 Sig6057 "ENM";
BA_ "SignalLongName" SG_ 170 Sig6057 "Signal5749";
BA_ "SignalType" SG_ 170 Sig6061 "ENM";
BA_ "SignalLongName" SG_ 170 Sig6061 "Signal5754";
BA_ "SignalLongName" SG_ 170 Sig6060 "Signal5753";
BA_ "SignalLongName" SG_ 170 Sig6064 "Signal5755";
BA_ "SignalLongName" SG_ 170 Sig6065 "Signal5756";
BA_ "SignalLongName" SG_ 170 Sig6066 "Signal5757";
BA_ "SignalLongName" SG_ 170 Sig6067 "Signal5758";
BA_ "SignalLongName" SG_ 170 Sig6068 "Signal5759";
BA_ "SignalLongName" SG_ 170 Sig6069 "Signal5760";
BA_ "SignalLongName" SG_ 170 Sig6070 "Signal5761";
BA_ "SignalLongName" SG_ 170 Sig6071 "Signal5762";
BA_ "SignalLongName" SG_ 170 Sig6072 "Signal5763";
BA_ "SignalLongName" SG_ 170 Sig6073 "Signal5764";
BA_ "SignalType" SG_ 170 Sig6075 "ENM";
BA_ "SignalLongName" SG_ 170 Sig6075 "Signal5765";
BA_ "SignalType" SG_ 170 Sig6077 "ENM";
BA_ "SignalLongName" SG_ 170 Sig6077 "Signal5766";
BA_ "SignalLongName" SG_ 170 Sig6076 "Signal5767";
BA_ "SignalLongName" SG_ 170 Sig6080 "Signal5770";
BA_ "SignalType" SG_ 170 Sig6079 "ENM";
BA_ "SignalLongName" SG_ 170 Sig6079 "Signal5769";
BA_ "SignalType" SG_ 170 Sig6078 "ENM";
BA_ "SignalLongName" SG_ 170 Sig6078 "Signal5768";
BA_ "SignalLongName" SG_ 170 Sig6084 "Signal5772";
BA_ "SignalType" SG_ 170 Sig6081 "ENM";
BA_ "SignalLongName" SG_ 170 Sig6081 "Signal5771";
BA_ "SignalLongName" SG_ 170 Sig6085 "Signal5773";
BA_ "SignalLongName" SG_ 170 Sig6086 "Signal5774";
BA_ "SignalLongName" SG_ 170 Sig6087 "Signal5775";
BA_ "SignalLongName" SG_ 170 Sig6088 "Signal5776";
BA_ "SignalLongName" SG_ 170 Sig6089 "Signal5778";
BA_ "SignalLongName" SG_ 170 Sig6090 "Signal5779";
BA_ "SignalLongName" SG_ 170 Sig6091 "Signal5780";
BA_ "SignalLongName" SG_ 170 Sig6092 "Signal5781";
BA_ "SignalLongName" SG_ 170 Sig6093 "Signal5782";
BA_ "SignalLongName" SG_ 170 Sig6094 "Signal5777";
BA_ "SignalLongName" SG_ 170 Sig6096 "Signal5785";
BA_ "SignalType" SG_ 170 Sig6095 "ENM";
BA_ "SignalLongName" SG_ 170 Sig6095 "Signal5783";
BA_ "SignalType" SG_ 170 Sig6099 "ENM";
BA_ "SignalLongName" SG_ 170 Sig6099 "Signal5787";
BA_ "SignalType" SG_ 170 Sig6098 "ENM";
BA_ "SignalLongName" SG_ 170 Sig6098 "Signal5786";
BA_ "SignalType" SG_ 170 Sig6097 "ENM";
BA_ "SignalLongName" SG_ 170 Sig6097 "Signal5784";
BA_ "SignalType" SG_ 170 Sig6101 "ENM";
BA_ "SignalLongName" SG_ 170 Sig6101 "Signal5789";
BA_ "SignalLongName" SG_ 170 Sig6100 "Signal5788";
BA_ "SignalLongName" SG_ 170 Sig6104 "Signal5790";
BA_ "SignalLongName" SG_ 170 Sig6105 "Signal5791";
BA_ "SignalLongName" SG_ 170 Sig6106 "Signal5792";
BA_ "SignalLongName" SG_ 170 Sig6107 "Signal5793";
BA_ "SignalLongName" SG_ 170 Sig6108 "Signal5794";
BA_ "SignalLongName" SG_ 170 Sig6109 "Signal5796";
BA_ "SignalLongName" SG_ 170 Sig6110 "Signal5797";
BA_ "SignalLongName" SG_ 170 Sig6111 "Signal5798";
BA_ "SignalLongName" SG_ 170 Sig6112 "Signal5799";
BA_ "SignalLongName" SG_ 170 Sig6113 "Signal5800";
BA_ "SignalLongName" SG_ 170 Sig6114 "Signal5795";
BA_ "SignalType" SG_ 170 Sig6115 "ENM";
BA_ "SignalLongName" SG_ 170 Sig6115 "Signal5801";
BA_ "SignalLongName" SG_ 170 Sig6134 "Signal5802";
BA_ "SignalLongName" SG_ 169 Sig5677 "Signal5804";
BA_ "SignalLongName" SG_ 169 Sig5676 "Signal5803";
BA_ "SignalLongName" SG_ 169 Sig5911 "Signal5807";
BA_ "SignalType" SG_ 169 Sig5910 "ENM";
BA_ "SignalLongName" SG_ 169 Sig5910 "Signal5806";
BA_ "SignalType" SG_ 169 Sig5909 "ENM";
BA_ "SignalLongName" SG_ 169 Sig5909 "Signal5805";
BA_ "SignalLongName" SG_ 169 Sig5912 "Signal5808";
BA_ "SignalLongName" SG_ 169 Sig5914 "Signal5810";
BA_ "SignalType" SG_ 169 Sig5913 "ENM";
BA_ "SignalLongName" SG_ 169 Sig5913 "Signal5809";
BA_ "SignalLongName" SG_ 169 Sig5915 "Signal5811";
BA_ "SignalLongName" SG_ 169 Sig5916 "Signal5812";
BA_ "SignalLongName" SG_ 169 Sig5917 "Signal5813";
BA_ "SignalLongName" SG_ 169 Sig5918 "Signal5814";
BA_ "SignalLongName" SG_ 169 Sig5919 "Signal5815";
BA_ "SignalLongName" SG_ 169 Sig5956 "Signal5819";
BA_ "SignalType" SG_ 169 Sig5921 "ENM";
BA_ "SignalLongName" SG_ 169 Sig5921 "Signal5817";
BA_ "SignalType" SG_ 169 Sig5920 "ENM";
BA_ "SignalLongName" SG_ 169 Sig5920 "Signal5816";
BA_ "SignalType" SG_ 169 Sig5959 "ENM";
BA_ "SignalLongName" SG_ 169 Sig5959 "Signal5821";
BA_ "SignalType" SG_ 169 Sig5958 "ENM";
BA_ "SignalLongName" SG_ 169 Sig5958 "Signal5820";
BA_ "SignalType" SG_ 169 Sig5957 "ENM";
BA_ "SignalLongName" SG_ 169 Sig5957 "Signal5818";
BA_ "SignalType" SG_ 169 Sig5961 "ENM";
BA_ "SignalLongName" SG_ 169 Sig5961 "Signal5823";
BA_ "SignalLongName" SG_ 169 Sig5960 "Signal5822";
BA_ "SignalLongName" SG_ 169 Sig5964 "Signal5824";
BA_ "SignalLongName" SG_ 169 Sig5965 "Signal5825";
BA_ "SignalLongName" SG_ 169 Sig5966 "Signal5826";
BA_ "SignalLongName" SG_ 169 Sig5967 "Signal5827";
BA_ "SignalLongName" SG_ 169 Sig5968 "Signal5828";
BA_ "SignalLongName" SG_ 169 Sig5969 "Signal5830";
BA_ "SignalLongName" SG_ 169 Sig5970 "Signal5831";
BA_ "SignalLongName" SG_ 169 Sig5971 "Signal5832";
BA_ "SignalLongName" SG_ 169 Sig5972 "Signal5833";
BA_ "SignalLongName" SG_ 169 Sig5973 "Signal5834";
BA_ "SignalLongName" SG_ 169 Sig5974 "Signal5829";
BA_ "SignalType" SG_ 169 Sig5975 "ENM";
BA_ "SignalLongName" SG_ 169 Sig5975 "Signal5835";
BA_ "SignalType" SG_ 169 Sig6117 "ENM";
BA_ "SignalLongName" SG_ 169 Sig6117 "Signal5836";
BA_ "SignalLongName" SG_ 169 Sig6116 "Signal5837";
BA_ "SignalLongName" SG_ 169 Sig6120 "Signal5840";
BA_ "SignalType" SG_ 169 Sig6119 "ENM";
BA_ "SignalLongName" SG_ 169 Sig6119 "Signal5839";
BA_ "SignalType" SG_ 169 Sig6118 "ENM";
BA_ "SignalLongName" SG_ 169 Sig6118 "Signal5838";
BA_ "SignalLongName" SG_ 169 Sig6124 "Signal5842";
BA_ "SignalType" SG_ 169 Sig6121 "ENM";
BA_ "SignalLongName" SG_ 169 Sig6121 "Signal5841";
BA_ "SignalLongName" SG_ 169 Sig6125 "Signal5843";
BA_ "SignalLongName" SG_ 169 Sig6126 "Signal5844";
BA_ "SignalLongName" SG_ 169 Sig6127 "Signal5845";
BA_ "SignalLongName" SG_ 169 Sig6128 "Signal5846";
BA_ "SignalLongName" SG_ 169 Sig6129 "Signal5847";
BA_ "SignalLongName" SG_ 169 Sig6130 "Signal5848";
BA_ "SignalLongName" SG_ 169 Sig6131 "Signal5849";
BA_ "SignalLongName" SG_ 169 Sig6132 "Signal5850";
BA_ "SignalLongName" SG_ 169 Sig6133 "Signal5851";
BA_ "SignalLongName" SG_ 169 Sig6136 "Signal5854";
BA_ "SignalType" SG_ 169 Sig6135 "ENM";
BA_ "SignalLongName" SG_ 169 Sig6135 "Signal5852";
BA_ "SignalType" SG_ 169 Sig6139 "ENM";
BA_ "SignalLongName" SG_ 169 Sig6139 "Signal5856";
BA_ "SignalType" SG_ 169 Sig6138 "ENM";
BA_ "SignalLongName" SG_ 169 Sig6138 "Signal5855";
BA_ "SignalType" SG_ 169 Sig6137 "ENM";
BA_ "SignalLongName" SG_ 169 Sig6137 "Signal5853";
BA_ "SignalType" SG_ 169 Sig6141 "ENM";
BA_ "SignalLongName" SG_ 169 Sig6141 "Signal5858";
BA_ "SignalLongName" SG_ 169 Sig6140 "Signal5857";
BA_ "SignalLongName" SG_ 169 Sig6144 "Signal5859";
BA_ "SignalLongName" SG_ 169 Sig6145 "Signal5860";
BA_ "SignalLongName" SG_ 169 Sig6146 "Signal5861";
BA_ "SignalLongName" SG_ 169 Sig6147 "Signal5862";
BA_ "SignalLongName" SG_ 169 Sig6148 "Signal5863";
BA_ "SignalLongName" SG_ 169 Sig6149 "Signal5865";
BA_ "SignalLongName" SG_ 169 Sig6150 "Signal5866";
BA_ "SignalLongName" SG_ 169 Sig6151 "Signal5867";
BA_ "SignalLongName" SG_ 169 Sig6152 "Signal5868";
BA_ "SignalLongName" SG_ 169 Sig6153 "Signal5869";
BA_ "SignalLongName" SG_ 169 Sig6154 "Signal5864";
BA_ "SignalType" SG_ 169 Sig6155 "ENM";
BA_ "SignalLongName" SG_ 169 Sig6155 "Signal5870";
BA_ "SignalLongName" SG_ 167 Sig5679 "Signal5872";
BA_ "SignalLongName" SG_ 167 Sig5678 "Signal5871";
BA_ "SignalType" SG_ 167 Sig5777 "ENM";
BA_ "SignalLongName" SG_ 167 Sig5777 "Signal5881";
BA_ "SignalType" SG_ 167 Sig5776 "ENM";
BA_ "SignalLongName" SG_ 167 Sig5776 "Signal5880";
BA_ "SignalType" SG_ 167 Sig5779 "ENM";
BA_ "SignalLongName" SG_ 167 Sig5779 "Signal5883";
BA_ "SignalLongName" SG_ 167 Sig5778 "Signal5882";
BA_ "SignalLongName" SG_ 167 Sig5781 "Signal5884";
BA_ "SignalType" SG_ 167 Sig5783 "ENM";
BA_ "SignalLongName" SG_ 167 Sig5783 "Signal5886";
BA_ "SignalType" SG_ 167 Sig5782 "ENM";
BA_ "SignalLongName" SG_ 167 Sig5782 "Signal5885";
BA_ "SignalLongName" SG_ 167 Sig5786 "Signal5875";
BA_ "SignalType" SG_ 167 Sig5785 "ENM";
BA_ "SignalLongName" SG_ 167 Sig5785 "Signal5874";
BA_ "SignalType" SG_ 167 Sig5784 "ENM";
BA_ "SignalLongName" SG_ 167 Sig5784 "Signal5873";
BA_ "SignalLongName" SG_ 167 Sig5789 "Signal5877";
BA_ "SignalType" SG_ 167 Sig5787 "ENM";
BA_ "SignalLongName" SG_ 167 Sig5787 "Signal5876";
BA_ "SignalType" SG_ 167 Sig5792 "ENM";
BA_ "SignalLongName" SG_ 167 Sig5792 "Signal5887";
BA_ "SignalType" SG_ 167 Sig5791 "ENM";
BA_ "SignalLongName" SG_ 167 Sig5791 "Signal5879";
BA_ "SignalType" SG_ 167 Sig5790 "ENM";
BA_ "SignalLongName" SG_ 167 Sig5790 "Signal5878";
BA_ "SignalLongName" SG_ 167 Sig5794 "Signal5889";
BA_ "SignalType" SG_ 167 Sig5793 "ENM";
BA_ "SignalLongName" SG_ 167 Sig5793 "Signal5888";
BA_ "SignalLongName" SG_ 167 Sig5797 "Signal5891";
BA_ "SignalType" SG_ 167 Sig5795 "ENM";
BA_ "SignalLongName" SG_ 167 Sig5795 "Signal5890";
BA_ "SignalType" SG_ 167 Sig5798 "ENM";
BA_ "SignalLongName" SG_ 167 Sig5798 "Signal5892";
BA_ "SignalLongName" SG_ 167 Sig5802 "Signal5896";
BA_ "SignalType" SG_ 167 Sig5801 "ENM";
BA_ "SignalLongName" SG_ 167 Sig5801 "Signal5895";
BA_ "SignalType" SG_ 167 Sig5800 "ENM";
BA_ "SignalLongName" SG_ 167 Sig5800 "Signal5894";
BA_ "SignalType" SG_ 167 Sig5799 "ENM";
BA_ "SignalLongName" SG_ 167 Sig5799 "Signal5893";
BA_ "SignalType" SG_ 167 Sig5803 "ENM";
BA_ "SignalLongName" SG_ 167 Sig5803 "Signal5897";
BA_ "SignalLongName" SG_ 167 Sig5805 "Signal5898";
BA_ "SignalType" SG_ 167 Sig5807 "ENM";
BA_ "SignalLongName" SG_ 167 Sig5807 "Signal5900";
BA_ "SignalType" SG_ 167 Sig5806 "ENM";
BA_ "SignalLongName" SG_ 167 Sig5806 "Signal5899";
BA_ "SignalLongName" SG_ 167 Sig5810 "Signal5903";
BA_ "SignalType" SG_ 167 Sig5809 "ENM";
BA_ "SignalLongName" SG_ 167 Sig5809 "Signal5902";
BA_ "SignalType" SG_ 167 Sig5808 "ENM";
BA_ "SignalLongName" SG_ 167 Sig5808 "Signal5901";
BA_ "SignalLongName" SG_ 167 Sig5813 "Signal5905";
BA_ "SignalType" SG_ 167 Sig5811 "ENM";
BA_ "SignalLongName" SG_ 167 Sig5811 "Signal5904";
BA_ "SignalType" SG_ 167 Sig5817 "ENM";
BA_ "SignalLongName" SG_ 167 Sig5817 "Signal5909";
BA_ "SignalType" SG_ 167 Sig5816 "ENM";
BA_ "SignalLongName" SG_ 167 Sig5816 "Signal5908";
BA_ "SignalType" SG_ 167 Sig5815 "ENM";
BA_ "SignalLongName" SG_ 167 Sig5815 "Signal5907";
BA_ "SignalType" SG_ 167 Sig5814 "ENM";
BA_ "SignalLongName" SG_ 167 Sig5814 "Signal5906";
BA_ "SignalLongName" SG_ 167 Sig5818 "Signal5910";
BA_ "SignalLongName" SG_ 167 Sig5821 "Signal5912";
BA_ "SignalType" SG_ 167 Sig5819 "ENM";
BA_ "SignalLongName" SG_ 167 Sig5819 "Signal5911";
BA_ "SignalType" SG_ 167 Sig5822 "ENM";
BA_ "SignalLongName" SG_ 167 Sig5822 "Signal5913";
BA_ "SignalLongName" SG_ 167 Sig5826 "Signal5917";
BA_ "SignalType" SG_ 167 Sig5825 "ENM";
BA_ "SignalLongName" SG_ 167 Sig5825 "Signal5916";
BA_ "SignalType" SG_ 167 Sig5824 "ENM";
BA_ "SignalLongName" SG_ 167 Sig5824 "Signal5915";
BA_ "SignalType" SG_ 167 Sig5823 "ENM";
BA_ "SignalLongName" SG_ 167 Sig5823 "Signal5914";
BA_ "SignalLongName" SG_ 167 Sig5829 "Signal5919";
BA_ "SignalType" SG_ 167 Sig5827 "ENM";
BA_ "SignalLongName" SG_ 167 Sig5827 "Signal5918";
BA_ "SignalType" SG_ 167 Sig5832 "ENM";
BA_ "SignalLongName" SG_ 167 Sig5832 "Signal5922";
BA_ "SignalType" SG_ 167 Sig5831 "ENM";
BA_ "SignalLongName" SG_ 167 Sig5831 "Signal5921";
BA_ "SignalType" SG_ 167 Sig5830 "ENM";
BA_ "SignalLongName" SG_ 167 Sig5830 "Signal5920";
BA_ "SignalLongName" SG_ 167 Sig5834 "Signal5924";
BA_ "SignalType" SG_ 167 Sig5833 "ENM";
BA_ "SignalLongName" SG_ 167 Sig5833 "Signal5923";
BA_ "SignalLongName" SG_ 167 Sig5837 "Signal5926";
BA_ "SignalType" SG_ 167 Sig5835 "ENM";
BA_ "SignalLongName" SG_ 167 Sig5835 "Signal5925";
BA_ "SignalType" SG_ 167 Sig5838 "ENM";
BA_ "SignalLongName" SG_ 167 Sig5838 "Signal5927";
BA_ "SignalType" SG_ 167 Sig5841 "ENM";
BA_ "SignalLongName" SG_ 167 Sig5841 "Signal5930";
BA_ "SignalType" SG_ 167 Sig5840 "ENM";
BA_ "SignalLongName" SG_ 167 Sig5840 "Signal5929";
BA_ "SignalType" SG_ 167 Sig5839 "ENM";
BA_ "SignalLongName" SG_ 167 Sig5839 "Signal5928";
BA_ "SignalType" SG_ 167 Sig5843 "ENM";
BA_ "SignalLongName" SG_ 167 Sig5843 "Signal5932";
BA_ "SignalLongName" SG_ 167 Sig5842 "Signal5931";
BA_ "SignalLongName" SG_ 167 Sig5845 "Signal5933";
BA_ "SignalType" SG_ 167 Sig5847 "ENM";
BA_ "SignalLongName" SG_ 167 Sig5847 "Signal5935";
BA_ "SignalType" SG_ 167 Sig5846 "ENM";
BA_ "SignalLongName" SG_ 167 Sig5846 "Signal5934";
BA_ "SignalLongName" SG_ 167 Sig5850 "Signal5938";
BA_ "SignalType" SG_ 167 Sig5849 "ENM";
BA_ "SignalLongName" SG_ 167 Sig5849 "Signal5937";
BA_ "SignalType" SG_ 167 Sig5848 "ENM";
BA_ "SignalLongName" SG_ 167 Sig5848 "Signal5936";
BA_ "SignalLongName" SG_ 167 Sig5853 "Signal5940";
BA_ "SignalType" SG_ 167 Sig5851 "ENM";
BA_ "SignalLongName" SG_ 167 Sig5851 "Signal5939";
BA_ "SignalLongName" SG_ 167 Sig5962 "Signal5945";
BA_ "SignalType" SG_ 167 Sig5855 "ENM";
BA_ "SignalLongName" SG_ 167 Sig5855 "Signal5942";
BA_ "SignalType" SG_ 167 Sig5854 "ENM";
BA_ "SignalLongName" SG_ 167 Sig5854 "Signal5941";
BA_ "SignalLongName" SG_ 167 Sig5963 "Signal5946";
BA_ "SignalLongName" SG_ 167 Sig5982 "Signal5943";
BA_ "SignalLongName" SG_ 167 Sig5983 "Signal5944";
BA_ "SignalLongName" SG_ 167 Sig6002 "Signal5947";
BA_ "SignalLongName" SG_ 167 Sig6003 "Signal5948";
BA_ "SignalLongName" SG_ 167 Sig6022 "Signal5949";
BA_ "SignalLongName" SG_ 167 Sig6023 "Signal5950";
BA_ "SignalLongName" SG_ 167 Sig6042 "Signal5951";
BA_ "SignalLongName" SG_ 167 Sig6043 "Signal5952";
BA_ "SignalLongName" SG_ 167 Sig6062 "Signal5953";
BA_ "SignalLongName" SG_ 167 Sig6063 "Signal5954";
BA_ "SignalLongName" SG_ 167 Sig6082 "Signal5955";
BA_ "SignalLongName" SG_ 167 Sig6083 "Signal5956";
BA_ "SignalLongName" SG_ 167 Sig6102 "Signal5957";
BA_ "SignalLongName" SG_ 167 Sig6103 "Signal5958";
BA_ "SignalLongName" SG_ 167 Sig6122 "Signal5959";
BA_ "SignalLongName" SG_ 167 Sig6123 "Signal5960";
BA_ "SignalLongName" SG_ 167 Sig6142 "Signal5961";
BA_ "SignalLongName" SG_ 167 Sig6143 "Signal5962";
VAL_ 49 PGI3P_PrplCpbltyStsPriAuth 0 "Request Not Limited" 1 "Request Value Limited Minimum" 2 "Request Value Limited Maximum" 3 "Request Rate Limited" ;
VAL_ 49 PGI3P_PrplArbtrtnStsPriAuth 0 "No ADS data" 1 "ADS Active" 2 "Traction Active" 3 "Lost Axle Arbitration" ;
VAL_ 49 PGI3P_ADSRedntATReqStsPriAuth 0 "Unknown" 1 "Data Valid" 2 "Data Invalid" 3 "Serial Data Failure" ;
VAL_ 49 PGI3P_ADSMnAxlTrqReqStsPriAuth 0 "Unknown" 1 "Data Valid" 2 "Data Invalid" 3 "Serial Data Failure" ;
VAL_ 49 PrplSysFricBrkTrqReqTypAuth 0 "No Action" 1 "Braking Not Requested" 2 "Brake Per Torque Request" 3 "Hold" ;
VAL_ 49 PGI3P_PrplSysStsPriAuth 0 "Initialize" 1 "Full Function" 2 "Degraded Mode 1" 3 "Degraded Mode 2" 4 "Degraded Mode 3" 5 "Degraded Mode 4" 6 "Degraded Mode 5" ;
VAL_ 1320 PCIP_HzrdLgtsOnReqdAuth 0 "FALSE" 1 "TRUE" ;
VAL_ 1320 PCIP_HybVehHiVltgDsblReqdAuth 0 "FALSE" 1 "TRUE" ;
VAL_ 1320 PCIP_HVCrshImpSnsSysDsbldAuth 0 "FALSE" 1 "TRUE" ;
VAL_ 1320 PCIP_HVACBlwDsblReqdAuth 0 "FALSE" 1 "TRUE" ;
VAL_ 1320 PCIP_FuelCutOffReqdAuth 0 "FALSE" 1 "TRUE" ;
VAL_ 1320 PCIP_DrUnlckReqdAuth 0 "FALSE" 1 "TRUE" ;
VAL_ 1320 PCIP_CruzCtlDsblReqdAuth 0 "FALSE" 1 "TRUE" ;
VAL_ 1320 PCIP_BrkActReqdAuth 0 "FALSE" 1 "TRUE" ;
VAL_ 1320 PCIP_NftnFrtImpPrtnsrSevAchAuth 0 "FALSE" 1 "TRUE" ;
VAL_ 1320 PCIP_MemStRclDsblReqdAuth 0 "FALSE" 1 "TRUE" ;
VAL_ 1320 PCIP_IntrLgtOnReqdAuth 0 "FALSE" 1 "TRUE" ;
VAL_ 1320 PCIP_NtfnLtSdSevAchvdAuth 0 "FALSE" 1 "TRUE" ;
VAL_ 1320 PCIP_NtfnFrtImpStg2SevAchvdAuth 0 "FALSE" 1 "TRUE" ;
VAL_ 1320 PCIP_NtfnFrtImpStg1SevAchvdAuth 0 "FALSE" 1 "TRUE" ;
VAL_ 1320 PCIP_NtfnEvntStsAuth 0 "No Event" 1 "Near Deploy Event" 2 "Deployment Event" ;
VAL_ 1320 PCIP_eCallReqdAuth 0 "FALSE" 1 "TRUE" ;
VAL_ 1320 PCIP_NtfnRtSdSevAchvdAuth 0 "FALSE" 1 "TRUE" ;
VAL_ 1320 PCIP_NtfnRrImpSevAchvdAuth 0 "FALSE" 1 "TRUE" ;
VAL_ 1320 PCIP_NtfnRlOvrSevAchvdAuth 0 "FALSE" 1 "TRUE" ;
VAL_ 1320 PCIP_NtfnPedtrnPrtctnSevAchAuth 0 "FALSE" 1 "TRUE" ;
VAL_ 97 POFT_PstnOfstFrmTrmLF_Inv 0 "FALSE" 1 "TRUE" ;
VAL_ 97 POFT_PstnOfstFrmTrmLR_Inv 0 "FALSE" 1 "TRUE" ;
VAL_ 97 POFT_PstnOfstFrmTrmRF_Inv 0 "FALSE" 1 "TRUE" ;
VAL_ 97 POFT_PstnOfstFrmTrmRR_Inv 0 "FALSE" 1 "TRUE" ;
VAL_ 97 POFT_SpnsnTrmPstnLrnCmplt 0 "FALSE" 1 "TRUE" ;
VAL_ 870 PSIP_StrgAsstRdcdLvl3IndOnAuth 0 "FALSE" 1 "TRUE" ;
VAL_ 870 PSIP_StrgAsstRdcdLvl2IndOnAuth 0 "FALSE" 1 "TRUE" ;
VAL_ 870 PSIP_StrgAsstRdcdIndOnAuth 0 "FALSE" 1 "TRUE" ;
VAL_ 870 PSIP_PwrStrgIndOnAuth 0 "FALSE" 1 "TRUE" ;
VAL_ 2147745823 Sig5023 0 "FALSE" 1 "TRUE" ;
VAL_ 874 SATCRTP_SecAxlTrqCplRqTyAuth 0 "No Action" 1 "Maximum Allowed Torque" 2 "Minimum Allowed Torque" 3 "Control to Requested Torque" ;
VAL_ 88 SAP_PwrtrnXferCaseModeAuth 0 "2 Wheel Drive High" 1 "4 Wheel Drive High" 2 "4 Wheel Drive Low" 3 "Neutral" ;
VAL_ 88 SAP_SecAxlOpMdAuth 0 "2WD High" 1 "4WD High Rigid Coupling" 2 "4WD Low Rigid Coupling" 3 "AWD Active Single Clutch" 4 "4WD High Active Clutch" 5 "4WD Low Active Clutch" 6 "AWD Active Twin Clutch" 7 "2WD Low" 8 "Unknown" 9 "Neutral" ;
VAL_ 88 SAP_SecAxl4WDAWDStatAuth 0 "Normal" 1 "Temporary_Limited" 2 "Temporary_Inhibit" 3 "Permanently_Failed" ;
VAL_ 88 SAP_SecAxl4WDAWDEstTrqAuth_Inv 0 "FALSE" 1 "TRUE" ;
VAL_ 88 SAP_XferCaseRngShfPndgAuth 0 "None" 1 "ShiftOutofHighRange" 2 "ShiftOutofLowRange" 3 "ShiftOutofNeutralRange" ;
VAL_ 88 SAP_SecAxlOpMdAuth_Inv 0 "FALSE" 1 "TRUE" ;
VAL_ 868 SADSVTSLP_VehTpSpdLimReqTypAuth 0 "Inactive" 1 "Faulted" 2 "Safety_woBrake" 3 "Safety_wBrake" 4 "OBD" 5 "nonOBD" 6 "Legislated" ;
VAL_ 1317 SLVFSP_SpdLimVsnFsdSpdUntAuth 0 "km/h" 1 "mph" ;
VAL_ 1317 SLVFSP_SpdLimVsnFsdSpdNwDtdAuth 0 "FALSE" 1 "TRUE" ;
VAL_ 1317 SLVFSP_SpdLimVsnFsdSpdAuth_DuD 0 "FALSE" 1 "TRUE" ;
VAL_ 1309 SGI2P_AirSpnsnRdHghtLwrActnAuth 0 "None" 1 "Slow" 2 "Medium (Exhaust)" 3 "Fast" ;
VAL_ 1309 SGI2P_AirSpnsnRdHghtActvAxlAuth 0 "None" 1 "Front" 2 "Rear" 3 "Both" 4 "Pending" ;
VAL_ 1309 SGI2P_AirSpnsnRdHghtActlStsAuth 0 "Faulted" 1 "Entry/Exit" 2 "Lowered 3(Stability)" 3 "Lowered 2 (Sport)" 4 "Lowered 1 (Aero)" 5 "Showroom" 6 "Normal" 7 "Raised 1" 8 "Raised 2" 9 "Raised 3" ;
VAL_ 1309 SGI2P_AirSpnsnRdHghtTgtStsAuth 0 "Faulted" 1 "Entry/Exit" 2 "Lowered 3(Stability)" 3 "Lowered 2 (Sport)" 4 "Lowered 1 (Aero)" 5 "Showroom" 6 "Normal" 7 "Raised 1" 8 "Raised 2" 9 "Raised 3" ;
VAL_ 1309 SGI2P_AirSpnsnRdHghtRseActnAuth 0 "None" 1 "Slow(i.e. compressor)" 2 "Medium (i.e. Boost)" 3 "Fast (i.e. Reservoir)" ;
VAL_ 1277 UpftrSnwPlwModeActv_Inv 0 "FALSE" 1 "TRUE" ;
VAL_ 1277 UpftrSnwPlwModeActv 0 "FALSE" 1 "TRUE" ;
VAL_ 1277 UpftrSnwPlwHdlmpsActv 0 "FALSE" 1 "TRUE" ;
VAL_ 1277 UpftrLckReq 0 "No Request" 1 "Lock All" 2 "Unlock All" ;
VAL_ 1277 UpftrAutoShtdnInhbReqd 0 "FALSE" 1 "TRUE" ;
VAL_ 1277 UpftrAllWndMtnReq 0 "No Request" 1 "Open Fully" 2 "Open Vent" 3 "Close Fully" ;
VAL_ 1277 UpftrVehRmtStrtupReq 0 "No Request" 1 "Engine Requested Off" 2 "Engine Requested On" ;
VAL_ 48 HVGI1P_PrplRltdBsHVAllwdPriAuth 0 "FALSE" 1 "TRUE" ;
VAL_ 48 HVGI1P_HVBatCntctrStsPriAuth 0 "Open" 1 "Precharge" 2 "Close" ;
VAL_ 48 HVGI1P_CntctrShtdnReqPriAuth 0 "None" 1 "Emergency Shutdown" 2 "Controlled Shutdown" 3 "Emergency Crash Shutdown" ;
VAL_ 48 ElcDischrgActr2DischrgCmdAuth 0 "NoAction" 1 "Normal" 2 "Immediate" 3 "Emergency" ;
VAL_ 48 HVGI7P_ESSPrplSysStsPriAuth 0 "Unavailable" 1 "Operational" 2 "ControlledShutdown" 3 "EmergencyShutdown" 4 "EmergencyCrash" 5 "Suspend Request" ;
VAL_ 48 HVGI7P_ESSPrplSysRespPriAuth 0 "Idle" 1 "Activating" 2 "Active" 3 "Deactivating" ;
VAL_ 1149 VirtKeyAllDrLckReqd 0 "FALSE" 1 "TRUE" ;
VAL_ 1149 VirtKeyPncReq 0 "No Request" 1 "Activate" 2 "Cancel" ;
VAL_ 1149 VirtKeyFobAvlReq 0 "No Request" 1 "Enable Fobs" 2 "Disable Fobs" ;
VAL_ 1149 VirtKeyRmtLctrReq 0 "No Request" 1 "Activate Low" 2 "Activate Medium" 3 "Activate High" 4 "Cancel" ;
VAL_ 1149 SRPCrsFrtInSftBtnMblDevSts 0 "Not Pressed" 1 "Pressed" ;
VAL_ 1149 SRPCrsBkInSftBtnMblDevSts 0 "Not Pressed" 1 "Pressed" ;
VAL_ 1149 VirtKeyRrClsrUnlckReqd 0 "FALSE" 1 "TRUE" ;
VAL_ 1149 VirtKeyRrClsrLckReqd 0 "FALSE" 1 "TRUE" ;
VAL_ 1149 VirtKeyFrtClsrUnlckReqd 0 "FALSE" 1 "TRUE" ;
VAL_ 1149 VirtKeyFrtClsrLckReqd 0 "FALSE" 1 "TRUE" ;
VAL_ 1149 VirtKeyDrvrDrUnlckReqd 0 "FALSE" 1 "TRUE" ;
VAL_ 1149 VirtKeyAllDrUnlckReqd 0 "FALSE" 1 "TRUE" ;
VAL_ 1149 SRPSrchingSftBtnMblDevSts 0 "Not Pressed" 1 "Pressed" ;
VAL_ 1149 SRPRtSftBtnMblDevSts 0 "Not Pressed" 1 "Pressed" ;
VAL_ 1149 SRPPrlllPrkSftBtnMblDevSts 0 "Not Pressed" 1 "Pressed" ;
VAL_ 1149 SRPLtSftBtnMblDevSts 0 "Not Pressed" 1 "Pressed" ;
VAL_ 1149 SRPExtPrkSftBtnMblDevSts 0 "Not Pressed" 1 "Pressed" ;
VAL_ 586 VirtKeyPwrTopCtlReqrMblDevIdfr 0 "Unknown" 1 "Mobile Device Identifier 1" 2 "Mobile Device Identifier 2" 3 "Mobile Device Identifier 3" 4 "Mobile Device Identifier 4" 5 "Mobile Device Identifier 5" 6 "Mobile Device Identifier 6" 7 "Mobile Device Identifier 7" 8 "Mobile Device Identifier 8" 9 "Mobile Device Identifier 9" 10 "Mobile Device Identifier 10" 11 "Mobile Device Identifier 11" 12 "Mobile Device Identifier 12" 13 "Mobile Device Identifier 13" 14 "Mobile Device Identifier 14" 15 "Mobile Device Identifier 15" ;
VAL_ 586 VirtKeyPwrTopCtlReq 0 "No Request" 1 "Open" 2 "Close" 3 "Stop" 4 "Pause" ;
VAL_ 586 VirtKeyPwrRrClsrCtlReq 0 "No Request" 1 "Start" 2 "Stop" 3 "Open" 4 "Close" ;
VAL_ 586 VirtKeyFrtClsrCtlReq 0 "No Request" 1 "Start" 2 "Stop" 3 "Release" 4 "Open" 5 "Close" ;
VAL_ 586 VirtKeyWndCtlReq 0 "No Request" 1 "Open Fully" 2 "Vent" 3 "Close Fully" ;
VAL_ 586 VirtKeyVehCbnACReq 0 "No Request" 1 "Activate" 2 "Cancel" ;
VAL_ 586 VirtKeySnrfCtlReq 0 "No Request" 1 "Open Fully" 2 "Vent" 3 "Close Fully" ;
VAL_ 586 SRPMblDevDctvBtnSts 0 "Not Pressed" 1 "Pressed" ;
VAL_ 586 VirtKeyVehCbnACTempLvlReqActv 0 "FALSE" 1 "TRUE" ;
VAL_ 586 VirtKeyRrClsrRelReqd 0 "FALSE" 1 "TRUE" ;
VAL_ 591 ElecDrvUnt3DrvUntPrplSecSts 0 "Inactive" 1 "Active" 2 "Transitional" ;
VAL_ 590 ElecDrvUnt2DrvUntPrplSecSts 0 "Inactive" 1 "Active" 2 "Transitional" ;
VAL_ 588 ElecDrvUnt3DrvUntPrplSecCmd 0 "Disable" 1 "Enable" ;
VAL_ 588 ElecDrvUnt2DrvUntPrplSecCmd 0 "Disable" 1 "Enable" ;
VAL_ 1446 ACRefrigLoSdFPSCktFABndl 0 "FALSE" 1 "TRUE" ;
VAL_ 1446 ACRefrigLoSdFldPrsVal_Inv 0 "FALSE" 1 "TRUE" ;
VAL_ 1446 HVGI11_PwrElecCoolLoopTemp_Inv 0 "FALSE" 1 "TRUE" ;
VAL_ 1446 HVGI11_PwrElecCoolLoopTemp_DuD 0 "FALSE" 1 "TRUE" ;
VAL_ 1446 AltTxPrplSysOffTm_Inv 0 "FALSE" 1 "TRUE" ;
VAL_ 1446 AltTxPrplSysOffTm_DuD 0 "FALSE" 1 "TRUE" ;
VAL_ 587 SuprRmtPrkFricBrkTrqReqTyp 0 "No Action" 1 "Braking Not Requested" 2 "Brake Per Torque" 3 "Hold" ;
VAL_ 587 SuprRmtPrkElecPrkBrkReq 0 "No Request" 1 "Apply" 2 "Release" ;
VAL_ 587 SuprRmtPrkPrplSysActvnReqd 0 "FALSE" 1 "TRUE" ;
VAL_ 1145 ClmCtlCbnMaxDefrReqOn_Inv 0 "FALSE" 1 "TRUE" ;
VAL_ 1145 ClmCtlCbnMaxDefrReqOn 0 "FALSE" 1 "TRUE" ;
VAL_ 1145 ClmCtlCbnFrtRtTempSet_Inv 0 "FALSE" 1 "TRUE" ;
VAL_ 1145 ClmCtlCbnFrtLtTempSet_Inv 0 "FALSE" 1 "TRUE" ;
VAL_ 1145 ClmCtlCbnEvpAirOutTemp_Inv 0 "FALSE" 1 "TRUE" ;
VAL_ 873 BSIR2P_BrkgSysVhTpSpLmRqTypAuth 0 "Inactive" 1 "OBD" ;
VAL_ 873 BSIR2P_BSPriVehTpSpLimRqTypAuth 0 "Inactive" 1 "Faulted" 2 "Safety_woBrake" 3 "Safety_wBrake" 4 "OBD" 5 "nonOBD" 6 "Legislated" ;
VAL_ 873 BSIR2P_BSPriVehTpSpLimRqSrcAuth 0 "None" 1 "eBoost" 2 "ESC" ;
VAL_ 873 BSISP_ESCActvAuth 0 "FALSE" 1 "TRUE" ;
VAL_ 873 BSISP_TCSFaildAuth 0 "FALSE" 1 "TRUE" ;
VAL_ 873 BSISP_TCSDrvrIntntAuth 0 "Disabled" 1 "Enabled" ;
VAL_ 873 BSISP_TCSActvAuth 0 "FALSE" 1 "TRUE" ;
VAL_ 873 BSISP_ETRSHydrlcBrkgStsAuth 0 "Not Active" 1 "Active" 2 "Failed" ;
VAL_ 873 BSISP_ESCSysStsAuth 0 "Normal Operation" 1 "Failed" 2 "Initializing" 3 "Enhanced Operation" 4 "Driver Disable" ;
VAL_ 873 DMCP_VehSpdLimFricBrkStsAuth 0 "Inactive" 1 "Active" 2 "Not available" ;
VAL_ 873 DMCP_AWDPerfModeReqAuth 0 "No Action" 1 "Normal" 2 "Sport" 3 "Track/Baja" 4 "Winter" 5 "Off Road" 6 "Terrain" 7 "Disconnect" ;
VAL_ 873 BrkgSysVehTopSpdLimIndOnAuth 0 "FALSE" 1 "TRUE" ;
VAL_ 635 EPBSP_ElecPrkBrkAvlStsAuth 0 "Unavailable" 1 "Available" 2 "Failed" ;
VAL_ 635 EPBSP_ElecPrkBrkApplStsAuth 0 "Unknown" 1 "Applied" 2 "Released" 3 "Dynamic Apply" 4 "In-Progress" ;
VAL_ 635 EPBSP_EPBSysBrkLgtsReqdAuth 0 "FALSE" 1 "TRUE" ;
VAL_ 635 EPBSP_BrkSysBrkLgtsReqdAuth 0 "FALSE" 1 "TRUE" ;
VAL_ 635 DMCP_EnvIdRsp2Auth 0 "FALSE" 1 "TRUE" ;
VAL_ 635 TBIP_TrlrBrkDsbldIndOnAuth 0 "FALSE" 1 "TRUE" ;
VAL_ 635 TBIP_ServTrlrBrkgSysIndOnAuth 0 "FALSE" 1 "TRUE" ;
VAL_ 635 TBIP_CkTrlrIndOnAuth 0 "FALSE" 1 "TRUE" ;
VAL_ 635 EPBSP_TrlrBrkgSysBrkLgtsRqdAuth 0 "FALSE" 1 "TRUE" ;
VAL_ 635 TBIP_TrlrWrgFltIndOnAuth 0 "FALSE" 1 "TRUE" ;
VAL_ 635 TBIP_TrlrBrkgGainSetIndOnAuth 0 "FALSE" 1 "TRUE" ;
VAL_ 635 ElecPrkBrkMnPriPerfRdcd 0 "FALSE" 1 "TRUE" ;
VAL_ 635 TrlrBrkgRdcdIndOn 0 "FALSE" 1 "TRUE" ;
VAL_ 635 TrlrBrkgHldLstKnwnGainIndOn 0 "FALSE" 1 "TRUE" ;
VAL_ 644 AASILASStrgReqLnFllwgRrStrgInhb 0 "FALSE" 1 "TRUE" ;
VAL_ 644 AASILASStrgReqSts 0 "Unknown" 1 "Active" 2 "Inactive" ;
VAL_ 644 AASILASStrgReqAFtr 0 "None" 1 "Collision Avoidance Steeering" 2 "Traffic Jam Assist" 3 "Lane Centering and Control" 4 "Hands-On Lane Following" 5 "Steering Angle Assist" 6 "Lane Keep Assist" 7 "Lane Change on Demand" 8 "Lateral Collision Prevention" ;
VAL_ 644 AASILASStrgReqTyp 0 "Torque" 1 "Angle" ;
VAL_ 602 LnDtnWrnCtlTrqOvrlyReqActv_Inv 0 "FALSE" 1 "TRUE" ;
VAL_ 602 LnDtnWrnCtlTrqOvrlyReqActv_DuD 0 "FALSE" 1 "TRUE" ;
VAL_ 602 LnDtnWrnCtlTrqOvrlyReqActv 0 "Active" 1 "Inactive" ;
VAL_ 602 LnDtnWrnCtlHRTrqOvrlyReqVal_Inv 0 "FALSE" 1 "TRUE" ;
VAL_ 602 LnDtnWrnCtlHRTrqOvrlyReqVal_DuD 0 "FALSE" 1 "TRUE" ;
VAL_ 171 SpnsnPstnOfstFromTrmRR_Inv 0 "FALSE" 1 "TRUE" ;
VAL_ 171 SpnsnPstnOfstFromTrmRF_Inv 0 "FALSE" 1 "TRUE" ;
VAL_ 171 SpnsnPstnOfstFromTrmLR_Inv 0 "FALSE" 1 "TRUE" ;
VAL_ 171 SpnsnPstnOfstFromTrmLF_Inv 0 "FALSE" 1 "TRUE" ;
VAL_ 749 SecGridBatVltgCtlOvrrdActv 0 "FALSE" 1 "TRUE" ;
VAL_ 749 PriVehChlrOutCoolTemp_Inv 0 "FALSE" 1 "TRUE" ;
VAL_ 749 PriVehThrmlSysFltStat 0 "No Fault" 1 "Failed" 2 "Degraded Operation" ;
VAL_ 749 APM2Sts 0 "NormConvNormTempLo" 1 "NormConvNormTempHi" 2 "Derated" 3 "HighTempNearDerated" 4 "Dsbld" 5 "HiTempDsbldDerated" 6 "Indeterminate" 7 "CommandedOff" 8 "OverTempConvDerated" ;
VAL_ 747 FOE46ecGrdVltgOvrrdPrty 0 "None" 1 "Low" 2 "Medium" 3 "High" ;
VAL_ 59 BSIRP_AutoBrkgPTReqStsAuth 0 "Inactive" 1 "Active" 2 "Failed" 3 "Serial Communication Failure" ;
VAL_ 59 BSIRP_AdpCruzHldActvAuth 0 "FALSE" 1 "TRUE" ;
VAL_ 59 BSIRP_ChsSysAxlTqRqRspTpAuth 0 "Inactive" 1 "Pleasability Limited Request" 2 "Maximum Range Request" 3 "Automatic Actuator Selection" 4 "Braking Torque Request" ;
VAL_ 59 BSIRP_ChsSysAxlTqRqFncAuth 0 "None" 1 "Engine Drag Control" 2 "Traction control" 3 "Electronic Stability Control" 4 "Active safety braking" 5 "Driveline protection" 6 "Power Hop" 7 "Performance Traction Control" 8 "Hill Descent Control" 9 "Advanced Park Assist" 10 "Brake System Cruise Control" 11 "Torque Vectoring" 12 "Launch Control" 13 "Line Lock" 14 "Regenerative Torque Limitation" ;
VAL_ 59 BSIRP_ChsSysPrdAxlTqRqItvTpAuth 0 "No Intervention" 1 "Maximum Limit" 2 "Minimum Limit" 3 "Minimum and Maximum Limit" ;
VAL_ 59 BrkAsstHalfSysBstFaildCktAuth 0 "None" 1 "Front / Front" 2 "Rear / Rear" 3 "Left Front / Right Rear" 4 "Right Front / Left Rear" ;
VAL_ 59 BSIRP_RrVirtBmpInhbAuth 0 "FALSE" 1 "TRUE" ;
VAL_ 59 BSIRP_HillDscntCtlStsAuth 0 "Not Enabled" 1 "Enabled" 2 "Active" ;
VAL_ 59 BSIRP_DrvrSeltdHldEnbldAuth 0 "FALSE" 1 "TRUE" ;
VAL_ 59 BSIRP_DrvrSeltdHldActvAuth 0 "FALSE" 1 "TRUE" ;
VAL_ 59 BSIRP_ClsnPrepSysInhbAuth 0 "FALSE" 1 "TRUE" ;
VAL_ 59 BrkSysSpltFricCoefBrkgActvAuth 0 "FALSE" 1 "TRUE" ;
VAL_ 59 BrkSysSpltFricCoefAccelActvAuth 0 "FALSE" 1 "TRUE" ;
VAL_ 59 CBIP_ACCBrkgStsAuth 0 "Not Active" 1 "Active" 2 "Failed" ;
VAL_ 59 CBIP_ACCBrkgActvAuth 0 "FALSE" 1 "TRUE" ;
VAL_ 59 CBIP_ClsnImntBrkgStsAuth 0 "Not Active" 1 "Active" 2 "Failed" ;
VAL_ 59 CBIP_BrkPedPstnEmsRltdAuth_Inv 0 "FALSE" 1 "TRUE" ;
VAL_ 59 CSATRP_PriATReqFncAuth 0 "None" 1 "Engine Drag Control" 2 "Traction control" 3 "Electronic Stability Control" 4 "Driveline Protection" 5 "Power Hop" 6 "Performance Traction Control" 7 "Torque Vectoring" 8 "Launch Control" 9 "Line Lock" 10 "Regenerative Torque Limitation" ;
VAL_ 59 CBIP_EPBCruzCtlCnclReqAuth 0 "FALSE" 1 "TRUE" ;
VAL_ 59 CBIP_DrvrIndpntBrkAppActvAuth 0 "FALSE" 1 "TRUE" ;
VAL_ 59 CBIP_ClsnImntDrvrBrkPedOvrdAuth 0 "FALSE" 1 "TRUE" ;
VAL_ 59 CSATRP_PriATReqIntvTypPrdtdAuth 0 "No Intervention" 1 "Maximum Limit" 2 "Minimum Limit" 3 "Minimum and Maximum Limit" ;
VAL_ 59 CSATRP_SecATReqFncAuth 0 "None" 1 "Engine Drag Control" 2 "Traction control" 3 "Electronic Stability Control" 4 "Driveline Protection" 5 "Power Hop" 6 "Performance Traction Control" 7 "Torque Vectoring" 8 "Launch Control" 9 "Line Lock" 10 "Regenerative Torque Limitation" ;
VAL_ 59 CSATRP_SecATIntvTypPrdtdAuth 0 "No Intervention" 1 "Maximum Limit" 2 "Minimum Limit" 3 "Minimum and Maximum Limit" ;
VAL_ 59 CSATRP_PriATReqRespTypAuth 0 "Inactive" 1 "Pleasability Limited Request" 2 "Maximum Range Request" 3 "Automatic Actuator Selection" 4 "Braking Torque Request" ;
VAL_ 59 CSATRP_SecATReqRespTypAuth 0 "Inactive" 1 "Pleasability Limited Request" 2 "Maximum Range Request" 3 "Automatic Actuator Selection" 4 "Braking Torque Request" ;
VAL_ 59 CSBTP_ChsSysTtBrkAxTqVlAuth_Inv 0 "FALSE" 1 "TRUE" ;
VAL_ 59 FWDECP_LFAuth_Inv 0 "FALSE" 1 "TRUE" ;
VAL_ 59 PTP_EngSpdIntvTypAuth 0 "No Intervention" 1 "Engine Speed Maximum Limit" ;
VAL_ 59 PTP_EngSpdCtlRespAuth 0 "No Suggestion" 1 "Transient Optimized" 2 "Stability Optimized Condition 1" 3 "Stability Optimized Condition 2" ;
VAL_ 59 PTP_DCTLaunchCtlActvAuth 0 "FALSE" 1 "TRUE" ;
VAL_ 59 FWDECP_RstOccAuth 0 "FALSE" 1 "TRUE" ;
VAL_ 59 FWDECP_RFAuth_Inv 0 "FALSE" 1 "TRUE" ;
VAL_ 59 RALTCRP_TypAuth 0 "No Action" 1 "Maximum Allowed Torque" 2 "Minimum Allowed Torque" 3 "Control to Requested Torque" ;
VAL_ 59 RWDECP_LRAuth_Inv 0 "FALSE" 1 "TRUE" ;
VAL_ 59 RWDECP_RRAuth_Inv 0 "FALSE" 1 "TRUE" ;
VAL_ 59 RWDECP_RstOccAuth 0 "FALSE" 1 "TRUE" ;
VAL_ 59 TCTR1P_AxlTrqReqTypRRAuth 0 "No Action" 1 "Maximum Allowed Torque" 2 "Minimum Allowed Torque" 3 "Control To Requested Torque" ;
VAL_ 59 TCTR1P_AxlTrqReqTypLRAuth 0 "No Action" 1 "Maximum Allowed Torque" 2 "Minimum Allowed Torque" 3 "Control To Requested Torque" ;
VAL_ 59 WhlAngVelLFrtAuth_Inv 0 "FALSE" 1 "TRUE" ;
VAL_ 59 WhlAngVelLRrAuth_Inv 0 "FALSE" 1 "TRUE" ;
VAL_ 59 WhlAngVelRFrtAuth_Inv 0 "FALSE" 1 "TRUE" ;
VAL_ 59 WhlBrkPresAuth_Inv 0 "FALSE" 1 "TRUE" ;
VAL_ 59 WhlAngVelRRrAuth_Inv 0 "FALSE" 1 "TRUE" ;
VAL_ 59 ChsSysPriAxlLtTqRqIntvTpAuth 0 "No Intervention" 1 "Maximum Limit" 2 "Minimum Limit" 3 "Minimum and Maximum Limit" ;
VAL_ 59 ChsSysPriAxlRtTqRqIntvTpAuth 0 "No Intervention" 1 "Maximum Limit" 2 "Minimum Limit" 3 "Minimum and Maximum Limit" ;
VAL_ 59 ChsSysPriAxlLtTrqReqFncAuth 0 "None" 1 "Engine Drag Control" 2 "Traction Control" 3 "Electronic Stability Control" 4 "Driveline Protection" 5 "Power Hop" 6 "Performance Traction Control" 7 "Torque Vectoring" 8 "Launch Control" 9 "Line Lock" 10 "Regenerative Torque Limitation" ;
VAL_ 59 ChsSysPrplSysFricBrkTqRqStsAuth 0 "Unknown" 1 "Not Active" 2 "Friction Braking Active" 3 "Hold Active" 4 "Failed" ;
VAL_ 59 ChsSysPriAxlRtTrqReqFncAuth 0 "None" 1 "Engine Drag Control" 2 "Traction Control" 3 "Electronic Stability Control" 4 "Driveline Protection" 5 "Power Hop" 6 "Performance Traction Control" 7 "Torque Vectoring" 8 "Launch Control" 9 "Line Lock" 10 "Regenerative Torque Limitation" ;
VAL_ 59 BrkSysBrkTrqSfcntStndstl 0 "FALSE" 1 "TRUE" ;
VAL_ 59 VehDynOvrstrUndrstrVal_Inv 0 "FALSE" 1 "TRUE" ;
VAL_ 1290 Sig0539 0 "Idle" 1 "Active" 2 "Complete" 3 "Aborted" ;
VAL_ 1290 Sig0538 0 "None" 1 "Self Test" 2 "Primary Brake Module" 3 "Secondary Brake Module" 4 "External" 5 "Autonomous" ;
VAL_ 1286 Sig0454 0 "None" 1 "PBM Basic Functional Test" 2 "PBM Enhanced Functional Test" 3 "Operational Safety Integrity Check" ;
VAL_ 1308 BSSIP_PerfTracMgmtEnbldAuth 0 "FALSE" 1 "TRUE" ;
VAL_ 1308 BSSIP_LnchCtlModeStsAuth 0 "Disable" 1 "General" 2 "General Custom" 3 "High Traction" 4 "High Traction Custom" 5 "Line Lock" 6 "Line Lock Press Brake" 7 "Line Lock Release Brake" ;
VAL_ 1308 BSSIP_BrkAsstBrkBstStsAuth 0 "No Boost" 1 "Normal Boost" 2 "Boost with Warning" 3 "Shut Down Boost" 4 "No Boost EPB Assist" 5 "Hydraulic Leak Detection" 6 "Half System Boost" 7 "Diagnostic Mode" 8 "Brake Fade 1" 9 "Brake Fade 2" ;
VAL_ 1308 BrkSysBrkFldLvlHiIntegSts 0 "Unknown" 1 "Normal" 2 "Low" 3 "Critically Low" ;
VAL_ 1308 ChsDynoModeEnbld 0 "FALSE" 1 "TRUE" ;
VAL_ 172 Sig5884 0 "Has Never Moved" 1 "Has Moved But Currently Stopped" 2 "Moving In Same Direction As Host" 3 "Moving In Opposite Direction As Host" 4 "Crossing Path" ;
VAL_ 172 Sig5883 0 "Highly Speculative" 1 "Speculative" 2 "Confident" 3 "Highly Confident" ;
VAL_ 172 Sig5887 0 "No Object" 1 "New Object" 2 "Latent Track Not Detected this Cycle" 3 "Measured this Cycle" ;
VAL_ 172 Sig5895 0 "Highly Speculative" 1 "Speculative" 2 "Confident" 3 "Highly Confident" ;
VAL_ 172 Sig5894 0 "Unknown" 1 "Pedestrian" 2 "Bicycle" ;
VAL_ 172 Sig5999 0 "Stopped" 1 "Not Stopped" ;
VAL_ 172 Sig5998 0 "Has Never Moved" 1 "Moving In Same Direction As Host" 2 "Moving In Opposite Direction As Host" 3 "Crossing From Left To Right" 4 "Crossing From Right To Left" ;
VAL_ 172 Sig5997 0 "Highly Speculative" 1 "Speculative" 2 "Confident" 3 "Highly Confident" ;
VAL_ 172 Sig6001 0 "No Object" 1 "New Object" 2 "Latent Track Not Detected this Cycle" 3 "Measured this Cycle" ;
VAL_ 172 Sig6015 0 "Highly Speculative" 1 "Speculative" 2 "Confident" 3 "Highly Confident" ;
VAL_ 172 Sig6017 0 "Highly Speculative" 1 "Speculative" 2 "Confident" 3 "Highly Confident" ;
VAL_ 172 Sig6019 0 "Stopped" 1 "Not Stopped" ;
VAL_ 172 Sig6018 0 "Has Never Moved" 1 "Moving In Same Direction As Host" 2 "Moving In Opposite Direction As Host" 3 "Crossing From Left To Right" 4 "Crossing From Right To Left" ;
VAL_ 172 Sig6021 0 "No Object" 1 "New Object" 2 "Latent Track Not Detected this Cycle" 3 "Measured this Cycle" ;
VAL_ 172 Sig6035 0 "Highly Speculative" 1 "Speculative" 2 "Confident" 3 "Highly Confident" ;
VAL_ 172 Sig6039 0 "Stopped" 1 "Not Stopped" ;
VAL_ 172 Sig6038 0 "Has Never Moved" 1 "Moving In Same Direction As Host" 2 "Moving In Opposite Direction As Host" 3 "Crossing From Left To Right" 4 "Crossing From Right To Left" ;
VAL_ 172 Sig6037 0 "Highly Speculative" 1 "Speculative" 2 "Confident" 3 "Highly Confident" ;
VAL_ 172 Sig6041 0 "No Object" 1 "New Object" 2 "Latent Track Not Detected this Cycle" 3 "Measured this Cycle" ;
VAL_ 172 Sig6055 0 "Highly Speculative" 1 "Speculative" 2 "Confident" 3 "Highly Confident" ;
VAL_ 170 Sig5897 0 "Has Never Moved" 1 "Has Moved But Currently Stopped" 2 "Moving In Same Direction As Host" 3 "Moving In Opposite Direction As Host" 4 "Crossing Path" ;
VAL_ 170 Sig5896 0 "Highly Speculative" 1 "Speculative" 2 "Confident" 3 "Highly Confident" ;
VAL_ 170 Sig5900 0 "No Object" 1 "New Object" 2 "Latent Track Not Detected this Cycle" 3 "Measured this Cycle" ;
VAL_ 170 Sig5908 0 "Highly Speculative" 1 "Speculative" 2 "Confident" 3 "Highly Confident" ;
VAL_ 170 Sig5907 0 "Unknown" 1 "Pedestrian" 2 "Bicycle" ;
VAL_ 170 Sig6059 0 "Stopped" 1 "Not Stopped" ;
VAL_ 170 Sig6058 0 "Has Never Moved" 1 "Moving In Same Direction As Host" 2 "Moving In Opposite Direction As Host" 3 "Crossing From Left To Right" 4 "Crossing From Right To Left" ;
VAL_ 170 Sig6057 0 "Highly Speculative" 1 "Speculative" 2 "Confident" 3 "Highly Confident" ;
VAL_ 170 Sig6061 0 "No Object" 1 "New Object" 2 "Latent Track Not Detected this Cycle" 3 "Measured this Cycle" ;
VAL_ 170 Sig6075 0 "Highly Speculative" 1 "Speculative" 2 "Confident" 3 "Highly Confident" ;
VAL_ 170 Sig6077 0 "Highly Speculative" 1 "Speculative" 2 "Confident" 3 "Highly Confident" ;
VAL_ 170 Sig6079 0 "Stopped" 1 "Not Stopped" ;
VAL_ 170 Sig6078 0 "Has Never Moved" 1 "Moving In Same Direction As Host" 2 "Moving In Opposite Direction As Host" 3 "Crossing From Left To Right" 4 "Crossing From Right To Left" ;
VAL_ 170 Sig6081 0 "No Object" 1 "New Object" 2 "Latent Track Not Detected this Cycle" 3 "Measured this Cycle" ;
VAL_ 170 Sig6095 0 "Highly Speculative" 1 "Speculative" 2 "Confident" 3 "Highly Confident" ;
VAL_ 170 Sig6099 0 "Stopped" 1 "Not Stopped" ;
VAL_ 170 Sig6098 0 "Has Never Moved" 1 "Moving In Same Direction As Host" 2 "Moving In Opposite Direction As Host" 3 "Crossing From Left To Right" 4 "Crossing From Right To Left" ;
VAL_ 170 Sig6097 0 "Highly Speculative" 1 "Speculative" 2 "Confident" 3 "Highly Confident" ;
VAL_ 170 Sig6101 0 "No Object" 1 "New Object" 2 "Latent Track Not Detected this Cycle" 3 "Measured this Cycle" ;
VAL_ 170 Sig6115 0 "Highly Speculative" 1 "Speculative" 2 "Confident" 3 "Highly Confident" ;
VAL_ 169 Sig5910 0 "Has Never Moved" 1 "Has Moved But Currently Stopped" 2 "Moving In Same Direction As Host" 3 "Moving In Opposite Direction As Host" 4 "Crossing Path" ;
VAL_ 169 Sig5909 0 "Highly Speculative" 1 "Speculative" 2 "Confident" 3 "Highly Confident" ;
VAL_ 169 Sig5913 0 "No Object" 1 "New Object" 2 "Latent Track Not Detected this Cycle" 3 "Measured this Cycle" ;
VAL_ 169 Sig5921 0 "Highly Speculative" 1 "Speculative" 2 "Confident" 3 "Highly Confident" ;
VAL_ 169 Sig5920 0 "Unknown" 1 "Pedestrian" 2 "Bicycle" ;
VAL_ 169 Sig5959 0 "Stopped" 1 "Not Stopped" ;
VAL_ 169 Sig5958 0 "Has Never Moved" 1 "Moving In Same Direction As Host" 2 "Moving In Opposite Direction As Host" 3 "Crossing From Left To Right" 4 "Crossing From Right To Left" ;
VAL_ 169 Sig5957 0 "Highly Speculative" 1 "Speculative" 2 "Confident" 3 "Highly Confident" ;
VAL_ 169 Sig5961 0 "No Object" 1 "New Object" 2 "Latent Track Not Detected this Cycle" 3 "Measured this Cycle" ;
VAL_ 169 Sig5975 0 "Highly Speculative" 1 "Speculative" 2 "Confident" 3 "Highly Confident" ;
VAL_ 169 Sig6117 0 "Highly Speculative" 1 "Speculative" 2 "Confident" 3 "Highly Confident" ;
VAL_ 169 Sig6119 0 "Stopped" 1 "Not Stopped" ;
VAL_ 169 Sig6118 0 "Has Never Moved" 1 "Moving In Same Direction As Host" 2 "Moving In Opposite Direction As Host" 3 "Crossing From Left To Right" 4 "Crossing From Right To Left" ;
VAL_ 169 Sig6121 0 "No Object" 1 "New Object" 2 "Latent Track Not Detected this Cycle" 3 "Measured this Cycle" ;
VAL_ 169 Sig6135 0 "Highly Speculative" 1 "Speculative" 2 "Confident" 3 "Highly Confident" ;
VAL_ 169 Sig6139 0 "Stopped" 1 "Not Stopped" ;
VAL_ 169 Sig6138 0 "Has Never Moved" 1 "Moving In Same Direction As Host" 2 "Moving In Opposite Direction As Host" 3 "Crossing From Left To Right" 4 "Crossing From Right To Left" ;
VAL_ 169 Sig6137 0 "Highly Speculative" 1 "Speculative" 2 "Confident" 3 "Highly Confident" ;
VAL_ 169 Sig6141 0 "No Object" 1 "New Object" 2 "Latent Track Not Detected this Cycle" 3 "Measured this Cycle" ;
VAL_ 169 Sig6155 0 "Highly Speculative" 1 "Speculative" 2 "Confident" 3 "Highly Confident" ;
VAL_ 167 Sig5777 0 "Not Elevated" 1 "Elevation Speculative" 2 "Elevation Confident" 3 "Elevation Very Confident" ;
VAL_ 167 Sig5776 0 "Highly Speculative" 1 "Speculative" 2 "Confident" 3 "Highly Confident" ;
VAL_ 167 Sig5779 0 "No Object" 1 "New Object" 2 "Latent Track Not Detected this Cycle" 3 "Measured this Cycle" ;
VAL_ 167 Sig5783 0 "Highly Speculative" 1 "Speculative" 2 "Confident" 3 "Highly Confident" ;
VAL_ 167 Sig5782 0 "Unknown" 1 "Guard Rail" 2 "Tunnel" 3 "Traffic Sign" 4 "Bridge" 5 "Pole" ;
VAL_ 167 Sig5785 0 "Not Elevated" 1 "Elevation Speculative" 2 "Elevation Confident" 3 "Elevation Very Confident" ;
VAL_ 167 Sig5784 0 "Highly Speculative" 1 "Speculative" 2 "Confident" 3 "Highly Confident" ;
VAL_ 167 Sig5787 0 "No Object" 1 "New Object" 2 "Latent Track Not Detected this Cycle" 3 "Measured this Cycle" ;
VAL_ 167 Sig5792 0 "Highly Speculative" 1 "Speculative" 2 "Confident" 3 "Highly Confident" ;
VAL_ 167 Sig5791 0 "Highly Speculative" 1 "Speculative" 2 "Confident" 3 "Highly Confident" ;
VAL_ 167 Sig5790 0 "Unknown" 1 "Guard Rail" 2 "Tunnel" 3 "Traffic Sign" 4 "Bridge" 5 "Pole" ;
VAL_ 167 Sig5793 0 "Not Elevated" 1 "Elevation Speculative" 2 "Elevation Confident" 3 "Elevation Very Confident" ;
VAL_ 167 Sig5795 0 "No Object" 1 "New Object" 2 "Latent Track Not Detected this Cycle" 3 "Measured this Cycle" ;
VAL_ 167 Sig5798 0 "Unknown" 1 "Guard Rail" 2 "Tunnel" 3 "Traffic Sign" 4 "Bridge" 5 "Pole" ;
VAL_ 167 Sig5801 0 "Not Elevated" 1 "Elevation Speculative" 2 "Elevation Confident" 3 "Elevation Very Confident" ;
VAL_ 167 Sig5800 0 "Highly Speculative" 1 "Speculative" 2 "Confident" 3 "Highly Confident" ;
VAL_ 167 Sig5799 0 "Highly Speculative" 1 "Speculative" 2 "Confident" 3 "Highly Confident" ;
VAL_ 167 Sig5803 0 "No Object" 1 "New Object" 2 "Latent Track Not Detected this Cycle" 3 "Measured this Cycle" ;
VAL_ 167 Sig5807 0 "Highly Speculative" 1 "Speculative" 2 "Confident" 3 "Highly Confident" ;
VAL_ 167 Sig5806 0 "Unknown" 1 "Guard Rail" 2 "Tunnel" 3 "Traffic Sign" 4 "Bridge" 5 "Pole" ;
VAL_ 167 Sig5809 0 "Not Elevated" 1 "Elevation Speculative" 2 "Elevation Confident" 3 "Elevation Very Confident" ;
VAL_ 167 Sig5808 0 "Highly Speculative" 1 "Speculative" 2 "Confident" 3 "Highly Confident" ;
VAL_ 167 Sig5811 0 "No Object" 1 "New Object" 2 "Latent Track Not Detected this Cycle" 3 "Measured this Cycle" ;
VAL_ 167 Sig5817 0 "Not Elevated" 1 "Elevation Speculative" 2 "Elevation Confident" 3 "Elevation Very Confident" ;
VAL_ 167 Sig5816 0 "Highly Speculative" 1 "Speculative" 2 "Confident" 3 "Highly Confident" ;
VAL_ 167 Sig5815 0 "Highly Speculative" 1 "Speculative" 2 "Confident" 3 "Highly Confident" ;
VAL_ 167 Sig5814 0 "Unknown" 1 "Guard Rail" 2 "Tunnel" 3 "Traffic Sign" 4 "Bridge" 5 "Pole" ;
VAL_ 167 Sig5819 0 "No Object" 1 "New Object" 2 "Latent Track Not Detected this Cycle" 3 "Measured this Cycle" ;
VAL_ 167 Sig5822 0 "Unknown" 1 "Guard Rail" 2 "Tunnel" 3 "Traffic Sign" 4 "Bridge" 5 "Pole" ;
VAL_ 167 Sig5825 0 "Not Elevated" 1 "Elevation Speculative" 2 "Elevation Confident" 3 "Elevation Very Confident" ;
VAL_ 167 Sig5824 0 "Highly Speculative" 1 "Speculative" 2 "Confident" 3 "Highly Confident" ;
VAL_ 167 Sig5823 0 "Highly Speculative" 1 "Speculative" 2 "Confident" 3 "Highly Confident" ;
VAL_ 167 Sig5827 0 "No Object" 1 "New Object" 2 "Latent Track Not Detected this Cycle" 3 "Measured this Cycle" ;
VAL_ 167 Sig5832 0 "Highly Speculative" 1 "Speculative" 2 "Confident" 3 "Highly Confident" ;
VAL_ 167 Sig5831 0 "Highly Speculative" 1 "Speculative" 2 "Confident" 3 "Highly Confident" ;
VAL_ 167 Sig5830 0 "Unknown" 1 "Guard Rail" 2 "Tunnel" 3 "Traffic Sign" 4 "Bridge" 5 "Pole" ;
VAL_ 167 Sig5833 0 "Not Elevated" 1 "Elevation Speculative" 2 "Elevation Confident" 3 "Elevation Very Confident" ;
VAL_ 167 Sig5835 0 "No Object" 1 "New Object" 2 "Latent Track Not Detected this Cycle" 3 "Measured this Cycle" ;
VAL_ 167 Sig5838 0 "Unknown" 1 "Guard Rail" 2 "Tunnel" 3 "Traffic Sign" 4 "Bridge" 5 "Pole" ;
VAL_ 167 Sig5841 0 "Not Elevated" 1 "Elevation Speculative" 2 "Elevation Confident" 3 "Elevation Very Confident" ;
VAL_ 167 Sig5840 0 "Highly Speculative" 1 "Speculative" 2 "Confident" 3 "Highly Confident" ;
VAL_ 167 Sig5839 0 "Highly Speculative" 1 "Speculative" 2 "Confident" 3 "Highly Confident" ;
VAL_ 167 Sig5843 0 "No Object" 1 "New Object" 2 "Latent Track Not Detected this Cycle" 3 "Measured this Cycle" ;
VAL_ 167 Sig5847 0 "Highly Speculative" 1 "Speculative" 2 "Confident" 3 "Highly Confident" ;
VAL_ 167 Sig5846 0 "Unknown" 1 "Guard Rail" 2 "Tunnel" 3 "Traffic Sign" 4 "Bridge" 5 "Pole" ;
VAL_ 167 Sig5849 0 "Not Elevated" 1 "Elevation Speculative" 2 "Elevation Confident" 3 "Elevation Very Confident" ;
VAL_ 167 Sig5848 0 "Highly Speculative" 1 "Speculative" 2 "Confident" 3 "Highly Confident" ;
VAL_ 167 Sig5851 0 "No Object" 1 "New Object" 2 "Latent Track Not Detected this Cycle" 3 "Measured this Cycle" ;
VAL_ 167 Sig5855 0 "Highly Speculative" 1 "Speculative" 2 "Confident" 3 "Highly Confident" ;
VAL_ 167 Sig5854 0 "Unknown" 1 "Guard Rail" 2 "Tunnel" 3 "Traffic Sign" 4 "Bridge" 5 "Pole" ;
